VERSION ""

NS_ :

BS_:

BU_: VCU_LE CHUD_LE VKM_LE RCRM_LE VPM_LE EDI_LE V2V_LE TCP_LE CSM_LE UHP_Low_LE TouchPad_LE RSE_LE RSC_LE RSA_LE PDIM_LE OTIM_LE ICS_LE LVMPC_LE LVMNav_LE DVB_T_LE ONSTAR_LE HUD_LE IPC_LE RadioHead_LE CHM_LE Dummy_LE CGM_LE AMP_LE

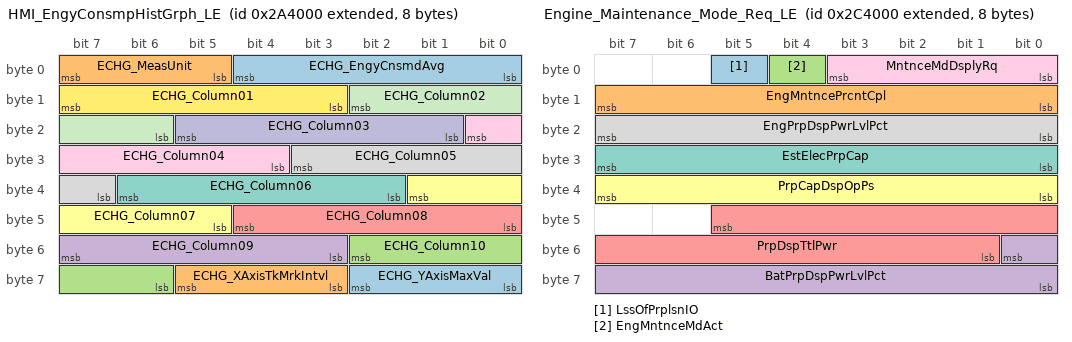
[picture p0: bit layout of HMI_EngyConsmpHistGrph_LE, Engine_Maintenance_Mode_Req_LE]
BO_ 2150252544 HMI_EngyConsmpHistGrph_LE: 8 CGM_LE
 SG_ ECHG_YAxisMaxVal : 58|3@0+ (1,0) [0|7] ""  VCU_LE,CSM_LE,RadioHead_LE
 SG_ ECHG_XAxisTkMrkIntvl : 61|3@0+ (1,0) [0|7] ""  VCU_LE,CSM_LE,RadioHead_LE
 SG_ ECHG_Column10 : 50|5@0+ (1,0) [0|31] ""  VCU_LE,CSM_LE,RadioHead_LE
 SG_ ECHG_Column09 : 55|5@0+ (1,0) [0|31] ""  VCU_LE,CSM_LE,RadioHead_LE
 SG_ ECHG_Column08 : 44|5@0+ (1,0) [0|31] ""  VCU_LE,CSM_LE,RadioHead_LE
 SG_ ECHG_Column07 : 33|5@0+ (1,0) [0|31] ""  VCU_LE,CSM_LE,RadioHead_LE
 SG_ ECHG_Column06 : 38|5@0+ (1,0) [0|31] ""  VCU_LE,CSM_LE,RadioHead_LE
 SG_ ECHG_Column05 : 27|5@0+ (1,0) [0|31] ""  VCU_LE,CSM_LE,RadioHead_LE
 SG_ ECHG_Column04 : 16|5@0+ (1,0) [0|31] ""  VCU_LE,CSM_LE,RadioHead_LE
 SG_ ECHG_Column03 : 21|5@0+ (1,0) [0|31] ""  VCU_LE,CSM_LE,RadioHead_LE
 SG_ ECHG_Column02 : 10|5@0+ (1,0) [0|31] ""  VCU_LE,CSM_LE,RadioHead_LE
 SG_ ECHG_Column01 : 15|5@0+ (1,0) [0|31] ""  VCU_LE,CSM_LE,RadioHead_LE
 SG_ ECHG_EngyCnsmdAvg : 4|5@0+ (1,0) [0|31] ""  VCU_LE,CSM_LE,RadioHead_LE
 SG_ ECHG_MeasUnit : 7|3@0+ (1,0) [0|7] ""  VCU_LE,CSM_LE,RadioHead_LE

BO_ 2150383616 Engine_Maintenance_Mode_Req_LE: 8 CGM_LE
 SG_ LssOfPrplsnIO : 5|1@0+ (1,0) [0|1] ""  VCU_LE,IPC_LE
 SG_ EngMntncePrcntCpl : 15|8@0+ (0.392157,0) [0|100.000035] "%"  VCU_LE,IPC_LE
 SG_ EngMntnceMdAct : 4|1@0+ (1,0) [0|1] ""  VCU_LE,IPC_LE
 SG_ BatPrpDspPwrLvlPct : 48|9@0- (0.392157,0) [-100.392192|100.000035] "%"  CSM_LE,VCU_LE,IPC_LE
 SG_ PrpDspTtlPwr : 45|13@0+ (0.5,-326.6) [-326.6|3768.9] "kW"  CSM_LE,RadioHead_LE,VCU_LE,IPC_LE
 SG_ PrpCapDspOpPs : 39|8@0+ (0.392157,0) [0|100.000035] "%"  CSM_LE,RadioHead_LE,VCU_LE,IPC_LE
 SG_ EstElecPrpCap : 31|8@0+ (0.392157,0) [0|100.000035] "%"  CSM_LE,ONSTAR_LE,VCU_LE,IPC_LE
 SG_ EngPrpDspPwrLvlPct : 23|8@0+ (0.392157,0) [0|100.000035] "%"  CSM_LE,RadioHead_LE,VCU_LE,IPC_LE
 SG_ MntnceMdDsplyRq : 3|4@0+ (1,0) [0|15] ""  VCU_LE,CSM_LE,RadioHead_LE

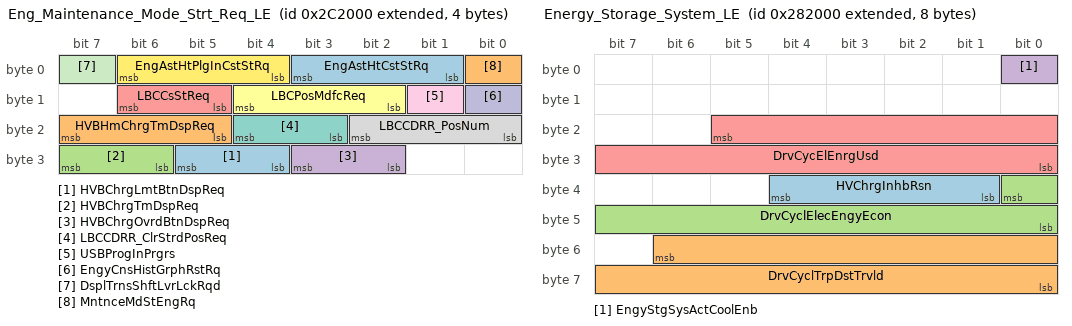
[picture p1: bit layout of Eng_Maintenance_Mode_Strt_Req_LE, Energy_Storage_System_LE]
BO_ 2150375424 Eng_Maintenance_Mode_Strt_Req_LE: 4 RadioHead_LE
 SG_ HVBChrgLmtBtnDspReq : 29|2@0+ (1,0) [0|3] ""  CGM_LE
 SG_ HVBHmChrgTmDspReq : 23|3@0+ (1,0) [0|7] ""  CGM_LE
 SG_ HVBChrgTmDspReq : 31|2@0+ (1,0) [0|3] ""  CGM_LE
 SG_ HVBChrgOvrdBtnDspReq : 27|2@0+ (1,0) [0|3] ""  CGM_LE
 SG_ LBCCsStReq : 14|2@0+ (1,0) [0|3] ""  CGM_LE
 SG_ LBCPosMdfcReq : 12|3@0+ (1,0) [0|7] ""  CGM_LE
 SG_ LBCCDRR_ClrStrdPosReq : 20|2@0+ (1,0) [0|3] ""  CGM_LE
 SG_ LBCCDRR_PosNum : 18|3@0+ (1,0) [0|7] ""  CGM_LE
 SG_ USBProgInPrgrs : 9|1@0+ (1,0) [0|1] ""  CGM_LE
 SG_ EngyCnsHistGrphRstRq : 8|1@0+ (1,0) [0|1] ""  CGM_LE
 SG_ DsplTrnsShftLvrLckRqd : 7|1@0+ (1,0) [0|1] ""  CGM_LE
 SG_ EngAstHtPlgInCstStRq : 6|3@0+ (1,0) [0|7] ""  CGM_LE
 SG_ EngAstHtCstStRq : 3|3@0+ (1,0) [0|7] ""  CGM_LE
 SG_ MntnceMdStEngRq : 0|1@0+ (1,0) [0|1] ""  CGM_LE

BO_ 2150113280 Energy_Storage_System_LE: 8 CGM_LE
 SG_ HVChrgInhbRsn : 36|4@0+ (1,0) [0|15] ""  VCU_LE,IPC_LE
 SG_ DrvCyclTrpDstTrvld : 54|15@0+ (0.1,0) [0|3276.7] "km"  CSM_LE,ONSTAR_LE,VCU_LE,IPC_LE
 SG_ DrvCyclElecEngyEcon : 32|9@0+ (0.1,0) [0|51.1] ""  CSM_LE,ONSTAR_LE,VCU_LE,IPC_LE
 SG_ EngyStgSysActCoolEnb : 0|1@0+ (1,0) [0|1] ""  IPC_LE,VCU_LE,CSM_LE,RadioHead_LE
 SG_ DrvCycElEnrgUsd : 21|14@0+ (0.36,0) [0|5897.88] "MJ"  CSM_LE,VCU_LE,RadioHead_LE

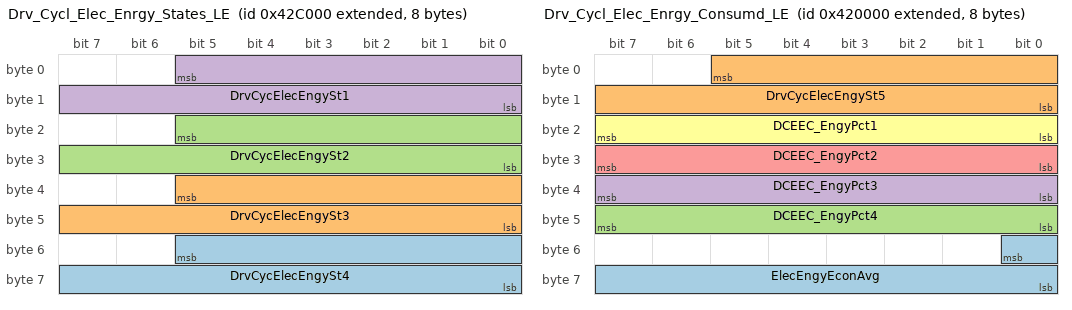
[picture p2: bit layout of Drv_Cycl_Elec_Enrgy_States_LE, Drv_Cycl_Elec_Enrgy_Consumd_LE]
BO_ 2151858176 Drv_Cycl_Elec_Enrgy_States_LE: 8 CGM_LE
 SG_ DrvCycElecEngySt4 : 53|14@0+ (0.36,0) [0|5897.88] "MJ"  VCU_LE,CSM_LE,RadioHead_LE
 SG_ DrvCycElecEngySt3 : 37|14@0+ (0.36,0) [0|5897.88] "MJ"  VCU_LE,CSM_LE,RadioHead_LE
 SG_ DrvCycElecEngySt2 : 21|14@0+ (0.36,0) [0|5897.88] "MJ"  VCU_LE,CSM_LE,RadioHead_LE
 SG_ DrvCycElecEngySt1 : 5|14@0+ (0.36,0) [0|5897.88] "MJ"  VCU_LE,CSM_LE,RadioHead_LE

BO_ 2151809024 Drv_Cycl_Elec_Enrgy_Consumd_LE: 8 CGM_LE
 SG_ ElecEngyEconAvg : 48|9@0+ (0.1,0) [0|51.1] ""  CSM_LE,ONSTAR_LE,VCU_LE,IPC_LE
 SG_ DrvCycElecEngySt5 : 5|14@0+ (0.36,0) [0|5897.88] "MJ"  VCU_LE,CSM_LE,RadioHead_LE
 SG_ DCEEC_EngyPct4 : 47|8@0+ (0.392157,0) [0|100.000035] "%"  VCU_LE,CSM_LE,RadioHead_LE
 SG_ DCEEC_EngyPct3 : 39|8@0+ (0.392157,0) [0|100.000035] "%"  VCU_LE,CSM_LE,RadioHead_LE
 SG_ DCEEC_EngyPct2 : 31|8@0+ (0.392157,0) [0|100.000035] "%"  VCU_LE,CSM_LE,RadioHead_LE
 SG_ DCEEC_EngyPct1 : 23|8@0+ (0.392157,0) [0|100.000035] "%"  VCU_LE,CSM_LE,RadioHead_LE

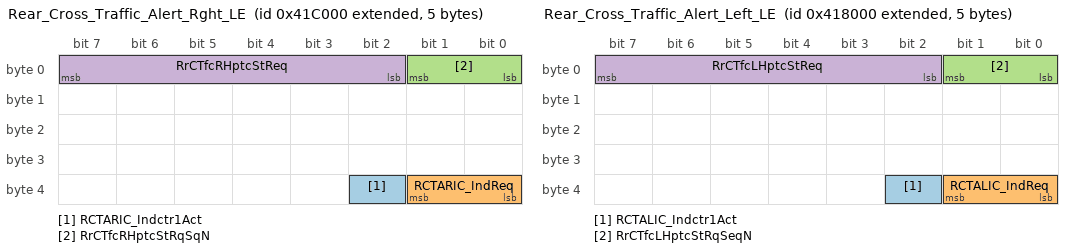
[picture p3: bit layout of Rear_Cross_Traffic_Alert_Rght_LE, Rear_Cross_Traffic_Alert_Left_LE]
BO_ 2151792640 Rear_Cross_Traffic_Alert_Rght_LE: 5 CGM_LE
 SG_ RCTARIC_Indctr1Act : 34|1@0+ (1,0) [0|1] ""  VPM_LE,VCU_LE,CSM_LE,RadioHead_LE
 SG_ RCTARIC_IndReq : 33|2@0+ (1,0) [0|3] ""  VPM_LE,VCU_LE,CSM_LE,RadioHead_LE
 SG_ RrCTfcRHptcStRqSqN : 1|2@0+ (1,0) [0|3] ""  VPM_LE,Dummy_LE
 SG_ RrCTfcRHptcStReq : 7|6@0+ (1,0) [0|63] ""  VPM_LE,Dummy_LE

BO_ 2151776256 Rear_Cross_Traffic_Alert_Left_LE: 5 CGM_LE
 SG_ RCTALIC_Indctr1Act : 34|1@0+ (1,0) [0|1] ""  VPM_LE,VCU_LE,CSM_LE,RadioHead_LE
 SG_ RCTALIC_IndReq : 33|2@0+ (1,0) [0|3] ""  VPM_LE,VCU_LE,CSM_LE,RadioHead_LE
 SG_ RrCTfcLHptcStRqSeqN : 1|2@0+ (1,0) [0|3] ""  VPM_LE,Dummy_LE
 SG_ RrCTfcLHptcStReq : 7|6@0+ (1,0) [0|63] ""  VPM_LE,Dummy_LE

BO_ 2151899136 PTO_Status_LE: 5 CGM_LE
 SG_ PTOAccelUpnBrkRelIO : 22|1@0+ (1,0) [0|1] ""  VCU_LE,IPC_LE
 SG_ PTOEngUpnBrkRelIO : 23|1@0+ (1,0) [0|1] ""  VCU_LE,IPC_LE
 SG_ PTOManTransInGrIO : 21|1@0+ (1,0) [0|1] ""  VCU_LE,IPC_LE
 SG_ PTOServIndOn : 31|1@0+ (1,0) [0|1] ""  VCU_LE,IPC_LE
 SG_ PTOVDM : 20|1@0+ (1,0) [0|1] ""  CSM_LE,RadioHead_LE,VCU_LE,IPC_LE
 SG_ PTOVDA : 19|1@0+ (1,0) [0|1] ""  CSM_LE,RadioHead_LE,VCU_LE,IPC_LE
 SG_ PTOTransInGearIO : 13|1@0+ (1,0) [0|1] ""  Dummy_LE,VCU_LE,IPC_LE
 SG_ PTOTpStpSpdCsStAvl : 10|1@0+ (1,0) [0|1] ""  VCU_LE,CSM_LE,RadioHead_LE
 SG_ PTOTpStSpdCsCrStVal : 26|3@0+ (1,0) [0|7] ""  VCU_LE,CSM_LE,RadioHead_LE
 SG_ PTOStdbySpdCsStAvl : 12|1@0+ (1,0) [0|1] ""  VCU_LE,CSM_LE,RadioHead_LE
 SG_ PTOStdbSpdCsCrStVal : 18|3@0+ (1,0) [0|7] ""  VCU_LE,CSM_LE,RadioHead_LE
 SG_ PTOSetPrkBrkIO : 14|1@0+ (1,0) [0|1] ""  VCU_LE,IPC_LE
 SG_ PTOSet2SpdCsStAvl : 9|1@0+ (1,0) [0|1] ""  VCU_LE,CSM_LE,RadioHead_LE
 SG_ PTOSet2SpdCsCrStVal : 39|4@0+ (1,0) [0|15] ""  VCU_LE,CSM_LE,RadioHead_LE
 SG_ PTOSet1SpdCsStAvl : 8|1@0+ (1,0) [0|1] ""  VCU_LE,CSM_LE,RadioHead_LE
 SG_ PTOSet1SpdCsCrStVal : 35|4@0+ (1,0) [0|15] ""  VCU_LE,CSM_LE,RadioHead_LE
 SG_ PTORelCltPedIO : 15|1@0+ (1,0) [0|1] ""  VCU_LE,IPC_LE
 SG_ PTORelBrkPedIO : 0|1@0+ (1,0) [0|1] ""  VCU_LE,IPC_LE
 SG_ PTORelAccPedIO : 1|1@0+ (1,0) [0|1] ""  VCU_LE,IPC_LE
 SG_ PTORedEngSpdIO : 2|1@0+ (1,0) [0|1] ""  VCU_LE,IPC_LE
 SG_ PTOPrsRelCltPedIO : 3|1@0+ (1,0) [0|1] ""  VCU_LE,IPC_LE
 SG_ PTOPrsRelBrkPedIO : 4|1@0+ (1,0) [0|1] ""  VCU_LE,IPC_LE
 SG_ PTOEngRnTmrCsStAvl : 11|1@0+ (1,0) [0|1] ""  VCU_LE,CSM_LE,RadioHead_LE
 SG_ PTOEnRnTmCsCrStVal : 30|4@0+ (1,0) [0|15] ""  VCU_LE,CSM_LE,RadioHead_LE
 SG_ PTOEngmntStatInd : 6|2@0+ (1,0) [0|3] ""  VCU_LE,IPC_LE
 SG_ PTODisengCrsCntlIO : 7|1@0+ (1,0) [0|1] ""  VCU_LE,IPC_LE

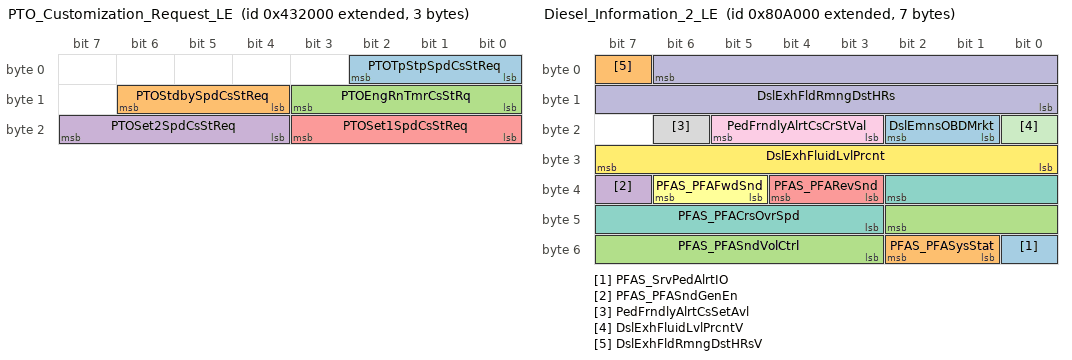
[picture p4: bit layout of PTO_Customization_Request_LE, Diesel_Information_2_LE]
BO_ 2151882752 PTO_Customization_Request_LE: 3 RadioHead_LE
 SG_ PTOTpStpSpdCsStReq : 2|3@0+ (1,0) [0|7] ""  CGM_LE
 SG_ PTOStdbySpdCsStReq : 14|3@0+ (1,0) [0|7] ""  CGM_LE
 SG_ PTOEngRnTmrCsStRq : 11|4@0+ (1,0) [0|15] ""  CGM_LE
 SG_ PTOSet2SpdCsStReq : 23|4@0+ (1,0) [0|15] ""  CGM_LE
 SG_ PTOSet1SpdCsStReq : 19|4@0+ (1,0) [0|15] ""  CGM_LE

BO_ 2155913216 Diesel_Information_2_LE: 7 CGM_LE
 SG_ PFAS_SrvPedAlrtIO : 48|1@0+ (1,0) [0|1] ""  VCU_LE,IPC_LE
 SG_ PFAS_PFASysStat : 50|2@0+ (1,0) [0|3] ""  VCU_LE,IPC_LE
 SG_ PFAS_PFASndVolCtrl : 42|8@0+ (0.392157,0) [0|100.000035] "%"  VCU_LE,IPC_LE
 SG_ PFAS_PFASndGenEn : 39|1@0+ (1,0) [0|1] ""  VCU_LE,IPC_LE
 SG_ PFAS_PFARevSnd : 36|2@0+ (1,0) [0|3] ""  VCU_LE,IPC_LE
 SG_ PFAS_PFAFwdSnd : 38|2@0+ (1,0) [0|3] ""  VCU_LE,IPC_LE
 SG_ PFAS_PFACrsOvrSpd : 34|8@0+ (1,0) [0|255] "km/h"  VCU_LE,IPC_LE
 SG_ PedFrndlyAlrtCsSetAvl : 22|1@0+ (1,0) [0|1] ""  VCU_LE,CSM_LE,RadioHead_LE
 SG_ PedFrndlyAlrtCsCrStVal : 21|3@0+ (1,0) [0|7] ""  VCU_LE,CSM_LE,RadioHead_LE
 SG_ DslExhFldRmngDstHRs : 6|15@0+ (2,0) [0|65534] "km"  CSM_LE,VCU_LE,IPC_LE
 SG_ DslExhFluidLvlPrcntV : 16|1@0+ (1,0) [0|1] ""  VCU_LE,IPC_LE
 SG_ DslExhFluidLvlPrcnt : 31|8@0+ (0.392157,0) [0|100.000035] "%"  VCU_LE,IPC_LE
 SG_ DslEmnsOBDMrkt : 18|2@0+ (1,0) [0|3] ""  VCU_LE,IPC_LE
 SG_ DslExhFldRmngDstHRsV : 7|1@0+ (1,0) [0|1] ""  CSM_LE,VCU_LE,IPC_LE

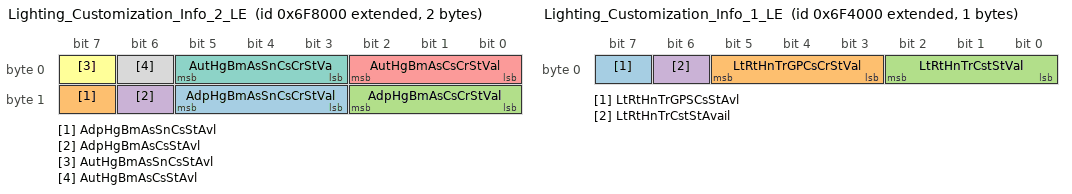
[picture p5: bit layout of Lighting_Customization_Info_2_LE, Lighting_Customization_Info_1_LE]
BO_ 2154790912 Lighting_Customization_Info_2_LE: 2 CGM_LE
 SG_ AdpHgBmAsSnCsCrStVal : 13|3@0+ (1,0) [0|7] ""  VCU_LE,CSM_LE,RadioHead_LE
 SG_ AdpHgBmAsSnCsStAvl : 15|1@0+ (1,0) [0|1] ""  VCU_LE,CSM_LE,RadioHead_LE
 SG_ AdpHgBmAsCsCrStVal : 10|3@0+ (1,0) [0|7] ""  VCU_LE,CSM_LE,RadioHead_LE
 SG_ AdpHgBmAsCsStAvl : 14|1@0+ (1,0) [0|1] ""  VCU_LE,CSM_LE,RadioHead_LE
 SG_ AutHgBmAsCsCrStVal : 2|3@0+ (1,0) [0|7] ""  VCU_LE,CSM_LE,RadioHead_LE
 SG_ AutHgBmAsSnCsStAvl : 7|1@0+ (1,0) [0|1] ""  VCU_LE,CSM_LE,RadioHead_LE
 SG_ AutHgBmAsSnCsCrStVa : 5|3@0+ (1,0) [0|7] ""  VCU_LE,CSM_LE,RadioHead_LE
 SG_ AutHgBmAsCsStAvl : 6|1@0+ (1,0) [0|1] ""  VCU_LE,CSM_LE,RadioHead_LE

BO_ 2154774528 Lighting_Customization_Info_1_LE: 1 CGM_LE
 SG_ LtRtHnTrGPSCsStAvl : 7|1@0+ (1,0) [0|1] ""  VCU_LE,CSM_LE,RadioHead_LE
 SG_ LtRtHnTrGPCsCrStVal : 5|3@0+ (1,0) [0|7] ""  VCU_LE,CSM_LE,RadioHead_LE
 SG_ LtRtHnTrCstStVal : 2|3@0+ (1,0) [0|7] ""  VCU_LE,CSM_LE,RadioHead_LE
 SG_ LtRtHnTrCstStAvail : 6|1@0+ (1,0) [0|1] ""  VCU_LE,CSM_LE,RadioHead_LE

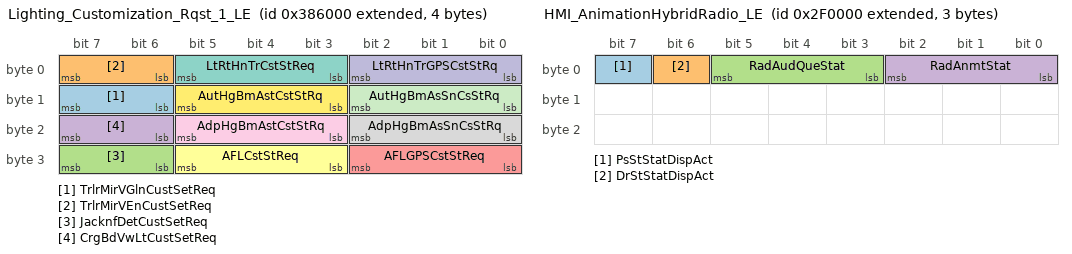
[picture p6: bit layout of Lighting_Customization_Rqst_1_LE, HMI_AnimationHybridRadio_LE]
BO_ 2151178240 Lighting_Customization_Rqst_1_LE: 4 RadioHead_LE
 SG_ TrlrMirVGlnCustSetReq : 15|2@0+ (1,0) [0|3] ""  CGM_LE,VPM_LE
 SG_ TrlrMirVEnCustSetReq : 7|2@0+ (1,0) [0|3] ""  CGM_LE,VPM_LE
 SG_ JacknfDetCustSetReq : 31|2@0+ (1,0) [0|3] ""  CGM_LE,VPM_LE
 SG_ CrgBdVwLtCustSetReq : 23|2@0+ (1,0) [0|3] ""  CGM_LE,VPM_LE
 SG_ AFLGPSCstStReq : 26|3@0+ (1,0) [0|7] ""  CGM_LE
 SG_ AFLCstStReq : 29|3@0+ (1,0) [0|7] ""  CGM_LE
 SG_ LtRtHnTrCstStReq : 5|3@0+ (1,0) [0|7] ""  CGM_LE
 SG_ AdpHgBmAsSnCsStRq : 18|3@0+ (1,0) [0|7] ""  CGM_LE
 SG_ AdpHgBmAstCstStRq : 21|3@0+ (1,0) [0|7] ""  CGM_LE
 SG_ LtRtHnTrGPSCstStRq : 2|3@0+ (1,0) [0|7] ""  CGM_LE
 SG_ AutHgBmAsSnCsStRq : 10|3@0+ (1,0) [0|7] ""  CGM_LE
 SG_ AutHgBmAstCstStRq : 13|3@0+ (1,0) [0|7] ""  CGM_LE

BO_ 2149728256 Charging_Sys_Trans_Shift_Lock_LE: 5 CGM_LE
 SG_ PrtyChrgStPnt : 38|7@0+ (1,0) [0|127] ""  CSM_LE,RadioHead_LE,VCU_LE,IPC_LE
 SG_ PrtyChrgActIO : 3|1@0+ (1,0) [0|1] ""  CSM_LE,VCU_LE,IPC_LE
 SG_ PrtyChrgAct : 4|1@0+ (1,0) [0|1] ""  TCP_LE,ONSTAR_LE,VCU_LE,CSM_LE,RadioHead_LE
 SG_ EngAstHtPlgInCsStAvl : 31|1@0+ (1,0) [0|1] ""  VCU_LE,CSM_LE,RadioHead_LE
 SG_ EngAstHtPlgInCsCrStVl : 30|3@0+ (1,0) [0|7] ""  VCU_LE,CSM_LE,RadioHead_LE
 SG_ EngAstHtCsStAvl : 27|1@0+ (1,0) [0|1] ""  VCU_LE,CSM_LE,RadioHead_LE
 SG_ EngAstHtCsCrStVal : 26|3@0+ (1,0) [0|7] ""  VCU_LE,CSM_LE,RadioHead_LE
 SG_ HghVltgPropState : 7|3@0+ (1,0) [0|7] ""  CSM_LE,RadioHead_LE,VCU_LE,IPC_LE
 SG_ HVChrgPwrLvl : 22|3@0+ (1,0) [0|7] ""  TCP_LE,ONSTAR_LE,CSM_LE,RadioHead_LE,VCU_LE,IPC_LE
 SG_ ChrgPrtDrStat : 2|2@0+ (1,0) [0|3] ""  TCP_LE,ONSTAR_LE,VCU_LE,IPC_LE
 SG_ ChgCdTfAlCzStAvbl : 11|1@0+ (1,0) [0|1] ""  VCU_LE,CSM_LE,RadioHead_LE
 SG_ ChgCdTfAlCzCrStVal : 10|3@0+ (1,0) [0|7] ""  VCU_LE,CSM_LE,RadioHead_LE
 SG_ ChrgSysTrnsShftLckRq : 0|1@0+ (1,0) [0|1] ""  CSM_LE,VCU_LE,RadioHead_LE
 SG_ ChgPwLsAlCzStAvbl : 15|1@0+ (1,0) [0|1] ""  VCU_LE,CSM_LE,RadioHead_LE
 SG_ ChgPwLsAlCzCrStVal : 14|3@0+ (1,0) [0|7] ""  VCU_LE,CSM_LE,RadioHead_LE
 SG_ ChgSysAudInCsStAvl : 19|1@0+ (1,0) [0|1] ""  VCU_LE,CSM_LE,RadioHead_LE
 SG_ ChgSyAudInCsCrStVa : 18|3@0+ (1,0) [0|7] ""  VCU_LE,CSM_LE,RadioHead_LE

BO_ 2156265472 High_Volt_Bat_Time_Bsd_Req_LE: 8 RadioHead_LE
 SG_ OffBrdHVCVehCsChRq : 35|1@0+ (1,0) [0|1] ""  CGM_LE
 SG_ PrtyChrgRq : 7|2@0+ (1,0) [0|3] ""  CGM_LE
 SG_ HVBTBRCSR_RtChSlStReq : 42|3@0+ (1,0) [0|7] ""  CGM_LE
 SG_ HVBTBRCSR_RtChSlRtStReq : 46|4@0+ (1,0) [0|15] ""  CGM_LE
 SG_ HVBTBRCSR_RtChSsnStReq : 50|2@0+ (1,0) [0|3] ""  CGM_LE
 SG_ HVBTBRCSR_RtChMHStReq : 48|6@0+ (1,0) [0|63] "min"  CGM_LE
 SG_ HVBTBRCSR_RtChHStReq : 55|5@0+ (1,0) [0|31] "hr"  CGM_LE
 SG_ HVBTBRCSR_RtChDStReq : 34|4@0+ (1,0) [0|15] ""  CGM_LE
 SG_ HVBTBRCSR_RtChSlTbRwReq : 58|3@0+ (1,0) [0|7] "rows"  CGM_LE
 SG_ HVBTBDCSRQ_DlChSlStReq : 19|4@0+ (1,0) [0|15] ""  CGM_LE
 SG_ HVBTBDCSRQ_DlChSsnStReq : 31|2@0+ (1,0) [0|3] ""  CGM_LE
 SG_ HVBTBDCSRQ_DlChMHStReq : 29|6@0+ (1,0) [0|63] "min"  CGM_LE
 SG_ HVBTBDCSRQ_DlChHStReq : 12|5@0+ (1,0) [0|31] "hr"  CGM_LE
 SG_ HVBTBDCSRQ_DlChDStReq : 23|4@0+ (1,0) [0|15] ""  CGM_LE
 SG_ ChgPwLsAlCzStRq : 5|3@0+ (1,0) [0|7] ""  CGM_LE
 SG_ ChgCdTfAlCzStRq : 2|3@0+ (1,0) [0|7] ""  CGM_LE
 SG_ ChgSysAudInCsStReq : 15|3@0+ (1,0) [0|7] ""  CGM_LE
 SG_ EngyUsgScrnMeasUtStat : 39|4@0+ (1,0) [0|15] ""  CGM_LE

BO_ 2150563840 HMI_AnimationHybridRadio_LE: 3 RadioHead_LE
 SG_ PsStStatDispAct : 7|1@0+ (1,0) [0|1] ""  CGM_LE,Dummy_LE
 SG_ DrStStatDispAct : 6|1@0+ (1,0) [0|1] ""  CGM_LE,Dummy_LE
 SG_ RadAudQueStat : 5|3@0+ (1,0) [0|7] ""  CGM_LE,VCU_LE,IPC_LE
 SG_ RadAnmtStat : 2|3@0+ (1,0) [0|7] ""  CGM_LE,VCU_LE,IPC_LE

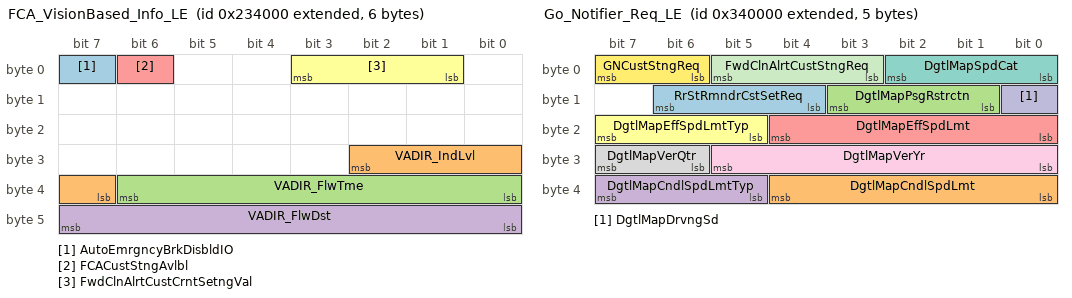
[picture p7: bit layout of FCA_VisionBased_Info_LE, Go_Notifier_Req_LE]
BO_ 2149793792 FCA_VisionBased_Info_LE: 6 CGM_LE
 SG_ AutoEmrgncyBrkDisbldIO : 7|1@0+ (1,0) [0|1] ""  VCU_LE,IPC_LE
 SG_ VADIR_IndLvl : 26|4@0+ (1,0) [0|15] ""  CSM_LE,RadioHead_LE,VCU_LE,IPC_LE
 SG_ VADIR_FlwTme : 38|7@0+ (0.1,0) [0|12.7] "s"  CSM_LE,RadioHead_LE,VCU_LE,IPC_LE
 SG_ VADIR_FlwDst : 47|8@0+ (1,0) [0|255] "m"  CSM_LE,RadioHead_LE,VCU_LE,IPC_LE
 SG_ FCACustStngAvlbl : 6|1@0+ (1,0) [0|1] ""  VCU_LE,CSM_LE,RadioHead_LE
 SG_ FwdClnAlrtCustCrntSetngVal : 3|3@0+ (1,0) [0|7] ""  VCU_LE,CSM_LE,RadioHead_LE

BO_ 2150891520 Go_Notifier_Req_LE: 5 RadioHead_LE
 SG_ RrStRmndrCstSetReq : 14|3@0+ (1,0) [0|7] ""  CGM_LE
 SG_ DgtlMapCndlSpdLmt : 36|5@0+ (1,0) [0|31] ""  CGM_LE
 SG_ DgtlMapPsgRstrctn : 11|3@0+ (1,0) [0|7] ""  CGM_LE
 SG_ DgtlMapCndlSpdLmtTyp : 39|3@0+ (1,0) [0|7] ""  CGM_LE
 SG_ DgtlMapEffSpdLmt : 20|5@0+ (1,0) [0|31] ""  CGM_LE
 SG_ DgtlMapEffSpdLmtTyp : 23|3@0+ (1,0) [0|7] ""  CGM_LE
 SG_ DgtlMapSpdCat : 2|3@0+ (1,0) [0|7] ""  CGM_LE
 SG_ DgtlMapVerQtr : 31|2@0+ (1,0) [0|3] ""  CGM_LE
 SG_ DgtlMapVerYr : 29|6@0+ (1,0) [0|63] ""  CGM_LE
 SG_ DgtlMapDrvngSd : 8|1@0+ (1,0) [0|1] ""  CGM_LE
 SG_ FwdClnAlrtCustStngReq : 5|3@0+ (1,0) [0|7] ""  CGM_LE
 SG_ GNCustStngReq : 7|2@0+ (1,0) [0|3] ""  CGM_LE

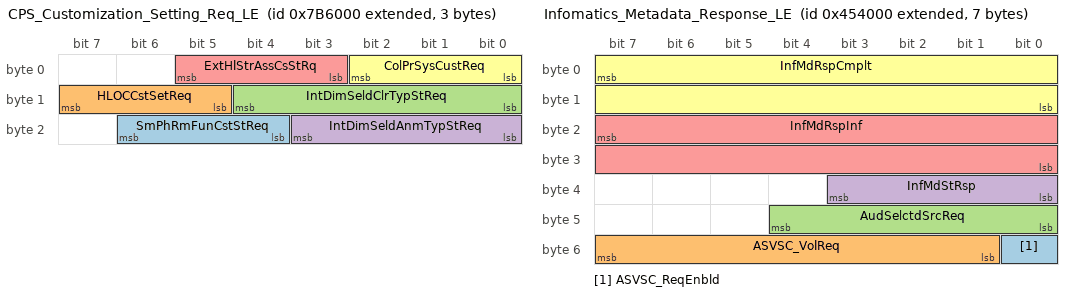
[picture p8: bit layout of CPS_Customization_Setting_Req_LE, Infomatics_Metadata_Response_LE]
BO_ 2155569152 CPS_Customization_Setting_Req_LE: 3 RadioHead_LE
 SG_ SmPhRmFunCstStReq : 22|3@0+ (1,0) [0|7] ""  CGM_LE
 SG_ HLOCCstSetReq : 15|3@0+ (1,0) [0|7] ""  CGM_LE
 SG_ IntDimSeldClrTypStReq : 12|5@0+ (1,0) [0|31] ""  CGM_LE
 SG_ IntDimSeldAnmTypStReq : 19|4@0+ (1,0) [0|15] ""  CGM_LE
 SG_ ExtHlStrAssCsStRq : 5|3@0+ (1,0) [0|7] ""  CGM_LE
 SG_ ColPrSysCustReq : 2|3@0+ (1,0) [0|7] ""  CGM_LE

BO_ 2152022016 Infomatics_Metadata_Response_LE: 7 ONSTAR_LE
 SG_ ASVSC_ReqEnbld : 48|1@0+ (1,0) [0|1] ""  VCU_LE,CSM_LE,RadioHead_LE
 SG_ ASVSC_VolReq : 55|7@0+ (0.787402,0) [0|100.000054] ""  VCU_LE,CSM_LE,RadioHead_LE
 SG_ AudSelctdSrcReq : 44|5@0+ (1,0) [0|31] ""  VCU_LE,CSM_LE,RadioHead_LE
 SG_ InfMdStRsp : 35|4@0+ (1,0) [0|15] ""  VCU_LE,RadioHead_LE
 SG_ InfMdRspInf : 23|16@0+ (1,0) [0|65535] ""  VCU_LE,RadioHead_LE
 SG_ InfMdRspCmplt : 7|16@0+ (1,0) [0|65535] ""  VCU_LE,RadioHead_LE

BO_ 2152005632 Infomatics_Request_Payload_LE: 8 RadioHead_LE
 SG_ InfMdRqstPld : 7|64@0+ (1,0) [0|1.84467440737096E+019] ""  ONSTAR_LE

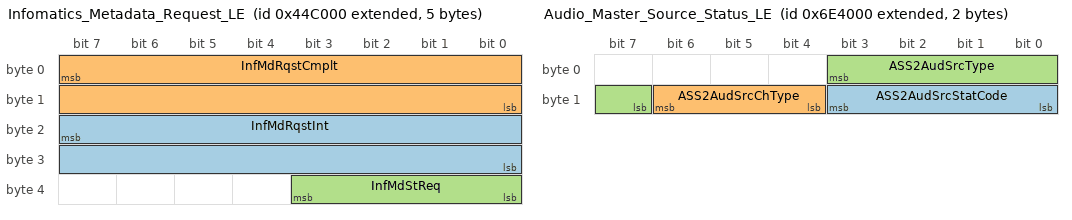
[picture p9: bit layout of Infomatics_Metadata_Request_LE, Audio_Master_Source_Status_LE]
BO_ 2151989248 Infomatics_Metadata_Request_LE: 5 RadioHead_LE
 SG_ InfMdRqstInt : 23|16@0+ (1,0) [0|65535] ""  ONSTAR_LE
 SG_ InfMdRqstCmplt : 7|16@0+ (1,0) [0|65535] ""  ONSTAR_LE
 SG_ InfMdStReq : 35|4@0+ (1,0) [0|15] ""  ONSTAR_LE

BO_ 2154708992 Audio_Master_Source_Status_LE: 2 RadioHead_LE
 SG_ ASS2AudSrcStatCode : 11|4@0+ (1,0) [0|15] ""  CGM_LE
 SG_ ASS2AudSrcChType : 14|3@0+ (1,0) [0|7] ""  CGM_LE
 SG_ ASS2AudSrcType : 3|5@0+ (1,0) [0|31] ""  CGM_LE

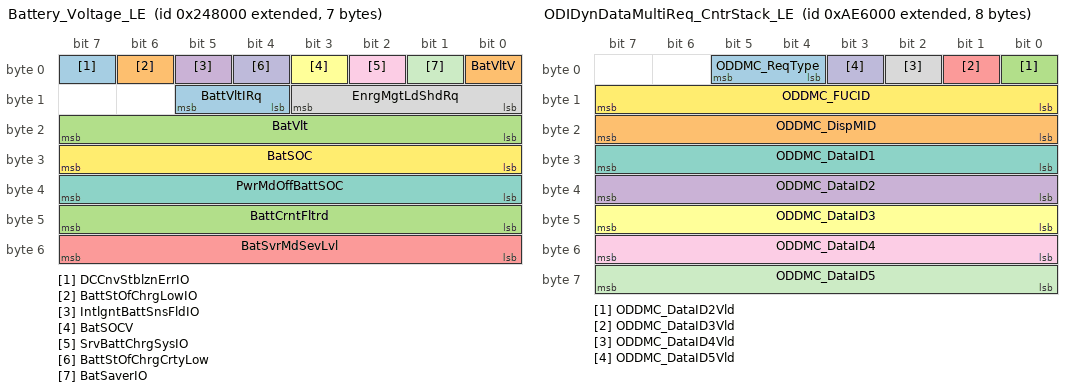
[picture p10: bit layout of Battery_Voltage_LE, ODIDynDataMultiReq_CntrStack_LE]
BO_ 2149875712 Battery_Voltage_LE: 7 CGM_LE
 SG_ DCCnvStblznErrIO : 7|1@0+ (1,0) [0|1] ""  VCU_LE,IPC_LE
 SG_ BattStOfChrgLowIO : 6|1@0+ (1,0) [0|1] ""  CSM_LE,LVMNav_LE,RadioHead_LE,VCU_LE,IPC_LE
 SG_ BattCrntFltrd : 47|8@0- (0.5,0) [-64|63.5] "A"  CSM_LE,VCU_LE,RadioHead_LE
 SG_ IntlgntBattSnsFldIO : 5|1@0+ (1,0) [0|1] ""  CSM_LE,RadioHead_LE,VCU_LE,IPC_LE
 SG_ BatSvrMdSevLvl : 55|8@0+ (1,0) [0|255] ""  TCP_LE,CSM_LE,ONSTAR_LE,VCU_LE,RadioHead_LE
 SG_ BatSOCV : 3|1@0+ (1,0) [0|1] ""  TCP_LE,CSM_LE,ONSTAR_LE,VCU_LE,RadioHead_LE
 SG_ PwrMdOffBattSOC : 39|8@0+ (0.392157,0) [0|100.000035] "%"  CSM_LE,VCU_LE,RadioHead_LE,TCP_LE,ONSTAR_LE
 SG_ EnrgMgtLdShdRq : 11|4@0+ (1,0) [0|15] ""  CSM_LE,TCP_LE,ONSTAR_LE,VCU_LE,RadioHead_LE
 SG_ SrvBattChrgSysIO : 2|1@0+ (1,0) [0|1] ""  CSM_LE,TCP_LE,ONSTAR_LE,RadioHead_LE,VCU_LE,IPC_LE
 SG_ BattStOfChrgCrtyLow : 4|1@0+ (1,0) [0|1] ""  VKM_LE,CSM_LE,VCU_LE,RadioHead_LE,TCP_LE,ONSTAR_LE
 SG_ BatSaverIO : 1|1@0+ (1,0) [0|1] ""  TCP_LE,CSM_LE,ONSTAR_LE,RadioHead_LE,VCU_LE,IPC_LE
 SG_ BatSOC : 31|8@0+ (0.392157,0) [0|100.000035] "%"  VKM_LE,TCP_LE,CSM_LE,ONSTAR_LE,VCU_LE,RadioHead_LE
 SG_ BattVltIRq : 13|2@0+ (1,0) [0|3] ""  CSM_LE,RadioHead_LE,VCU_LE,IPC_LE
 SG_ BatVltV : 0|1@0+ (1,0) [0|1] ""  VPM_LE,V2V_LE,TCP_LE,CSM_LE,ONSTAR_LE,LVMNav_LE,RadioHead_LE,VCU_LE,IPC_LE
 SG_ BatVlt : 23|8@0+ (0.1,3) [3|28.5] "volts"  VPM_LE,V2V_LE,TCP_LE,CSM_LE,ONSTAR_LE,LVMNav_LE,RadioHead_LE,VCU_LE,IPC_LE

BO_ 1613 USDT_Resp_From_UHP_ONS_LE: 8 ONSTAR_LE
 SG_ DgnInf : 7|64@0+ (1,0) [0|1.84467440737096E+019] ""  CSM_LE,CGM_LE

BO_ 1581 VNMF_LE_62D_UHP_ONS: 8 ONSTAR_LE
 SG_ VectraSpcNWMgtD : 7|64@0+ (1,0) [0|1.84467440737096E+019] ""  RCRM_LE,V2V_LE,VKM_LE,RSC_LE,RSE_LE,RSA_LE,PDIM_LE,OTIM_LE,CHUD_LE,LVMPC_LE,IPC_LE,ICS_LE,VPM_LE,HUD_LE,TouchPad_LE,DVB_T_LE,VCU_LE,CSM_LE,RadioHead_LE,CHM_LE,AMP_LE,CGM_LE

BO_ 1357 UUDT_Resp_From_UHP_ONS_LE: 8 ONSTAR_LE
 SG_ DgnInf_LS54D : 7|64@0+ (1,0) [0|1.84467440737096E+019] ""  CSM_LE,CGM_LE

BO_ 2159222784 ODI_PDIM_2_CenterStack_LE: 8 PDIM_LE
 SG_ ODI_PDIM2CntrStck : 7|64@0+ (1,0) [0|1.84467440737096E+019] ""  CSM_LE,VCU_LE,RadioHead_LE

BO_ 2159214592 ODI_CenterStack_2_PDIM_LE: 8 RadioHead_LE
 SG_ ODI_CntrStck2PDIM : 7|64@0+ (1,0) [0|1.84467440737096E+019] ""  PDIM_LE

BO_ 2158911488 ODIDynDataMultiReq_CntrStack_LE: 8 RadioHead_LE
 SG_ ODDMC_ReqType : 5|2@0+ (1,0) [0|3] ""  CGM_LE,VCU_LE,IPC_LE,PDIM_LE,UHP_Low_LE,ONSTAR_LE,TCP_LE
 SG_ ODDMC_DispMID : 23|8@0+ (1,0) [0|255] ""  CGM_LE,VCU_LE,IPC_LE,PDIM_LE,UHP_Low_LE,ONSTAR_LE,TCP_LE
 SG_ ODDMC_DataID2Vld : 0|1@0+ (1,0) [0|1] ""  CGM_LE,VCU_LE,IPC_LE,PDIM_LE,UHP_Low_LE,ONSTAR_LE,TCP_LE
 SG_ ODDMC_DataID2 : 39|8@0+ (1,0) [0|255] ""  CGM_LE,VCU_LE,IPC_LE,PDIM_LE,UHP_Low_LE,ONSTAR_LE,TCP_LE
 SG_ ODDMC_DataID3Vld : 1|1@0+ (1,0) [0|1] ""  CGM_LE,VCU_LE,IPC_LE,PDIM_LE,UHP_Low_LE,ONSTAR_LE,TCP_LE
 SG_ ODDMC_DataID3 : 47|8@0+ (1,0) [0|255] ""  CGM_LE,VCU_LE,IPC_LE,PDIM_LE,UHP_Low_LE,ONSTAR_LE,TCP_LE
 SG_ ODDMC_DataID1 : 31|8@0+ (1,0) [0|255] ""  CGM_LE,VCU_LE,IPC_LE,PDIM_LE,UHP_Low_LE,ONSTAR_LE,TCP_LE
 SG_ ODDMC_DataID4Vld : 2|1@0+ (1,0) [0|1] ""  CGM_LE,VCU_LE,IPC_LE,PDIM_LE,UHP_Low_LE,ONSTAR_LE,TCP_LE
 SG_ ODDMC_DataID4 : 55|8@0+ (1,0) [0|255] ""  CGM_LE,VCU_LE,IPC_LE,PDIM_LE,UHP_Low_LE,ONSTAR_LE,TCP_LE
 SG_ ODDMC_DataID5Vld : 3|1@0+ (1,0) [0|1] ""  CGM_LE,VCU_LE,IPC_LE,PDIM_LE,UHP_Low_LE,ONSTAR_LE,TCP_LE
 SG_ ODDMC_DataID5 : 63|8@0+ (1,0) [0|255] ""  CGM_LE,VCU_LE,IPC_LE,PDIM_LE,UHP_Low_LE,ONSTAR_LE,TCP_LE
 SG_ ODDMC_FUCID : 15|8@0+ (1,0) [0|255] ""  CGM_LE,VCU_LE,IPC_LE,PDIM_LE,UHP_Low_LE,ONSTAR_LE,TCP_LE

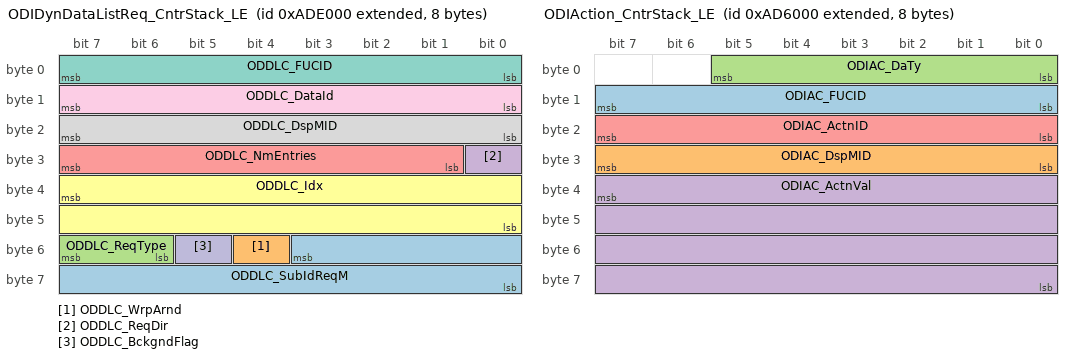
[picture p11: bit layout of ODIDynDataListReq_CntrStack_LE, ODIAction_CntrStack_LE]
BO_ 2158878720 ODIDynDataListReq_CntrStack_LE: 8 RadioHead_LE
 SG_ ODDLC_SubIdReqM : 51|12@0+ (1,0) [0|4095] ""  CGM_LE,PDIM_LE,UHP_Low_LE,ONSTAR_LE,TCP_LE
 SG_ ODDLC_WrpArnd : 52|1@0+ (1,0) [0|1] ""  CGM_LE,PDIM_LE,UHP_Low_LE,ONSTAR_LE,TCP_LE
 SG_ ODDLC_ReqType : 55|2@0+ (1,0) [0|3] ""  CGM_LE,PDIM_LE,UHP_Low_LE,ONSTAR_LE,TCP_LE
 SG_ ODDLC_ReqDir : 24|1@0+ (1,0) [0|1] ""  CGM_LE,PDIM_LE,UHP_Low_LE,ONSTAR_LE,TCP_LE
 SG_ ODDLC_NmEntries : 31|7@0+ (1,0) [0|127] ""  CGM_LE,PDIM_LE,UHP_Low_LE,ONSTAR_LE,TCP_LE
 SG_ ODDLC_Idx : 39|16@0+ (1,0) [0|65535] ""  CGM_LE,PDIM_LE,UHP_Low_LE,ONSTAR_LE,TCP_LE
 SG_ ODDLC_FUCID : 7|8@0+ (1,0) [0|255] ""  CGM_LE,PDIM_LE,UHP_Low_LE,ONSTAR_LE,TCP_LE
 SG_ ODDLC_DspMID : 23|8@0+ (1,0) [0|255] ""  CGM_LE,PDIM_LE,UHP_Low_LE,ONSTAR_LE,TCP_LE
 SG_ ODDLC_DataId : 15|8@0+ (1,0) [0|255] ""  CGM_LE,PDIM_LE,UHP_Low_LE,ONSTAR_LE,TCP_LE
 SG_ ODDLC_BckgndFlag : 53|1@0+ (1,0) [0|1] ""  CGM_LE,PDIM_LE,UHP_Low_LE,ONSTAR_LE,TCP_LE

BO_ 2158845952 ODIAction_CntrStack_LE: 8 RadioHead_LE
 SG_ ODIAC_FUCID : 15|8@0+ (1,0) [0|255] ""  CGM_LE,VCU_LE,IPC_LE,PDIM_LE,UHP_Low_LE,ONSTAR_LE,TCP_LE
 SG_ ODIAC_DspMID : 31|8@0+ (1,0) [0|255] ""  CGM_LE,VCU_LE,IPC_LE,PDIM_LE,UHP_Low_LE,ONSTAR_LE,TCP_LE
 SG_ ODIAC_DaTy : 5|6@0+ (1,0) [0|63] ""  CGM_LE,VCU_LE,IPC_LE,PDIM_LE,UHP_Low_LE,ONSTAR_LE,TCP_LE
 SG_ ODIAC_ActnVal : 39|32@0+ (1,0) [0|4294967295] ""  CGM_LE,VCU_LE,IPC_LE,PDIM_LE,UHP_Low_LE,ONSTAR_LE,TCP_LE
 SG_ ODIAC_ActnID : 23|8@0+ (1,0) [0|255] ""  CGM_LE,VCU_LE,IPC_LE,PDIM_LE,UHP_Low_LE,ONSTAR_LE,TCP_LE

BO_ 2151079936 PDIM_Status_LE: 1 PDIM_LE
 SG_ PDIMPrsnt : 0|1@0+ (1,0) [0|1] ""  CSM_LE,VCU_LE,RadioHead_LE

BO_ 1608 USDT_Resp_From_PDIM_LE: 8 PDIM_LE
 SG_ DgnInf : 7|64@0+ (1,0) [0|1.84467440737096E+019] ""  CSM_LE,CGM_LE,TCP_LE,ONSTAR_LE

BO_ 1576 VNMF_LE_628_PDIM: 8 PDIM_LE
 SG_ VectraSpcNWMgtD : 7|64@0+ (1,0) [0|1.84467440737096E+019] ""  RCRM_LE,V2V_LE,TCP_LE,UHP_Low_LE,LVMNav_LE,ONSTAR_LE,VKM_LE,RSC_LE,RSE_LE,RSA_LE,OTIM_LE,CHUD_LE,LVMPC_LE,IPC_LE,ICS_LE,VPM_LE,HUD_LE,TouchPad_LE,DVB_T_LE,VCU_LE,CSM_LE,RadioHead_LE,CHM_LE,AMP_LE,CGM_LE

BO_ 1352 UUDT_Resp_From_PDIM_LE: 8 PDIM_LE
 SG_ DgnInf_LS548 : 7|64@0+ (1,0) [0|1.84467440737096E+019] ""  CSM_LE,CGM_LE,TCP_LE,ONSTAR_LE

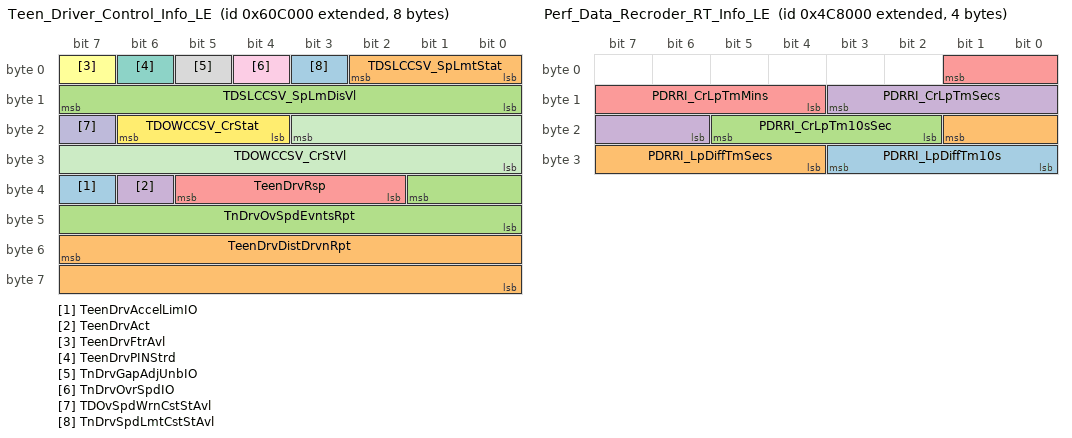
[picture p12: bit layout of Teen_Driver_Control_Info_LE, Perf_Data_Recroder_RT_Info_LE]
BO_ 2153824256 Teen_Driver_Control_Info_LE: 8 CGM_LE
 SG_ TeenDrvAccelLimIO : 39|1@0+ (1,0) [0|1] ""  VCU_LE,IPC_LE
 SG_ TeenDrvDistDrvnRpt : 55|16@0+ (1,0) [0|65535] "km"  VCU_LE,CSM_LE,RadioHead_LE
 SG_ TnDrvOvSpdEvntsRpt : 33|10@0+ (1,0) [0|1023] "counts"  VCU_LE,CSM_LE,RadioHead_LE
 SG_ TeenDrvAct : 38|1@0+ (1,0) [0|1] ""  V2V_LE,LVMPC_LE,CSM_LE,RadioHead_LE,VCU_LE,IPC_LE
 SG_ TeenDrvRsp : 37|4@0+ (1,0) [0|15] ""  VCU_LE,CSM_LE,RadioHead_LE
 SG_ TeenDrvFtrAvl : 7|1@0+ (1,0) [0|1] ""  VCU_LE,CSM_LE,RadioHead_LE
 SG_ TeenDrvPINStrd : 6|1@0+ (1,0) [0|1] ""  VCU_LE,CSM_LE,RadioHead_LE
 SG_ TnDrvGapAdjUnbIO : 5|1@0+ (1,0) [0|1] ""  VCU_LE,IPC_LE
 SG_ TnDrvOvrSpdIO : 4|1@0+ (1,0) [0|1] ""  VCU_LE,IPC_LE
 SG_ TDOvSpdWrnCstStAvl : 23|1@0+ (1,0) [0|1] ""  VCU_LE,CSM_LE,RadioHead_LE
 SG_ TDOWCCSV_CrStVl : 19|12@0+ (0.0625,0) [0|255.9375] "km/h"  CSM_LE,RadioHead_LE,VCU_LE,IPC_LE
 SG_ TDOWCCSV_CrStat : 22|3@0+ (1,0) [0|7] ""  CSM_LE,RadioHead_LE,VCU_LE,IPC_LE
 SG_ TnDrvSpdLmtCstStAvl : 3|1@0+ (1,0) [0|1] ""  VCU_LE,CSM_LE,RadioHead_LE
 SG_ TDSLCCSV_SpLmtStat : 2|3@0+ (1,0) [0|7] ""  CSM_LE,RadioHead_LE,VCU_LE,IPC_LE
 SG_ TDSLCCSV_SpLmDisVl : 15|8@0+ (2,0) [0|510] "km/h"  CSM_LE,RadioHead_LE,VCU_LE,IPC_LE

BO_ 2151907328 Steering_Wheel_Control_Swichs_LE: 1 IPC_LE
 SG_ StrgWhlUnit1SwStat : 3|4@0+ (1,0) [0|15] ""  EDI_LE,CSM_LE,CGM_LE,LVMPC_LE,VCU_LE,RadioHead_LE
 SG_ StrgWhlUnit2SwStat : 7|4@0+ (1,0) [0|15] ""  EDI_LE,CSM_LE,CGM_LE,LVMPC_LE,VCU_LE,RadioHead_LE

BO_ 2162982912 VIN_Digits_10_to_17_LE: 8 CGM_LE
 SG_ VehIdNmDig10_17 : 7|64@0+ (1,0) [0|1] ""  RSE_LE,VKM_LE,VPM_LE,EDI_LE,TCP_LE,CSM_LE,ONSTAR_LE,IPC_LE,LVMPC_LE,LVMNav_LE,VCU_LE,RadioHead_LE

BO_ 2162966528 VIN_Digits_2_to_9_LE: 8 CGM_LE
 SG_ VehIdNmDig2_9 : 7|64@0+ (1,0) [0|1] ""  RSE_LE,VKM_LE,VPM_LE,EDI_LE,TCP_LE,CSM_LE,IPC_LE,LVMPC_LE,ONSTAR_LE,VCU_LE,RadioHead_LE

BO_ 2152497152 Perf_Data_Recroder_RT_Info_LE: 4 LVMPC_LE
 SG_ PDRRI_LpDiffTm10s : 27|4@0+ (0.1,0) [0|1.5] "sec"  VCU_LE,IPC_LE
 SG_ PDRRI_LpDiffTmSecs : 17|6@0+ (1,0) [0|63] "sec"  VCU_LE,IPC_LE
 SG_ PDRRI_CrLpTm10sSec : 21|4@0+ (0.1,0) [0|1.5] "sec"  VCU_LE,IPC_LE
 SG_ PDRRI_CrLpTmSecs : 11|6@0+ (1,0) [0|63] ""  VCU_LE,IPC_LE
 SG_ PDRRI_CrLpTmMins : 1|6@0+ (1,0) [0|63] "min"  VCU_LE,IPC_LE

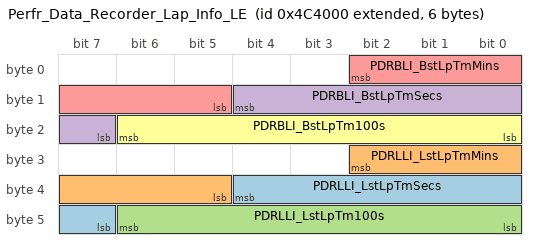
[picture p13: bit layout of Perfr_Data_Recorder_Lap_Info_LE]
BO_ 2152480768 Perfr_Data_Recorder_Lap_Info_LE: 6 LVMPC_LE
 SG_ PDRLLI_LstLpTmSecs : 36|6@0+ (1,0) [0|63] "sec"  VCU_LE,IPC_LE
 SG_ PDRLLI_LstLpTmMins : 26|6@0+ (1,0) [0|63] "min"  VCU_LE,IPC_LE
 SG_ PDRLLI_LstLpTm100s : 46|7@0+ (0.01,0) [0|1.27] "sec"  VCU_LE,IPC_LE
 SG_ PDRBLI_BstLpTmSecs : 12|6@0+ (1,0) [0|63] "sec"  VCU_LE,IPC_LE
 SG_ PDRBLI_BstLpTmMins : 2|6@0+ (1,0) [0|63] "min"  VCU_LE,IPC_LE
 SG_ PDRBLI_BstLpTm100s : 22|7@0+ (0.01,0) [0|1.27] "sec"  VCU_LE,IPC_LE

BO_ 1610 USDT_Resp_From_LVMPC_LE: 8 LVMPC_LE
 SG_ DgnInf : 7|64@0+ (1,0) [0|1.84467440737096E+019] ""  CSM_LE,CGM_LE,TCP_LE,ONSTAR_LE

BO_ 1578 VNMF_LE_62A_LVMPC: 8 LVMPC_LE
 SG_ VectraSpcNWMgtD : 7|64@0+ (1,0) [0|1.84467440737096E+019] ""  RCRM_LE,V2V_LE,TCP_LE,UHP_Low_LE,LVMNav_LE,ONSTAR_LE,VKM_LE,RSC_LE,RSE_LE,RSA_LE,PDIM_LE,OTIM_LE,IPC_LE,ICS_LE,VPM_LE,HUD_LE,TouchPad_LE,DVB_T_LE,VCU_LE,CSM_LE,RadioHead_LE,CHM_LE,AMP_LE,CGM_LE

BO_ 1354 UUDT_Resp_From_LVMPC_LE: 8 LVMPC_LE
 SG_ DgnInf_LS54A : 7|64@0+ (1,0) [0|1.84467440737096E+019] ""  CSM_LE,CGM_LE,TCP_LE,ONSTAR_LE

BO_ 1606 USDT_Resp_From_ICS_LE: 8 ICS_LE
 SG_ DgnInf : 7|64@0+ (1,0) [0|1.84467440737096E+019] ""  CSM_LE,CGM_LE,TCP_LE,ONSTAR_LE

BO_ 1574 VNMF_LE_626_ICS: 8 ICS_LE
 SG_ VectraSpcNWMgtD : 7|64@0+ (1,0) [0|1.84467440737096E+019] ""  RCRM_LE,V2V_LE,TCP_LE,UHP_Low_LE,LVMNav_LE,ONSTAR_LE,VKM_LE,RSC_LE,RSE_LE,RSA_LE,PDIM_LE,OTIM_LE,CHUD_LE,LVMPC_LE,IPC_LE,VPM_LE,HUD_LE,TouchPad_LE,DVB_T_LE,VCU_LE,CSM_LE,RadioHead_LE,CHM_LE,AMP_LE,CGM_LE

BO_ 1350 UUDT_Resp_From_ICS_LE: 8 ICS_LE
 SG_ DgnInf_LS546 : 7|64@0+ (1,0) [0|1.84467440737096E+019] ""  CSM_LE,CGM_LE,TCP_LE,ONSTAR_LE

BO_TX_BU_ 2150375424 : VCU_LE,CSM_LE,RadioHead_LE;
BO_TX_BU_ 2151882752 : VCU_LE,CSM_LE,RadioHead_LE;
BO_TX_BU_ 2151178240 : VCU_LE,CSM_LE,RadioHead_LE;
BO_TX_BU_ 2156265472 : VCU_LE,CSM_LE,RadioHead_LE;
BO_TX_BU_ 2150563840 : CSM_LE,VCU_LE,RadioHead_LE;
BO_TX_BU_ 2150891520 : VCU_LE,CSM_LE,RadioHead_LE;
BO_TX_BU_ 2155569152 : VCU_LE,CSM_LE,RadioHead_LE;
BO_TX_BU_ 2152022016 : TCP_LE,ONSTAR_LE;
BO_TX_BU_ 2152005632 : VCU_LE,RadioHead_LE;
BO_TX_BU_ 2151989248 : VCU_LE,RadioHead_LE;
BO_TX_BU_ 2154708992 : VCU_LE,RadioHead_LE;
BO_TX_BU_ 1613 : TCP_LE,UHP_Low_LE,LVMNav_LE,ONSTAR_LE;
BO_TX_BU_ 1581 : TCP_LE,UHP_Low_LE,LVMNav_LE,ONSTAR_LE;
BO_TX_BU_ 1357 : TCP_LE,UHP_Low_LE,LVMNav_LE,ONSTAR_LE;
BO_TX_BU_ 2159214592 : CSM_LE,VCU_LE,RadioHead_LE;
BO_TX_BU_ 2158911488 : CSM_LE,VCU_LE,RadioHead_LE;
BO_TX_BU_ 2158878720 : CSM_LE,VCU_LE,RadioHead_LE;
BO_TX_BU_ 2158845952 : CSM_LE,VCU_LE,RadioHead_LE;
BO_TX_BU_ 1608 : CGM_LE,PDIM_LE;
BO_TX_BU_ 1576 : CGM_LE,PDIM_LE;
BO_TX_BU_ 1352 : CGM_LE,PDIM_LE;
BO_TX_BU_ 2151907328 : CGM_LE,VCU_LE,IPC_LE;
BO_TX_BU_ 1610 : CGM_LE,CHUD_LE,LVMPC_LE;
BO_TX_BU_ 1578 : CGM_LE,CHUD_LE,LVMPC_LE;
BO_TX_BU_ 1354 : CGM_LE,CHUD_LE,LVMPC_LE;
CM_ SG_ 2151899136 PTORelBrkPedIO "Power Take Off Release Brake Pedal To Engage Indication On";
CM_ SG_ 2158911488 ODDMC_ReqType "ODI - Type of Request";
CM_ SG_ 2158911488 ODDMC_DispMID "ODI - ID that identifies the display requesting the data.  See detailed requirements in ODI GMLAN Protocol.";
CM_ SG_ 2158911488 ODDMC_DataID2Vld "ODI -DataIDTwo is being requested as a valid ID.";
CM_ SG_ 2158911488 ODDMC_DataID2 "ODI - ID for the second requested data parameter as defined in the FUDatabase";
CM_ SG_ 2158911488 ODDMC_DataID3Vld "ODI -DataIDThree is being requested as a valid ID.";
CM_ SG_ 2158911488 ODDMC_DataID3 "ODI - ID for the third requested data parameter as defined in the FUDatabase";
CM_ SG_ 2158911488 ODDMC_DataID1 "ODI - ID for the first requested data parameter as defined in the FUDatabase";
CM_ SG_ 2158911488 ODDMC_DataID4Vld "ODI -DataIDFour is being requested as a valid ID.";
CM_ SG_ 2158911488 ODDMC_DataID4 "ODI - ID for the fourth requested data parameter as defined in the FUDatabase";
CM_ SG_ 2158911488 ODDMC_DataID5Vld "ODI -DataIDFive is being requested as a valid ID.";
CM_ SG_ 2158911488 ODDMC_DataID5 "ODI - ID for the fifth requested data parameter as defined in the FUDatabase";
CM_ SG_ 2158911488 ODDMC_FUCID "ODI - Primary ID of Functional Unit in FU Database";
CM_ BO_ 2158878720 "LAP: Signalerna är inte riktigt kodade!!!        ODI";
CM_ SG_ 2158878720 ODDLC_SubIdReqM "ODI-The number of list entries, starting at the Index, to send";
CM_ SG_ 2158878720 ODDLC_WrpArnd "ODI-Boolean that shall be set to true if the list shall wrap around.";
CM_ SG_ 2158878720 ODDLC_ReqType "ODI - Type of Request";
CM_ SG_ 2158878720 ODDLC_ReqDir "ODI-Boolean that shall be set to true if req down, set to false if set to up";
CM_ SG_ 2158878720 ODDLC_NmEntries "ODI-The number of list entries, starting at the Index, to send";
CM_ SG_ 2158878720 ODDLC_Idx "ODI-The index within the remote FU’s list at which to start sending data";
CM_ SG_ 2158878720 ODDLC_FUCID "ODI - Primary ID of Functional Unit in FU Database";
CM_ SG_ 2158878720 ODDLC_DspMID "ODI - ID that identifies the display requesting the data.  See detailed requirements in ODI GMLAN Protocol.";
CM_ SG_ 2158878720 ODDLC_DataId "ODI-Data Id for the dynamic list";
CM_ SG_ 2158878720 ODDLC_BckgndFlag "ODI-Informs FU as to priority of response.
Applies to all DataIds in the message.
$0=Immediate response required
$1=Background response";
CM_ SG_ 2158845952 ODIAC_FUCID "ODI - Primary ID of Functional Unit in FU Database";
CM_ SG_ 2158845952 ODIAC_DspMID "ODI - ID that identifies the display requesting the data.  See detailed requirements in ODI GMLAN Protocol.";
CM_ SG_ 2158845952 ODIAC_ActnVal "ODI-Integer value for Actions with values.
FUDatabase definition of Action includes ActionDataType that defines whether or not Action has a value. 
For Actions without a value, this field is always sent as 0.";
CM_ SG_ 2158845952 ODIAC_ActnID "ODI-ActionId within the FUClass";
CM_ SG_ 2151079936 PDIMPrsnt "Indicates if the PDIM ECU is present on the bus.";
CM_ SG_ 2162982912 VehIdNmDig10_17 "Desc: 8 ASCII Characters";
CM_ SG_ 2162966528 VehIdNmDig2_9 "Desc: 8 ASCII Characters";
BA_DEF_ SG_  "VNSigPrimaryTriggering" ENUM  "No","Yes","DLCLS","DLCHS","DLCCE","DLCFO";
BA_DEF_ SG_  "VNSigRemoteDiagnostics" ENUM  "No","Yes","DLCLS","DLCHS","DLCCE","DLCFO";
BA_DEF_ SG_  "VNSigInfotainment" ENUM  "No","Yes","DLCLS","DLCHS","DLCCE","DLCFO";
BA_DEF_ SG_  "VNSigParkedVehicle" ENUM  "No","Yes","DLCLS","DLCHS","DLCCE","DLCFO";
BA_DEF_ SG_  "VNSigIntermediate" ENUM  "No","Yes","DLCLS","DLCHS","DLCCE","DLCFO";
BA_DEF_ SG_  "VNSigUnused_4" ENUM  "No","Yes","DLCLS","DLCHS","DLCCE","DLCFO";
BA_DEF_ SG_  "SignalType" STRING ;
BA_DEF_ SG_  "PacketOrder" INT 0 65535;
BA_DEF_ SG_  "SignalLongName" STRING ;
BA_DEF_ SG_  "GenSigStartValue" INT 0 65535;
BA_DEF_ SG_  "VNSigDiagnostic" ENUM  "No","Yes","DLCLS","DLCHS","DLCCE","DLCFO";
BA_DEF_ SG_  "VNSigAllNodes" ENUM  "No","Yes","DLCLS","DLCHS","DLCCE","DLCFO";
BA_DEF_ SG_  "GenSigDeltaValue" INT 0 0;
BA_DEF_ SG_  "GenSigSendType" ENUM  "not used","not used","not used","not used","not used","not used","not used","NoSigSendType","not used","not used","OnAnyChange","OnChangeIfActive","OnDelta","DLCLS","DLCHS","DLCCE","DLCFO";
BA_DEF_ SG_  "GenSigSendOnInit" ENUM  "Not Initialized","Application","Handler","DLCLS","DLCHS","DLCCE","DLCFO";
BA_DEF_ BO_  "AppGenMsgCycleTime" INT 0 0;
BA_DEF_ BO_  "TpTxIndex" INT 0 99;
BA_DEF_ BO_  "GenMsgILSupport" ENUM  "No","Yes","DLCLS","DLCHS","DLCCE","DLCFO";
BA_DEF_ BO_  "TpApplType" STRING ;
BA_DEF_ BO_  "Prio" INT 0 7;
BA_DEF_ BO_  "MessageSubnet" ENUM  "LS","MS","HS","CE","PE","HV","FO","S1","HE","LE","HE2","DLCLS","DLCHS","DLCCE","DLCFO";
BA_DEF_ BO_  "GenMsgMandatoryToSupervision" ENUM  "No","Yes","DLCLS","DLCHS","DLCCE","DLCFO";
BA_DEF_ BO_  "DiagState" ENUM  "No","Yes","DLCLS","DLCHS","DLCCE","DLCFO";
BA_DEF_ BO_  "GenMsgStartDelayTime" INT 0 100000;
BA_DEF_ BO_  "GenMsgDelayTime" INT 0 100000;
BA_DEF_ BO_  "GenMsgCycleTime" INT 0 100000;
BA_DEF_ BO_  "GenMsgSendType" ENUM  "cyclicX","spontanX","cyclicIfActiveX","spontanWithDelay","cyclicAndSpontanX","cyclicAndSpontanWithDelay","spontanWithRepitition","cyclicIfActiveAndSpontanWD","DLCLS","DLCHS","DLCCE","DLCFO";
BA_DEF_ BO_  "DiagResponse" ENUM  "No","Yes","DLCLS","DLCHS","DLCCE","DLCFO";
BA_DEF_ BO_  "DiagRequest" ENUM  "No","Yes","DLCLS","DLCHS","DLCCE","DLCFO";
BA_DEF_ BO_  "NmMessage" ENUM  "No","Yes","DLCLS","DLCHS","DLCCE","DLCFO";
BA_DEF_REL_ BU_SG_REL_  "GenSigSuprvRespComment" STRING ;
BA_DEF_REL_ BU_SG_REL_  "GenSigVBitResp" ENUM  "No","Yes","DLCLS","DLCHS","DLCCE","DLCFO";
BA_DEF_REL_ BU_SG_REL_  "GenSigVBitRespComment" STRING ;
BA_DEF_REL_ BU_SG_REL_  "GenSigVDAFailComment" STRING ;
BA_DEF_REL_ BU_SG_REL_  "GenSigVDAFailResp" ENUM  "No","Yes","DLCLS","DLCHS","DLCCE","DLCFO";
BA_DEF_REL_ BU_SG_REL_  "GenSigRxStartValue" STRING ;
BA_DEF_REL_ BU_SG_REL_  "GenSigSuprvRespSubValue" INT 0 65535;
BA_DEF_REL_ BU_SG_REL_  "GenSigSuprvResp" ENUM  "None","Notify App","Substitute Default","DLCLS","DLCHS","DLCCE","DLCFO";
BA_DEF_REL_ BU_SG_REL_  "GenSigTimeoutMsg" HEX -2147483648 268435455;
BA_DEF_DEF_  "VNSigPrimaryTriggering" "No";
BA_DEF_DEF_  "VNSigRemoteDiagnostics" "No";
BA_DEF_DEF_  "VNSigInfotainment" "No";
BA_DEF_DEF_  "VNSigParkedVehicle" "No";
BA_DEF_DEF_  "VNSigIntermediate" "No";
BA_DEF_DEF_  "VNSigUnused_4" "No";
BA_DEF_DEF_  "SignalType" "";
BA_DEF_DEF_  "PacketOrder" 0;
BA_DEF_DEF_  "SignalLongName" "";
BA_DEF_DEF_  "GenSigStartValue" 0;
BA_DEF_DEF_  "VNSigDiagnostic" "No";
BA_DEF_DEF_  "VNSigAllNodes" "No";
BA_DEF_DEF_  "GenSigDeltaValue" 0;
BA_DEF_DEF_  "GenSigSendType" "NoSigSendType";
BA_DEF_DEF_  "GenSigSendOnInit" "Not Initialized";
BA_DEF_DEF_  "AppGenMsgCycleTime" 0;
BA_DEF_DEF_  "TpTxIndex" 0;
BA_DEF_DEF_  "GenMsgILSupport" "Yes";
BA_DEF_DEF_  "TpApplType" "";
BA_DEF_DEF_  "Prio" 4;
BA_DEF_DEF_  "MessageSubnet" "FO";
BA_DEF_DEF_  "GenMsgMandatoryToSupervision" "No";
BA_DEF_DEF_  "DiagState" "No";
BA_DEF_DEF_  "GenMsgStartDelayTime" 0;
BA_DEF_DEF_  "GenMsgDelayTime" 0;
BA_DEF_DEF_  "GenMsgCycleTime" 0;
BA_DEF_DEF_  "GenMsgSendType" "spontanX";
BA_DEF_DEF_  "DiagResponse" "No";
BA_DEF_DEF_  "DiagRequest" "No";
BA_DEF_DEF_  "NmMessage" "No";
BA_DEF_DEF_REL_ "GenSigSuprvRespComment" "";
BA_DEF_DEF_REL_ "GenSigVBitResp" "No";
BA_DEF_DEF_REL_ "GenSigVBitRespComment" "";
BA_DEF_DEF_REL_ "GenSigVDAFailComment" "";
BA_DEF_DEF_REL_ "GenSigVDAFailResp" "No";
BA_DEF_DEF_REL_ "GenSigRxStartValue" "";
BA_DEF_DEF_REL_ "GenSigSuprvRespSubValue" 0;
BA_DEF_DEF_REL_ "GenSigSuprvResp" "None";
BA_DEF_DEF_REL_ "GenSigTimeoutMsg" 0;
BA_ "MessageSubnet" BO_ 2150252544 9;
BA_ "GenMsgDelayTime" BO_ 2150252544 100;
BA_ "MessageSubnet" BO_ 2150383616 9;
BA_ "GenMsgDelayTime" BO_ 2150383616 100;
BA_ "MessageSubnet" BO_ 2150375424 9;
BA_ "GenMsgDelayTime" BO_ 2150375424 100;
BA_ "MessageSubnet" BO_ 2150113280 9;
BA_ "GenMsgDelayTime" BO_ 2150113280 100;
BA_ "MessageSubnet" BO_ 2151858176 9;
BA_ "GenMsgDelayTime" BO_ 2151858176 100;
BA_ "MessageSubnet" BO_ 2151809024 9;
BA_ "GenMsgDelayTime" BO_ 2151809024 100;
BA_ "MessageSubnet" BO_ 2151792640 9;
BA_ "GenMsgDelayTime" BO_ 2151792640 100;
BA_ "MessageSubnet" BO_ 2151776256 9;
BA_ "GenMsgDelayTime" BO_ 2151776256 100;
BA_ "MessageSubnet" BO_ 2151899136 9;
BA_ "GenMsgCycleTime" BO_ 2151899136 250;
BA_ "GenMsgSendType" BO_ 2151899136 0;
BA_ "MessageSubnet" BO_ 2151882752 9;
BA_ "GenMsgDelayTime" BO_ 2151882752 100;
BA_ "MessageSubnet" BO_ 2155913216 9;
BA_ "GenMsgCycleTime" BO_ 2155913216 1000;
BA_ "GenMsgSendType" BO_ 2155913216 0;
BA_ "MessageSubnet" BO_ 2154790912 9;
BA_ "GenMsgDelayTime" BO_ 2154790912 100;
BA_ "MessageSubnet" BO_ 2154774528 9;
BA_ "GenMsgDelayTime" BO_ 2154774528 100;
BA_ "MessageSubnet" BO_ 2151178240 9;
BA_ "GenMsgDelayTime" BO_ 2151178240 100;
BA_ "MessageSubnet" BO_ 2149728256 9;
BA_ "GenMsgDelayTime" BO_ 2149728256 100;
BA_ "MessageSubnet" BO_ 2156265472 9;
BA_ "GenMsgDelayTime" BO_ 2156265472 100;
BA_ "MessageSubnet" BO_ 2150563840 9;
BA_ "GenMsgDelayTime" BO_ 2150563840 100;
BA_ "MessageSubnet" BO_ 2149793792 9;
BA_ "GenMsgDelayTime" BO_ 2149793792 100;
BA_ "MessageSubnet" BO_ 2150891520 9;
BA_ "GenMsgDelayTime" BO_ 2150891520 100;
BA_ "MessageSubnet" BO_ 2155569152 9;
BA_ "GenMsgDelayTime" BO_ 2155569152 100;
BA_ "MessageSubnet" BO_ 2152022016 9;
BA_ "GenMsgDelayTime" BO_ 2152022016 100;
BA_ "MessageSubnet" BO_ 2152005632 9;
BA_ "GenMsgDelayTime" BO_ 2152005632 100;
BA_ "MessageSubnet" BO_ 2151989248 9;
BA_ "GenMsgDelayTime" BO_ 2151989248 100;
BA_ "MessageSubnet" BO_ 2154708992 9;
BA_ "GenMsgDelayTime" BO_ 2154708992 200;
BA_ "MessageSubnet" BO_ 2149875712 9;
BA_ "GenMsgMandatoryToSupervision" BO_ 2149875712 1;
BA_ "GenMsgStartDelayTime" BO_ 2149875712 120;
BA_ "GenMsgCycleTime" BO_ 2149875712 500;
BA_ "GenMsgSendType" BO_ 2149875712 0;
BA_ "Prio" BO_ 1613 0;
BA_ "MessageSubnet" BO_ 1613 9;
BA_ "DiagResponse" BO_ 1613 1;
BA_ "Prio" BO_ 1581 0;
BA_ "MessageSubnet" BO_ 1581 9;
BA_ "GenMsgCycleTime" BO_ 1581 3000;
BA_ "GenMsgSendType" BO_ 1581 0;
BA_ "NmMessage" BO_ 1581 1;
BA_ "GenMsgILSupport" BO_ 1357 0;
BA_ "TpApplType" BO_ 1357 "DiagUUDTResponse";
BA_ "Prio" BO_ 1357 0;
BA_ "MessageSubnet" BO_ 1357 9;
BA_ "MessageSubnet" BO_ 2159222784 9;
BA_ "GenMsgDelayTime" BO_ 2159222784 10;
BA_ "MessageSubnet" BO_ 2159214592 9;
BA_ "GenMsgDelayTime" BO_ 2159214592 10;
BA_ "MessageSubnet" BO_ 2158911488 9;
BA_ "GenMsgDelayTime" BO_ 2158911488 20;
BA_ "MessageSubnet" BO_ 2158878720 9;
BA_ "GenMsgDelayTime" BO_ 2158878720 20;
BA_ "MessageSubnet" BO_ 2158845952 9;
BA_ "GenMsgDelayTime" BO_ 2158845952 20;
BA_ "MessageSubnet" BO_ 2151079936 9;
BA_ "GenMsgDelayTime" BO_ 2151079936 100;
BA_ "Prio" BO_ 1608 0;
BA_ "MessageSubnet" BO_ 1608 9;
BA_ "DiagResponse" BO_ 1608 1;
BA_ "Prio" BO_ 1576 0;
BA_ "MessageSubnet" BO_ 1576 9;
BA_ "GenMsgCycleTime" BO_ 1576 3000;
BA_ "GenMsgSendType" BO_ 1576 0;
BA_ "NmMessage" BO_ 1576 1;
BA_ "GenMsgILSupport" BO_ 1352 0;
BA_ "TpApplType" BO_ 1352 "DiagUUDTResponse";
BA_ "Prio" BO_ 1352 0;
BA_ "MessageSubnet" BO_ 1352 9;
BA_ "MessageSubnet" BO_ 2153824256 9;
BA_ "GenMsgDelayTime" BO_ 2153824256 100;
BA_ "MessageSubnet" BO_ 2151907328 9;
BA_ "GenMsgDelayTime" BO_ 2151907328 100;
BA_ "MessageSubnet" BO_ 2162982912 9;
BA_ "GenMsgStartDelayTime" BO_ 2162982912 200;
BA_ "GenMsgCycleTime" BO_ 2162982912 5000;
BA_ "GenMsgSendType" BO_ 2162982912 0;
BA_ "MessageSubnet" BO_ 2162966528 9;
BA_ "GenMsgStartDelayTime" BO_ 2162966528 190;
BA_ "GenMsgCycleTime" BO_ 2162966528 5000;
BA_ "GenMsgSendType" BO_ 2162966528 0;
BA_ "MessageSubnet" BO_ 2152497152 9;
BA_ "GenMsgDelayTime" BO_ 2152497152 1000;
BA_ "GenMsgCycleTime" BO_ 2152497152 1000;
BA_ "GenMsgSendType" BO_ 2152497152 0;
BA_ "MessageSubnet" BO_ 2152480768 9;
BA_ "GenMsgDelayTime" BO_ 2152480768 1000;
BA_ "Prio" BO_ 1610 0;
BA_ "MessageSubnet" BO_ 1610 9;
BA_ "DiagResponse" BO_ 1610 1;
BA_ "Prio" BO_ 1578 0;
BA_ "MessageSubnet" BO_ 1578 9;
BA_ "GenMsgCycleTime" BO_ 1578 3000;
BA_ "GenMsgSendType" BO_ 1578 0;
BA_ "NmMessage" BO_ 1578 1;
BA_ "GenMsgILSupport" BO_ 1354 0;
BA_ "TpApplType" BO_ 1354 "DiagUUDTResponse";
BA_ "Prio" BO_ 1354 0;
BA_ "MessageSubnet" BO_ 1354 9;
BA_ "Prio" BO_ 1606 0;
BA_ "MessageSubnet" BO_ 1606 9;
BA_ "DiagResponse" BO_ 1606 1;
BA_ "Prio" BO_ 1574 0;
BA_ "MessageSubnet" BO_ 1574 9;
BA_ "GenMsgCycleTime" BO_ 1574 3000;
BA_ "GenMsgSendType" BO_ 1574 0;
BA_ "NmMessage" BO_ 1574 1;
BA_ "GenMsgILSupport" BO_ 1350 0;
BA_ "TpApplType" BO_ 1350 "DiagUUDTResponse";
BA_ "Prio" BO_ 1350 0;
BA_ "MessageSubnet" BO_ 1350 9;
BA_ "GenSigDeltaValue" SG_ 2150252544 ECHG_YAxisMaxVal 1;
BA_ "GenSigSendType" SG_ 2150252544 ECHG_YAxisMaxVal 10;
BA_ "GenSigSendOnInit" SG_ 2150252544 ECHG_YAxisMaxVal 1;
BA_ "VNSigInfotainment" SG_ 2150252544 ECHG_YAxisMaxVal 1;
BA_ "SignalType" SG_ 2150252544 ECHG_YAxisMaxVal "ENM";
BA_ "PacketOrder" SG_ 2150252544 ECHG_YAxisMaxVal 14;
BA_ "SignalLongName" SG_ 2150252544 ECHG_YAxisMaxVal "Energy Consumption History Graph : Y Axis Maximum Value";
BA_ "VNSigAllNodes" SG_ 2150252544 ECHG_YAxisMaxVal 1;
BA_ "GenSigDeltaValue" SG_ 2150252544 ECHG_XAxisTkMrkIntvl 1;
BA_ "GenSigSendType" SG_ 2150252544 ECHG_XAxisTkMrkIntvl 10;
BA_ "GenSigSendOnInit" SG_ 2150252544 ECHG_XAxisTkMrkIntvl 1;
BA_ "VNSigInfotainment" SG_ 2150252544 ECHG_XAxisTkMrkIntvl 1;
BA_ "SignalType" SG_ 2150252544 ECHG_XAxisTkMrkIntvl "ENM";
BA_ "PacketOrder" SG_ 2150252544 ECHG_XAxisTkMrkIntvl 13;
BA_ "SignalLongName" SG_ 2150252544 ECHG_XAxisTkMrkIntvl "Energy Consumption History Graph : X Axis Tick Mark Interval";
BA_ "VNSigAllNodes" SG_ 2150252544 ECHG_XAxisTkMrkIntvl 1;
BA_ "GenSigDeltaValue" SG_ 2150252544 ECHG_Column10 1;
BA_ "GenSigSendType" SG_ 2150252544 ECHG_Column10 12;
BA_ "GenSigSendOnInit" SG_ 2150252544 ECHG_Column10 1;
BA_ "VNSigInfotainment" SG_ 2150252544 ECHG_Column10 1;
BA_ "SignalType" SG_ 2150252544 ECHG_Column10 "UNM";
BA_ "PacketOrder" SG_ 2150252544 ECHG_Column10 12;
BA_ "SignalLongName" SG_ 2150252544 ECHG_Column10 "Energy Consumption History Graph : Column 10";
BA_ "VNSigAllNodes" SG_ 2150252544 ECHG_Column10 1;
BA_ "GenSigDeltaValue" SG_ 2150252544 ECHG_Column09 1;
BA_ "GenSigSendType" SG_ 2150252544 ECHG_Column09 12;
BA_ "GenSigSendOnInit" SG_ 2150252544 ECHG_Column09 1;
BA_ "VNSigInfotainment" SG_ 2150252544 ECHG_Column09 1;
BA_ "SignalType" SG_ 2150252544 ECHG_Column09 "UNM";
BA_ "PacketOrder" SG_ 2150252544 ECHG_Column09 11;
BA_ "SignalLongName" SG_ 2150252544 ECHG_Column09 "Energy Consumption History Graph : Column 09";
BA_ "VNSigAllNodes" SG_ 2150252544 ECHG_Column09 1;
BA_ "GenSigDeltaValue" SG_ 2150252544 ECHG_Column08 1;
BA_ "GenSigSendType" SG_ 2150252544 ECHG_Column08 12;
BA_ "GenSigSendOnInit" SG_ 2150252544 ECHG_Column08 1;
BA_ "VNSigInfotainment" SG_ 2150252544 ECHG_Column08 1;
BA_ "SignalType" SG_ 2150252544 ECHG_Column08 "UNM";
BA_ "PacketOrder" SG_ 2150252544 ECHG_Column08 10;
BA_ "SignalLongName" SG_ 2150252544 ECHG_Column08 "Energy Consumption History Graph : Column 08";
BA_ "VNSigAllNodes" SG_ 2150252544 ECHG_Column08 1;
BA_ "GenSigDeltaValue" SG_ 2150252544 ECHG_Column07 1;
BA_ "GenSigSendType" SG_ 2150252544 ECHG_Column07 12;
BA_ "GenSigSendOnInit" SG_ 2150252544 ECHG_Column07 1;
BA_ "VNSigInfotainment" SG_ 2150252544 ECHG_Column07 1;
BA_ "SignalType" SG_ 2150252544 ECHG_Column07 "UNM";
BA_ "PacketOrder" SG_ 2150252544 ECHG_Column07 9;
BA_ "SignalLongName" SG_ 2150252544 ECHG_Column07 "Energy Consumption History Graph : Column 07";
BA_ "VNSigAllNodes" SG_ 2150252544 ECHG_Column07 1;
BA_ "GenSigDeltaValue" SG_ 2150252544 ECHG_Column06 1;
BA_ "GenSigSendType" SG_ 2150252544 ECHG_Column06 12;
BA_ "GenSigSendOnInit" SG_ 2150252544 ECHG_Column06 1;
BA_ "VNSigInfotainment" SG_ 2150252544 ECHG_Column06 1;
BA_ "SignalType" SG_ 2150252544 ECHG_Column06 "UNM";
BA_ "PacketOrder" SG_ 2150252544 ECHG_Column06 8;
BA_ "SignalLongName" SG_ 2150252544 ECHG_Column06 "Energy Consumption History Graph : Column 06";
BA_ "VNSigAllNodes" SG_ 2150252544 ECHG_Column06 1;
BA_ "GenSigDeltaValue" SG_ 2150252544 ECHG_Column05 1;
BA_ "GenSigSendType" SG_ 2150252544 ECHG_Column05 12;
BA_ "GenSigSendOnInit" SG_ 2150252544 ECHG_Column05 1;
BA_ "VNSigInfotainment" SG_ 2150252544 ECHG_Column05 1;
BA_ "SignalType" SG_ 2150252544 ECHG_Column05 "UNM";
BA_ "PacketOrder" SG_ 2150252544 ECHG_Column05 7;
BA_ "SignalLongName" SG_ 2150252544 ECHG_Column05 "Energy Consumption History Graph : Column 05";
BA_ "VNSigAllNodes" SG_ 2150252544 ECHG_Column05 1;
BA_ "GenSigDeltaValue" SG_ 2150252544 ECHG_Column04 1;
BA_ "GenSigSendType" SG_ 2150252544 ECHG_Column04 12;
BA_ "GenSigSendOnInit" SG_ 2150252544 ECHG_Column04 1;
BA_ "VNSigInfotainment" SG_ 2150252544 ECHG_Column04 1;
BA_ "SignalType" SG_ 2150252544 ECHG_Column04 "UNM";
BA_ "PacketOrder" SG_ 2150252544 ECHG_Column04 6;
BA_ "SignalLongName" SG_ 2150252544 ECHG_Column04 "Energy Consumption History Graph : Column 04";
BA_ "VNSigAllNodes" SG_ 2150252544 ECHG_Column04 1;
BA_ "GenSigDeltaValue" SG_ 2150252544 ECHG_Column03 1;
BA_ "GenSigSendType" SG_ 2150252544 ECHG_Column03 12;
BA_ "GenSigSendOnInit" SG_ 2150252544 ECHG_Column03 1;
BA_ "VNSigInfotainment" SG_ 2150252544 ECHG_Column03 1;
BA_ "SignalType" SG_ 2150252544 ECHG_Column03 "UNM";
BA_ "PacketOrder" SG_ 2150252544 ECHG_Column03 5;
BA_ "SignalLongName" SG_ 2150252544 ECHG_Column03 "Energy Consumption History Graph : Column 03";
BA_ "VNSigAllNodes" SG_ 2150252544 ECHG_Column03 1;
BA_ "GenSigDeltaValue" SG_ 2150252544 ECHG_Column02 1;
BA_ "GenSigSendType" SG_ 2150252544 ECHG_Column02 12;
BA_ "GenSigSendOnInit" SG_ 2150252544 ECHG_Column02 1;
BA_ "VNSigInfotainment" SG_ 2150252544 ECHG_Column02 1;
BA_ "SignalType" SG_ 2150252544 ECHG_Column02 "UNM";
BA_ "PacketOrder" SG_ 2150252544 ECHG_Column02 4;
BA_ "SignalLongName" SG_ 2150252544 ECHG_Column02 "Energy Consumption History Graph : Column 02";
BA_ "VNSigAllNodes" SG_ 2150252544 ECHG_Column02 1;
BA_ "GenSigDeltaValue" SG_ 2150252544 ECHG_Column01 1;
BA_ "GenSigSendType" SG_ 2150252544 ECHG_Column01 12;
BA_ "GenSigSendOnInit" SG_ 2150252544 ECHG_Column01 1;
BA_ "VNSigInfotainment" SG_ 2150252544 ECHG_Column01 1;
BA_ "SignalType" SG_ 2150252544 ECHG_Column01 "UNM";
BA_ "PacketOrder" SG_ 2150252544 ECHG_Column01 3;
BA_ "SignalLongName" SG_ 2150252544 ECHG_Column01 "Energy Consumption History Graph : Column 01";
BA_ "VNSigAllNodes" SG_ 2150252544 ECHG_Column01 1;
BA_ "GenSigDeltaValue" SG_ 2150252544 ECHG_EngyCnsmdAvg 1;
BA_ "GenSigSendType" SG_ 2150252544 ECHG_EngyCnsmdAvg 12;
BA_ "GenSigSendOnInit" SG_ 2150252544 ECHG_EngyCnsmdAvg 1;
BA_ "VNSigInfotainment" SG_ 2150252544 ECHG_EngyCnsmdAvg 1;
BA_ "SignalType" SG_ 2150252544 ECHG_EngyCnsmdAvg "UNM";
BA_ "PacketOrder" SG_ 2150252544 ECHG_EngyCnsmdAvg 2;
BA_ "SignalLongName" SG_ 2150252544 ECHG_EngyCnsmdAvg "Energy Consumption History Graph : Energy Consumed Average";
BA_ "VNSigAllNodes" SG_ 2150252544 ECHG_EngyCnsmdAvg 1;
BA_ "GenSigDeltaValue" SG_ 2150252544 ECHG_MeasUnit 1;
BA_ "GenSigSendType" SG_ 2150252544 ECHG_MeasUnit 10;
BA_ "GenSigSendOnInit" SG_ 2150252544 ECHG_MeasUnit 1;
BA_ "VNSigInfotainment" SG_ 2150252544 ECHG_MeasUnit 1;
BA_ "SignalType" SG_ 2150252544 ECHG_MeasUnit "ENM";
BA_ "PacketOrder" SG_ 2150252544 ECHG_MeasUnit 1;
BA_ "SignalLongName" SG_ 2150252544 ECHG_MeasUnit "Energy Consumption History Graph : Measurement Unit";
BA_ "VNSigAllNodes" SG_ 2150252544 ECHG_MeasUnit 1;
BA_ "GenSigSendType" SG_ 2150383616 LssOfPrplsnIO 10;
BA_ "SignalType" SG_ 2150383616 LssOfPrplsnIO "BLN";
BA_ "SignalLongName" SG_ 2150383616 LssOfPrplsnIO "Loss of Propulsion Indication On";
BA_ "VNSigAllNodes" SG_ 2150383616 LssOfPrplsnIO 1;
BA_ "GenSigDeltaValue" SG_ 2150383616 EngMntncePrcntCpl 1;
BA_ "GenSigSendType" SG_ 2150383616 EngMntncePrcntCpl 12;
BA_ "SignalType" SG_ 2150383616 EngMntncePrcntCpl "UNM";
BA_ "SignalLongName" SG_ 2150383616 EngMntncePrcntCpl "Engine Maintenance Percent Complete";
BA_ "VNSigAllNodes" SG_ 2150383616 EngMntncePrcntCpl 1;
BA_ "GenSigSendType" SG_ 2150383616 EngMntnceMdAct 10;
BA_ "SignalType" SG_ 2150383616 EngMntnceMdAct "BLN";
BA_ "SignalLongName" SG_ 2150383616 EngMntnceMdAct "Engine Maintenance Mode Active";
BA_ "VNSigAllNodes" SG_ 2150383616 EngMntnceMdAct 1;
BA_ "GenSigDeltaValue" SG_ 2150383616 BatPrpDspPwrLvlPct 1;
BA_ "GenSigSendType" SG_ 2150383616 BatPrpDspPwrLvlPct 12;
BA_ "SignalType" SG_ 2150383616 BatPrpDspPwrLvlPct "SNM";
BA_ "SignalLongName" SG_ 2150383616 BatPrpDspPwrLvlPct "Battery Propulsion Display Power Level Percent";
BA_ "VNSigAllNodes" SG_ 2150383616 BatPrpDspPwrLvlPct 1;
BA_ "GenSigDeltaValue" SG_ 2150383616 PrpDspTtlPwr 1;
BA_ "GenSigSendType" SG_ 2150383616 PrpDspTtlPwr 12;
BA_ "VNSigInfotainment" SG_ 2150383616 PrpDspTtlPwr 1;
BA_ "SignalType" SG_ 2150383616 PrpDspTtlPwr "UNM";
BA_ "SignalLongName" SG_ 2150383616 PrpDspTtlPwr "Propulsion Display Total Power";
BA_ "VNSigAllNodes" SG_ 2150383616 PrpDspTtlPwr 1;
BA_ "GenSigDeltaValue" SG_ 2150383616 PrpCapDspOpPs 1;
BA_ "GenSigSendType" SG_ 2150383616 PrpCapDspOpPs 12;
BA_ "VNSigInfotainment" SG_ 2150383616 PrpCapDspOpPs 1;
BA_ "SignalType" SG_ 2150383616 PrpCapDspOpPs "UNM";
BA_ "SignalLongName" SG_ 2150383616 PrpCapDspOpPs "Propulsion Capability Display Operating Position";
BA_ "VNSigAllNodes" SG_ 2150383616 PrpCapDspOpPs 1;
BA_ "GenSigDeltaValue" SG_ 2150383616 EstElecPrpCap 1;
BA_ "GenSigSendType" SG_ 2150383616 EstElecPrpCap 12;
BA_ "SignalType" SG_ 2150383616 EstElecPrpCap "UNM";
BA_ "SignalLongName" SG_ 2150383616 EstElecPrpCap "Estimated Electrical Propulsion Capability";
BA_ "VNSigAllNodes" SG_ 2150383616 EstElecPrpCap 1;
BA_ "GenSigDeltaValue" SG_ 2150383616 EngPrpDspPwrLvlPct 1;
BA_ "GenSigSendType" SG_ 2150383616 EngPrpDspPwrLvlPct 12;
BA_ "VNSigInfotainment" SG_ 2150383616 EngPrpDspPwrLvlPct 1;
BA_ "SignalType" SG_ 2150383616 EngPrpDspPwrLvlPct "UNM";
BA_ "SignalLongName" SG_ 2150383616 EngPrpDspPwrLvlPct "Engine Propulsion Display Power Level Percent";
BA_ "VNSigAllNodes" SG_ 2150383616 EngPrpDspPwrLvlPct 1;
BA_ "GenSigSendType" SG_ 2150383616 MntnceMdDsplyRq 10;
BA_ "GenSigSendOnInit" SG_ 2150383616 MntnceMdDsplyRq 1;
BA_ "VNSigInfotainment" SG_ 2150383616 MntnceMdDsplyRq 1;
BA_ "SignalType" SG_ 2150383616 MntnceMdDsplyRq "ENM";
BA_ "SignalLongName" SG_ 2150383616 MntnceMdDsplyRq "Maintenance Mode Display Request";
BA_ "VNSigAllNodes" SG_ 2150383616 MntnceMdDsplyRq 1;
BA_ "GenSigSendType" SG_ 2150375424 HVBChrgLmtBtnDspReq 10;
BA_ "VNSigInfotainment" SG_ 2150375424 HVBChrgLmtBtnDspReq 1;
BA_ "SignalType" SG_ 2150375424 HVBChrgLmtBtnDspReq "ENM";
BA_ "SignalLongName" SG_ 2150375424 HVBChrgLmtBtnDspReq "High Voltage Battery Charge Limit Button Display Request";
BA_ "VNSigAllNodes" SG_ 2150375424 HVBChrgLmtBtnDspReq 1;
BA_ "GenSigSendType" SG_ 2150375424 HVBHmChrgTmDspReq 10;
BA_ "VNSigInfotainment" SG_ 2150375424 HVBHmChrgTmDspReq 1;
BA_ "SignalType" SG_ 2150375424 HVBHmChrgTmDspReq "ENM";
BA_ "SignalLongName" SG_ 2150375424 HVBHmChrgTmDspReq "High Voltage Battery Home Charge Time Display Request";
BA_ "VNSigAllNodes" SG_ 2150375424 HVBHmChrgTmDspReq 1;
BA_ "GenSigSendType" SG_ 2150375424 HVBChrgTmDspReq 10;
BA_ "VNSigInfotainment" SG_ 2150375424 HVBChrgTmDspReq 1;
BA_ "SignalType" SG_ 2150375424 HVBChrgTmDspReq "ENM";
BA_ "SignalLongName" SG_ 2150375424 HVBChrgTmDspReq "High Voltage Battery Charge Time Display Request";
BA_ "VNSigAllNodes" SG_ 2150375424 HVBChrgTmDspReq 1;
BA_ "GenSigSendType" SG_ 2150375424 HVBChrgOvrdBtnDspReq 10;
BA_ "VNSigInfotainment" SG_ 2150375424 HVBChrgOvrdBtnDspReq 1;
BA_ "SignalType" SG_ 2150375424 HVBChrgOvrdBtnDspReq "ENM";
BA_ "SignalLongName" SG_ 2150375424 HVBChrgOvrdBtnDspReq "High Voltage Battery Charge Override Button Display Request";
BA_ "VNSigAllNodes" SG_ 2150375424 HVBChrgOvrdBtnDspReq 1;
BA_ "GenSigSendType" SG_ 2150375424 LBCCsStReq 10;
BA_ "VNSigInfotainment" SG_ 2150375424 LBCCsStReq 1;
BA_ "SignalType" SG_ 2150375424 LBCCsStReq "ENM";
BA_ "SignalLongName" SG_ 2150375424 LBCCsStReq "Location Based Charging Customization Setting Request";
BA_ "VNSigAllNodes" SG_ 2150375424 LBCCsStReq 1;
BA_ "GenSigSendType" SG_ 2150375424 LBCPosMdfcReq 10;
BA_ "VNSigInfotainment" SG_ 2150375424 LBCPosMdfcReq 1;
BA_ "SignalType" SG_ 2150375424 LBCPosMdfcReq "ENM";
BA_ "SignalLongName" SG_ 2150375424 LBCPosMdfcReq "Location Based Charging Position Modification Request";
BA_ "VNSigAllNodes" SG_ 2150375424 LBCPosMdfcReq 1;
BA_ "GenSigSendType" SG_ 2150375424 LBCCDRR_ClrStrdPosReq 10;
BA_ "VNSigInfotainment" SG_ 2150375424 LBCCDRR_ClrStrdPosReq 1;
BA_ "SignalType" SG_ 2150375424 LBCCDRR_ClrStrdPosReq "ENM";
BA_ "PacketOrder" SG_ 2150375424 LBCCDRR_ClrStrdPosReq 1;
BA_ "SignalLongName" SG_ 2150375424 LBCCDRR_ClrStrdPosReq "Location Based Charging Customer Data Reset Request : Clear Stored Position Request";
BA_ "VNSigAllNodes" SG_ 2150375424 LBCCDRR_ClrStrdPosReq 1;
BA_ "GenSigSendType" SG_ 2150375424 LBCCDRR_PosNum 10;
BA_ "VNSigInfotainment" SG_ 2150375424 LBCCDRR_PosNum 1;
BA_ "SignalType" SG_ 2150375424 LBCCDRR_PosNum "ENM";
BA_ "PacketOrder" SG_ 2150375424 LBCCDRR_PosNum 2;
BA_ "SignalLongName" SG_ 2150375424 LBCCDRR_PosNum "Location Based Charging Customer Data Reset Request : Position Number";
BA_ "VNSigAllNodes" SG_ 2150375424 LBCCDRR_PosNum 1;
BA_ "GenSigSendType" SG_ 2150375424 USBProgInPrgrs 10;
BA_ "SignalType" SG_ 2150375424 USBProgInPrgrs "BLN";
BA_ "SignalLongName" SG_ 2150375424 USBProgInPrgrs "USB Programming In Progress";
BA_ "VNSigAllNodes" SG_ 2150375424 USBProgInPrgrs 1;
BA_ "GenSigSendType" SG_ 2150375424 EngyCnsHistGrphRstRq 10;
BA_ "VNSigInfotainment" SG_ 2150375424 EngyCnsHistGrphRstRq 1;
BA_ "SignalType" SG_ 2150375424 EngyCnsHistGrphRstRq "BLN";
BA_ "SignalLongName" SG_ 2150375424 EngyCnsHistGrphRstRq "Energy Consumption History Graph Reset Requested";
BA_ "VNSigAllNodes" SG_ 2150375424 EngyCnsHistGrphRstRq 1;
BA_ "GenSigSendType" SG_ 2150375424 DsplTrnsShftLvrLckRqd 10;
BA_ "SignalType" SG_ 2150375424 DsplTrnsShftLvrLckRqd "BLN";
BA_ "SignalLongName" SG_ 2150375424 DsplTrnsShftLvrLckRqd "Displays Transmission Shift Lever Lock Requested";
BA_ "VNSigAllNodes" SG_ 2150375424 DsplTrnsShftLvrLckRqd 1;
BA_ "GenSigSendType" SG_ 2150375424 EngAstHtPlgInCstStRq 10;
BA_ "VNSigInfotainment" SG_ 2150375424 EngAstHtPlgInCstStRq 1;
BA_ "SignalType" SG_ 2150375424 EngAstHtPlgInCstStRq "ENM";
BA_ "SignalLongName" SG_ 2150375424 EngAstHtPlgInCstStRq "Engine Assisted Heating Plugged-In Customization Setting Request";
BA_ "VNSigAllNodes" SG_ 2150375424 EngAstHtPlgInCstStRq 1;
BA_ "GenSigSendType" SG_ 2150375424 EngAstHtCstStRq 10;
BA_ "VNSigInfotainment" SG_ 2150375424 EngAstHtCstStRq 1;
BA_ "SignalType" SG_ 2150375424 EngAstHtCstStRq "ENM";
BA_ "SignalLongName" SG_ 2150375424 EngAstHtCstStRq "Engine Assisted Heating Customization Setting Request";
BA_ "VNSigAllNodes" SG_ 2150375424 EngAstHtCstStRq 1;
BA_ "GenSigSendType" SG_ 2150375424 MntnceMdStEngRq 10;
BA_ "GenSigSendOnInit" SG_ 2150375424 MntnceMdStEngRq 2;
BA_ "VNSigInfotainment" SG_ 2150375424 MntnceMdStEngRq 1;
BA_ "SignalType" SG_ 2150375424 MntnceMdStEngRq "BLN";
BA_ "SignalLongName" SG_ 2150375424 MntnceMdStEngRq "Maintenance Mode Start Engine Request";
BA_ "VNSigAllNodes" SG_ 2150375424 MntnceMdStEngRq 1;
BA_ "GenSigSendType" SG_ 2150113280 HVChrgInhbRsn 10;
BA_ "SignalType" SG_ 2150113280 HVChrgInhbRsn "ENM";
BA_ "SignalLongName" SG_ 2150113280 HVChrgInhbRsn "High Voltage Charging Inhibit Reason";
BA_ "VNSigAllNodes" SG_ 2150113280 HVChrgInhbRsn 1;
BA_ "GenSigDeltaValue" SG_ 2150113280 DrvCyclTrpDstTrvld 1;
BA_ "GenSigSendType" SG_ 2150113280 DrvCyclTrpDstTrvld 12;
BA_ "SignalType" SG_ 2150113280 DrvCyclTrpDstTrvld "UNM";
BA_ "SignalLongName" SG_ 2150113280 DrvCyclTrpDstTrvld "Drive Cycle Trip Distance Traveled";
BA_ "VNSigAllNodes" SG_ 2150113280 DrvCyclTrpDstTrvld 1;
BA_ "GenSigDeltaValue" SG_ 2150113280 DrvCyclElecEngyEcon 1;
BA_ "GenSigSendType" SG_ 2150113280 DrvCyclElecEngyEcon 12;
BA_ "SignalType" SG_ 2150113280 DrvCyclElecEngyEcon "UNM";
BA_ "SignalLongName" SG_ 2150113280 DrvCyclElecEngyEcon "Drive Cycle Electrical Energy Economy";
BA_ "VNSigAllNodes" SG_ 2150113280 DrvCyclElecEngyEcon 1;
BA_ "GenSigSendType" SG_ 2150113280 EngyStgSysActCoolEnb 10;
BA_ "GenSigSendOnInit" SG_ 2150113280 EngyStgSysActCoolEnb 1;
BA_ "VNSigInfotainment" SG_ 2150113280 EngyStgSysActCoolEnb 1;
BA_ "SignalType" SG_ 2150113280 EngyStgSysActCoolEnb "BLN";
BA_ "SignalLongName" SG_ 2150113280 EngyStgSysActCoolEnb "Energy Storage System Active Cooling Enabled";
BA_ "VNSigAllNodes" SG_ 2150113280 EngyStgSysActCoolEnb 1;
BA_ "GenSigDeltaValue" SG_ 2150113280 DrvCycElEnrgUsd 1;
BA_ "GenSigSendType" SG_ 2150113280 DrvCycElEnrgUsd 12;
BA_ "GenSigSendOnInit" SG_ 2150113280 DrvCycElEnrgUsd 1;
BA_ "VNSigInfotainment" SG_ 2150113280 DrvCycElEnrgUsd 1;
BA_ "SignalType" SG_ 2150113280 DrvCycElEnrgUsd "UNM";
BA_ "SignalLongName" SG_ 2150113280 DrvCycElEnrgUsd "Drive Cycle Electrical Energy Used";
BA_ "VNSigAllNodes" SG_ 2150113280 DrvCycElEnrgUsd 1;
BA_ "GenSigDeltaValue" SG_ 2151858176 DrvCycElecEngySt4 1;
BA_ "GenSigSendType" SG_ 2151858176 DrvCycElecEngySt4 12;
BA_ "GenSigSendOnInit" SG_ 2151858176 DrvCycElecEngySt4 1;
BA_ "VNSigInfotainment" SG_ 2151858176 DrvCycElecEngySt4 1;
BA_ "SignalType" SG_ 2151858176 DrvCycElecEngySt4 "UNM";
BA_ "SignalLongName" SG_ 2151858176 DrvCycElecEngySt4 "Drive Cycle Electrical Energy State 4";
BA_ "VNSigAllNodes" SG_ 2151858176 DrvCycElecEngySt4 1;
BA_ "GenSigDeltaValue" SG_ 2151858176 DrvCycElecEngySt3 1;
BA_ "GenSigSendType" SG_ 2151858176 DrvCycElecEngySt3 12;
BA_ "GenSigSendOnInit" SG_ 2151858176 DrvCycElecEngySt3 1;
BA_ "VNSigInfotainment" SG_ 2151858176 DrvCycElecEngySt3 1;
BA_ "SignalType" SG_ 2151858176 DrvCycElecEngySt3 "UNM";
BA_ "SignalLongName" SG_ 2151858176 DrvCycElecEngySt3 "Drive Cycle Electrical Energy State 3";
BA_ "VNSigAllNodes" SG_ 2151858176 DrvCycElecEngySt3 1;
BA_ "GenSigDeltaValue" SG_ 2151858176 DrvCycElecEngySt2 1;
BA_ "GenSigSendType" SG_ 2151858176 DrvCycElecEngySt2 12;
BA_ "GenSigSendOnInit" SG_ 2151858176 DrvCycElecEngySt2 1;
BA_ "VNSigInfotainment" SG_ 2151858176 DrvCycElecEngySt2 1;
BA_ "SignalType" SG_ 2151858176 DrvCycElecEngySt2 "UNM";
BA_ "SignalLongName" SG_ 2151858176 DrvCycElecEngySt2 "Drive Cycle Electrical Energy State 2";
BA_ "VNSigAllNodes" SG_ 2151858176 DrvCycElecEngySt2 1;
BA_ "GenSigDeltaValue" SG_ 2151858176 DrvCycElecEngySt1 1;
BA_ "GenSigSendType" SG_ 2151858176 DrvCycElecEngySt1 12;
BA_ "GenSigSendOnInit" SG_ 2151858176 DrvCycElecEngySt1 1;
BA_ "VNSigInfotainment" SG_ 2151858176 DrvCycElecEngySt1 1;
BA_ "SignalType" SG_ 2151858176 DrvCycElecEngySt1 "UNM";
BA_ "SignalLongName" SG_ 2151858176 DrvCycElecEngySt1 "Drive Cycle Electrical Energy State 1";
BA_ "VNSigAllNodes" SG_ 2151858176 DrvCycElecEngySt1 1;
BA_ "GenSigDeltaValue" SG_ 2151809024 ElecEngyEconAvg 1;
BA_ "GenSigSendType" SG_ 2151809024 ElecEngyEconAvg 12;
BA_ "SignalType" SG_ 2151809024 ElecEngyEconAvg "UNM";
BA_ "SignalLongName" SG_ 2151809024 ElecEngyEconAvg "Electrical Energy Economy Average";
BA_ "VNSigAllNodes" SG_ 2151809024 ElecEngyEconAvg 1;
BA_ "GenSigDeltaValue" SG_ 2151809024 DrvCycElecEngySt5 1;
BA_ "GenSigSendType" SG_ 2151809024 DrvCycElecEngySt5 12;
BA_ "GenSigSendOnInit" SG_ 2151809024 DrvCycElecEngySt5 1;
BA_ "VNSigInfotainment" SG_ 2151809024 DrvCycElecEngySt5 1;
BA_ "SignalType" SG_ 2151809024 DrvCycElecEngySt5 "UNM";
BA_ "SignalLongName" SG_ 2151809024 DrvCycElecEngySt5 "Drive Cycle Electrical Energy State 5";
BA_ "VNSigAllNodes" SG_ 2151809024 DrvCycElecEngySt5 1;
BA_ "GenSigDeltaValue" SG_ 2151809024 DCEEC_EngyPct4 1;
BA_ "GenSigSendType" SG_ 2151809024 DCEEC_EngyPct4 12;
BA_ "GenSigSendOnInit" SG_ 2151809024 DCEEC_EngyPct4 1;
BA_ "VNSigInfotainment" SG_ 2151809024 DCEEC_EngyPct4 1;
BA_ "SignalType" SG_ 2151809024 DCEEC_EngyPct4 "UNM";
BA_ "PacketOrder" SG_ 2151809024 DCEEC_EngyPct4 4;
BA_ "SignalLongName" SG_ 2151809024 DCEEC_EngyPct4 "Drive Cycle Electrical Energy Consumed : Energy Percent 4";
BA_ "VNSigAllNodes" SG_ 2151809024 DCEEC_EngyPct4 1;
BA_ "GenSigDeltaValue" SG_ 2151809024 DCEEC_EngyPct3 1;
BA_ "GenSigSendType" SG_ 2151809024 DCEEC_EngyPct3 12;
BA_ "GenSigSendOnInit" SG_ 2151809024 DCEEC_EngyPct3 1;
BA_ "VNSigInfotainment" SG_ 2151809024 DCEEC_EngyPct3 1;
BA_ "SignalType" SG_ 2151809024 DCEEC_EngyPct3 "UNM";
BA_ "PacketOrder" SG_ 2151809024 DCEEC_EngyPct3 3;
BA_ "SignalLongName" SG_ 2151809024 DCEEC_EngyPct3 "Drive Cycle Electrical Energy Consumed : Energy Percent 3";
BA_ "VNSigAllNodes" SG_ 2151809024 DCEEC_EngyPct3 1;
BA_ "GenSigSendType" SG_ 2151809024 DCEEC_EngyPct2 12;
BA_ "GenSigSendOnInit" SG_ 2151809024 DCEEC_EngyPct2 1;
BA_ "VNSigInfotainment" SG_ 2151809024 DCEEC_EngyPct2 1;
BA_ "SignalType" SG_ 2151809024 DCEEC_EngyPct2 "UNM";
BA_ "PacketOrder" SG_ 2151809024 DCEEC_EngyPct2 2;
BA_ "SignalLongName" SG_ 2151809024 DCEEC_EngyPct2 "Drive Cycle Electrical Energy Consumed : Energy Percent 2";
BA_ "VNSigAllNodes" SG_ 2151809024 DCEEC_EngyPct2 1;
BA_ "GenSigDeltaValue" SG_ 2151809024 DCEEC_EngyPct1 1;
BA_ "GenSigSendType" SG_ 2151809024 DCEEC_EngyPct1 12;
BA_ "GenSigSendOnInit" SG_ 2151809024 DCEEC_EngyPct1 1;
BA_ "VNSigInfotainment" SG_ 2151809024 DCEEC_EngyPct1 1;
BA_ "SignalType" SG_ 2151809024 DCEEC_EngyPct1 "UNM";
BA_ "PacketOrder" SG_ 2151809024 DCEEC_EngyPct1 1;
BA_ "SignalLongName" SG_ 2151809024 DCEEC_EngyPct1 "Drive Cycle Electrical Energy Consumed : Energy Percent 1";
BA_ "VNSigAllNodes" SG_ 2151809024 DCEEC_EngyPct1 1;
BA_ "GenSigSendType" SG_ 2151792640 RCTARIC_Indctr1Act 10;
BA_ "SignalType" SG_ 2151792640 RCTARIC_Indctr1Act "BLN";
BA_ "PacketOrder" SG_ 2151792640 RCTARIC_Indctr1Act 1;
BA_ "SignalLongName" SG_ 2151792640 RCTARIC_Indctr1Act "Rear Cross Traffic Alert Right Indication Control : Indicator 1 Active";
BA_ "VNSigAllNodes" SG_ 2151792640 RCTARIC_Indctr1Act 1;
BA_ "GenSigSendType" SG_ 2151792640 RCTARIC_IndReq 10;
BA_ "SignalType" SG_ 2151792640 RCTARIC_IndReq "ENM";
BA_ "PacketOrder" SG_ 2151792640 RCTARIC_IndReq 2;
BA_ "SignalLongName" SG_ 2151792640 RCTARIC_IndReq "Rear Cross Traffic Alert Right Indication Control : Indication Request";
BA_ "VNSigAllNodes" SG_ 2151792640 RCTARIC_IndReq 1;
BA_ "GenSigDeltaValue" SG_ 2151792640 RrCTfcRHptcStRqSqN 1;
BA_ "GenSigSendType" SG_ 2151792640 RrCTfcRHptcStRqSqN 12;
BA_ "SignalType" SG_ 2151792640 RrCTfcRHptcStRqSqN "UNM";
BA_ "SignalLongName" SG_ 2151792640 RrCTfcRHptcStRqSqN "Rear Cross Traffic Alert Right Haptic Seat Request Sequence Number";
BA_ "VNSigAllNodes" SG_ 2151792640 RrCTfcRHptcStRqSqN 1;
BA_ "GenSigDeltaValue" SG_ 2151792640 RrCTfcRHptcStReq 1;
BA_ "GenSigSendType" SG_ 2151792640 RrCTfcRHptcStReq 12;
BA_ "SignalType" SG_ 2151792640 RrCTfcRHptcStReq "UNM";
BA_ "SignalLongName" SG_ 2151792640 RrCTfcRHptcStReq "Rear Cross Traffic Alert Right Haptic Seat Request";
BA_ "VNSigAllNodes" SG_ 2151792640 RrCTfcRHptcStReq 1;
BA_ "GenSigSendType" SG_ 2151776256 RCTALIC_Indctr1Act 10;
BA_ "SignalType" SG_ 2151776256 RCTALIC_Indctr1Act "BLN";
BA_ "PacketOrder" SG_ 2151776256 RCTALIC_Indctr1Act 1;
BA_ "SignalLongName" SG_ 2151776256 RCTALIC_Indctr1Act "Rear Cross Traffic Alert Left Indication Control : Indicator 1 Active";
BA_ "VNSigAllNodes" SG_ 2151776256 RCTALIC_Indctr1Act 1;
BA_ "GenSigSendType" SG_ 2151776256 RCTALIC_IndReq 10;
BA_ "SignalType" SG_ 2151776256 RCTALIC_IndReq "ENM";
BA_ "PacketOrder" SG_ 2151776256 RCTALIC_IndReq 2;
BA_ "SignalLongName" SG_ 2151776256 RCTALIC_IndReq "Rear Cross Traffic Alert Left Indication Control : Indication Request";
BA_ "VNSigAllNodes" SG_ 2151776256 RCTALIC_IndReq 1;
BA_ "GenSigDeltaValue" SG_ 2151776256 RrCTfcLHptcStRqSeqN 1;
BA_ "GenSigSendType" SG_ 2151776256 RrCTfcLHptcStRqSeqN 12;
BA_ "SignalType" SG_ 2151776256 RrCTfcLHptcStRqSeqN "UNM";
BA_ "SignalLongName" SG_ 2151776256 RrCTfcLHptcStRqSeqN "Rear Cross Traffic Alert Left Haptic Seat Request Sequence Number";
BA_ "VNSigAllNodes" SG_ 2151776256 RrCTfcLHptcStRqSeqN 1;
BA_ "GenSigDeltaValue" SG_ 2151776256 RrCTfcLHptcStReq 1;
BA_ "GenSigSendType" SG_ 2151776256 RrCTfcLHptcStReq 12;
BA_ "SignalType" SG_ 2151776256 RrCTfcLHptcStReq "UNM";
BA_ "SignalLongName" SG_ 2151776256 RrCTfcLHptcStReq "Rear Cross Traffic Alert Left Haptic Seat Request";
BA_ "VNSigAllNodes" SG_ 2151776256 RrCTfcLHptcStReq 1;
BA_ "SignalType" SG_ 2151899136 PTOAccelUpnBrkRelIO "BLN";
BA_ "SignalLongName" SG_ 2151899136 PTOAccelUpnBrkRelIO "Power Take Off Acceleration Upon Brake Release Indication On";
BA_ "VNSigAllNodes" SG_ 2151899136 PTOAccelUpnBrkRelIO 1;
BA_ "SignalType" SG_ 2151899136 PTOEngUpnBrkRelIO "BLN";
BA_ "SignalLongName" SG_ 2151899136 PTOEngUpnBrkRelIO "Power Take Off Engage Upon Brake Release Indication On";
BA_ "VNSigAllNodes" SG_ 2151899136 PTOEngUpnBrkRelIO 1;
BA_ "SignalType" SG_ 2151899136 PTOManTransInGrIO "BLN";
BA_ "SignalLongName" SG_ 2151899136 PTOManTransInGrIO "Power Take Off Manual Transmission In Gear Indication On";
BA_ "VNSigAllNodes" SG_ 2151899136 PTOManTransInGrIO 1;
BA_ "SignalType" SG_ 2151899136 PTOServIndOn "BLN";
BA_ "SignalLongName" SG_ 2151899136 PTOServIndOn "Power Take Off Service Indication On";
BA_ "VNSigAllNodes" SG_ 2151899136 PTOServIndOn 1;
BA_ "SignalType" SG_ 2151899136 PTOVDM "ENM";
BA_ "SignalLongName" SG_ 2151899136 PTOVDM "Power Take Off Virtual Device Mask";
BA_ "VNSigAllNodes" SG_ 2151899136 PTOVDM 1;
BA_ "SignalType" SG_ 2151899136 PTOVDA "ENM";
BA_ "SignalLongName" SG_ 2151899136 PTOVDA "Power Take Off Virtual Device Availability";
BA_ "GenSigStartValue" SG_ 2151899136 PTOVDA 1;
BA_ "VNSigAllNodes" SG_ 2151899136 PTOVDA 1;
BA_ "SignalType" SG_ 2151899136 PTOTransInGearIO "BLN";
BA_ "SignalLongName" SG_ 2151899136 PTOTransInGearIO "Power Take Off Transmission In Gear Indication On";
BA_ "VNSigAllNodes" SG_ 2151899136 PTOTransInGearIO 1;
BA_ "VNSigInfotainment" SG_ 2151899136 PTOTpStpSpdCsStAvl 1;
BA_ "SignalType" SG_ 2151899136 PTOTpStpSpdCsStAvl "BLN";
BA_ "SignalLongName" SG_ 2151899136 PTOTpStpSpdCsStAvl "Power Take Off Tap Step Speed Customization Setting Available";
BA_ "VNSigAllNodes" SG_ 2151899136 PTOTpStpSpdCsStAvl 1;
BA_ "VNSigInfotainment" SG_ 2151899136 PTOTpStSpdCsCrStVal 1;
BA_ "SignalType" SG_ 2151899136 PTOTpStSpdCsCrStVal "ENM";
BA_ "SignalLongName" SG_ 2151899136 PTOTpStSpdCsCrStVal "Power Take Off Tap Step Speed Customization Current Setting Value";
BA_ "VNSigAllNodes" SG_ 2151899136 PTOTpStSpdCsCrStVal 1;
BA_ "VNSigInfotainment" SG_ 2151899136 PTOStdbySpdCsStAvl 1;
BA_ "SignalType" SG_ 2151899136 PTOStdbySpdCsStAvl "BLN";
BA_ "SignalLongName" SG_ 2151899136 PTOStdbySpdCsStAvl "Power Take Off Standby Speed Customization Setting Available";
BA_ "VNSigAllNodes" SG_ 2151899136 PTOStdbySpdCsStAvl 1;
BA_ "VNSigInfotainment" SG_ 2151899136 PTOStdbSpdCsCrStVal 1;
BA_ "SignalType" SG_ 2151899136 PTOStdbSpdCsCrStVal "ENM";
BA_ "SignalLongName" SG_ 2151899136 PTOStdbSpdCsCrStVal "Power Take Off Standby Speed Customization Current Setting Value";
BA_ "VNSigAllNodes" SG_ 2151899136 PTOStdbSpdCsCrStVal 1;
BA_ "SignalType" SG_ 2151899136 PTOSetPrkBrkIO "BLN";
BA_ "SignalLongName" SG_ 2151899136 PTOSetPrkBrkIO "Power Take Off Set Park Brake Indication On";
BA_ "VNSigAllNodes" SG_ 2151899136 PTOSetPrkBrkIO 1;
BA_ "VNSigInfotainment" SG_ 2151899136 PTOSet2SpdCsStAvl 1;
BA_ "SignalType" SG_ 2151899136 PTOSet2SpdCsStAvl "BLN";
BA_ "SignalLongName" SG_ 2151899136 PTOSet2SpdCsStAvl "Power Take Off Set 2 Speed Customization Setting Available";
BA_ "VNSigAllNodes" SG_ 2151899136 PTOSet2SpdCsStAvl 1;
BA_ "VNSigInfotainment" SG_ 2151899136 PTOSet2SpdCsCrStVal 1;
BA_ "SignalType" SG_ 2151899136 PTOSet2SpdCsCrStVal "ENM";
BA_ "SignalLongName" SG_ 2151899136 PTOSet2SpdCsCrStVal "Power Take Off Set 2 Speed Customization Current Setting Value";
BA_ "VNSigAllNodes" SG_ 2151899136 PTOSet2SpdCsCrStVal 1;
BA_ "VNSigInfotainment" SG_ 2151899136 PTOSet1SpdCsStAvl 1;
BA_ "SignalType" SG_ 2151899136 PTOSet1SpdCsStAvl "BLN";
BA_ "SignalLongName" SG_ 2151899136 PTOSet1SpdCsStAvl "Power Take Off Set 1 Speed Customization Setting Available";
BA_ "VNSigAllNodes" SG_ 2151899136 PTOSet1SpdCsStAvl 1;
BA_ "VNSigInfotainment" SG_ 2151899136 PTOSet1SpdCsCrStVal 1;
BA_ "SignalType" SG_ 2151899136 PTOSet1SpdCsCrStVal "ENM";
BA_ "SignalLongName" SG_ 2151899136 PTOSet1SpdCsCrStVal "Power Take Off Set 1 Speed Customization Current Setting Value";
BA_ "VNSigAllNodes" SG_ 2151899136 PTOSet1SpdCsCrStVal 1;
BA_ "SignalType" SG_ 2151899136 PTORelCltPedIO "BLN";
BA_ "SignalLongName" SG_ 2151899136 PTORelCltPedIO "Power Take Off Release Clutch Pedal Indication On";
BA_ "VNSigAllNodes" SG_ 2151899136 PTORelCltPedIO 1;
BA_ "SignalType" SG_ 2151899136 PTORelBrkPedIO "BLN";
BA_ "SignalLongName" SG_ 2151899136 PTORelBrkPedIO "Power Take Off Release Brake Pedal Indication On";
BA_ "VNSigAllNodes" SG_ 2151899136 PTORelBrkPedIO 1;
BA_ "SignalType" SG_ 2151899136 PTORelAccPedIO "BLN";
BA_ "SignalLongName" SG_ 2151899136 PTORelAccPedIO "Power Take Off Release Accelerator Pedal Indication On";
BA_ "VNSigAllNodes" SG_ 2151899136 PTORelAccPedIO 1;
BA_ "SignalType" SG_ 2151899136 PTORedEngSpdIO "BLN";
BA_ "SignalLongName" SG_ 2151899136 PTORedEngSpdIO "Power Take Off Reduce Engine Speed Indication On";
BA_ "VNSigAllNodes" SG_ 2151899136 PTORedEngSpdIO 1;
BA_ "SignalType" SG_ 2151899136 PTOPrsRelCltPedIO "BLN";
BA_ "SignalLongName" SG_ 2151899136 PTOPrsRelCltPedIO "Power Take Off Press and Release Clutch Pedal Indication On";
BA_ "VNSigAllNodes" SG_ 2151899136 PTOPrsRelCltPedIO 1;
BA_ "SignalType" SG_ 2151899136 PTOPrsRelBrkPedIO "BLN";
BA_ "SignalLongName" SG_ 2151899136 PTOPrsRelBrkPedIO "Power Take Off Press and Release Brake Pedal Indication On";
BA_ "VNSigAllNodes" SG_ 2151899136 PTOPrsRelBrkPedIO 1;
BA_ "VNSigInfotainment" SG_ 2151899136 PTOEngRnTmrCsStAvl 1;
BA_ "SignalType" SG_ 2151899136 PTOEngRnTmrCsStAvl "BLN";
BA_ "SignalLongName" SG_ 2151899136 PTOEngRnTmrCsStAvl "Power Take Off Engine Run Timer Customization Setting Available";
BA_ "VNSigAllNodes" SG_ 2151899136 PTOEngRnTmrCsStAvl 1;
BA_ "VNSigInfotainment" SG_ 2151899136 PTOEnRnTmCsCrStVal 1;
BA_ "SignalType" SG_ 2151899136 PTOEnRnTmCsCrStVal "ENM";
BA_ "SignalLongName" SG_ 2151899136 PTOEnRnTmCsCrStVal "Power Take Off Engine Run Timer Customization Current Setting Value";
BA_ "VNSigAllNodes" SG_ 2151899136 PTOEnRnTmCsCrStVal 1;
BA_ "SignalType" SG_ 2151899136 PTOEngmntStatInd "ENM";
BA_ "SignalLongName" SG_ 2151899136 PTOEngmntStatInd "Power Take Off Engagement Status Indication";
BA_ "VNSigAllNodes" SG_ 2151899136 PTOEngmntStatInd 1;
BA_ "SignalType" SG_ 2151899136 PTODisengCrsCntlIO "BLN";
BA_ "SignalLongName" SG_ 2151899136 PTODisengCrsCntlIO "Power Take Off Disengage Cruise Control Indication On";
BA_ "VNSigAllNodes" SG_ 2151899136 PTODisengCrsCntlIO 1;
BA_ "GenSigSendType" SG_ 2151882752 PTOTpStpSpdCsStReq 10;
BA_ "VNSigInfotainment" SG_ 2151882752 PTOTpStpSpdCsStReq 1;
BA_ "SignalType" SG_ 2151882752 PTOTpStpSpdCsStReq "ENM";
BA_ "SignalLongName" SG_ 2151882752 PTOTpStpSpdCsStReq "Power Take Off Tap Step Speed Customization Setting Request";
BA_ "VNSigAllNodes" SG_ 2151882752 PTOTpStpSpdCsStReq 1;
BA_ "GenSigSendType" SG_ 2151882752 PTOStdbySpdCsStReq 10;
BA_ "VNSigInfotainment" SG_ 2151882752 PTOStdbySpdCsStReq 1;
BA_ "SignalType" SG_ 2151882752 PTOStdbySpdCsStReq "ENM";
BA_ "SignalLongName" SG_ 2151882752 PTOStdbySpdCsStReq "Power Take Off Standby Speed Customization Setting Request";
BA_ "VNSigAllNodes" SG_ 2151882752 PTOStdbySpdCsStReq 1;
BA_ "GenSigSendType" SG_ 2151882752 PTOEngRnTmrCsStRq 10;
BA_ "VNSigInfotainment" SG_ 2151882752 PTOEngRnTmrCsStRq 1;
BA_ "SignalType" SG_ 2151882752 PTOEngRnTmrCsStRq "ENM";
BA_ "SignalLongName" SG_ 2151882752 PTOEngRnTmrCsStRq "Power Take Off Engine Run Timer Customization Setting Request";
BA_ "VNSigAllNodes" SG_ 2151882752 PTOEngRnTmrCsStRq 1;
BA_ "GenSigSendType" SG_ 2151882752 PTOSet2SpdCsStReq 10;
BA_ "VNSigInfotainment" SG_ 2151882752 PTOSet2SpdCsStReq 1;
BA_ "SignalType" SG_ 2151882752 PTOSet2SpdCsStReq "ENM";
BA_ "SignalLongName" SG_ 2151882752 PTOSet2SpdCsStReq "Power Take Off Set 2 Speed Customization Setting Request";
BA_ "VNSigAllNodes" SG_ 2151882752 PTOSet2SpdCsStReq 1;
BA_ "GenSigSendType" SG_ 2151882752 PTOSet1SpdCsStReq 10;
BA_ "VNSigInfotainment" SG_ 2151882752 PTOSet1SpdCsStReq 1;
BA_ "SignalType" SG_ 2151882752 PTOSet1SpdCsStReq "ENM";
BA_ "SignalLongName" SG_ 2151882752 PTOSet1SpdCsStReq "Power Take Off Set 1 Speed Customization Setting Request";
BA_ "VNSigAllNodes" SG_ 2151882752 PTOSet1SpdCsStReq 1;
BA_ "SignalType" SG_ 2155913216 PFAS_SrvPedAlrtIO "BLN";
BA_ "PacketOrder" SG_ 2155913216 PFAS_SrvPedAlrtIO 7;
BA_ "SignalLongName" SG_ 2155913216 PFAS_SrvPedAlrtIO "Pedestrian Friendly Alert Status : Service Pedestrian Friendly Alert Indication On";
BA_ "VNSigAllNodes" SG_ 2155913216 PFAS_SrvPedAlrtIO 1;
BA_ "SignalType" SG_ 2155913216 PFAS_PFASysStat "ENM";
BA_ "PacketOrder" SG_ 2155913216 PFAS_PFASysStat 6;
BA_ "SignalLongName" SG_ 2155913216 PFAS_PFASysStat "Pedestrian Friendly Alert Status : Pedestrian Friendly Alert System Status";
BA_ "VNSigAllNodes" SG_ 2155913216 PFAS_PFASysStat 1;
BA_ "SignalType" SG_ 2155913216 PFAS_PFASndVolCtrl "UNM";
BA_ "PacketOrder" SG_ 2155913216 PFAS_PFASndVolCtrl 5;
BA_ "SignalLongName" SG_ 2155913216 PFAS_PFASndVolCtrl "Pedestrian Friendly Alert Status : Pedestrian Friendly Alert Sound Volume Control";
BA_ "VNSigAllNodes" SG_ 2155913216 PFAS_PFASndVolCtrl 1;
BA_ "SignalType" SG_ 2155913216 PFAS_PFASndGenEn "BLN";
BA_ "PacketOrder" SG_ 2155913216 PFAS_PFASndGenEn 1;
BA_ "SignalLongName" SG_ 2155913216 PFAS_PFASndGenEn "Pedestrian Friendly Alert Status : Pedestrian Friendly Alert Sound Generation Enable";
BA_ "VNSigAllNodes" SG_ 2155913216 PFAS_PFASndGenEn 1;
BA_ "SignalType" SG_ 2155913216 PFAS_PFARevSnd "ENM";
BA_ "PacketOrder" SG_ 2155913216 PFAS_PFARevSnd 3;
BA_ "SignalLongName" SG_ 2155913216 PFAS_PFARevSnd "Pedestrian Friendly Alert Status : Pedestrian Friendly Alert Reverse Sound";
BA_ "VNSigAllNodes" SG_ 2155913216 PFAS_PFARevSnd 1;
BA_ "SignalType" SG_ 2155913216 PFAS_PFAFwdSnd "ENM";
BA_ "PacketOrder" SG_ 2155913216 PFAS_PFAFwdSnd 2;
BA_ "SignalLongName" SG_ 2155913216 PFAS_PFAFwdSnd "Pedestrian Friendly Alert Status : Pedestrian Friendly Alert Forward Sound";
BA_ "VNSigAllNodes" SG_ 2155913216 PFAS_PFAFwdSnd 1;
BA_ "SignalType" SG_ 2155913216 PFAS_PFACrsOvrSpd "UNM";
BA_ "PacketOrder" SG_ 2155913216 PFAS_PFACrsOvrSpd 4;
BA_ "SignalLongName" SG_ 2155913216 PFAS_PFACrsOvrSpd "Pedestrian Friendly Alert Status : Pedestrian Friendly Alert Crossover Speed";
BA_ "VNSigAllNodes" SG_ 2155913216 PFAS_PFACrsOvrSpd 1;
BA_ "SignalType" SG_ 2155913216 PedFrndlyAlrtCsSetAvl "BLN";
BA_ "SignalLongName" SG_ 2155913216 PedFrndlyAlrtCsSetAvl "Pedestrian Friendly Alert Customization Setting Available";
BA_ "VNSigAllNodes" SG_ 2155913216 PedFrndlyAlrtCsSetAvl 1;
BA_ "SignalType" SG_ 2155913216 PedFrndlyAlrtCsCrStVal "ENM";
BA_ "SignalLongName" SG_ 2155913216 PedFrndlyAlrtCsCrStVal "Pedestrian Friendly Alert Customization Current Setting Value";
BA_ "VNSigAllNodes" SG_ 2155913216 PedFrndlyAlrtCsCrStVal 1;
BA_ "SignalType" SG_ 2155913216 DslExhFldRmngDstHRs "UNM";
BA_ "SignalLongName" SG_ 2155913216 DslExhFldRmngDstHRs "Diesel Exhaust Fluid Remaining Distance High Resolution";
BA_ "VNSigAllNodes" SG_ 2155913216 DslExhFldRmngDstHRs 1;
BA_ "SignalType" SG_ 2155913216 DslExhFluidLvlPrcntV "ENM";
BA_ "SignalLongName" SG_ 2155913216 DslExhFluidLvlPrcntV "Diesel Exhaust Fluid Level Percent Validity";
BA_ "VNSigAllNodes" SG_ 2155913216 DslExhFluidLvlPrcntV 1;
BA_ "SignalType" SG_ 2155913216 DslExhFluidLvlPrcnt "UNM";
BA_ "SignalLongName" SG_ 2155913216 DslExhFluidLvlPrcnt "Diesel Exhaust Fluid Level Percent";
BA_ "VNSigAllNodes" SG_ 2155913216 DslExhFluidLvlPrcnt 1;
BA_ "SignalType" SG_ 2155913216 DslEmnsOBDMrkt "ENM";
BA_ "SignalLongName" SG_ 2155913216 DslEmnsOBDMrkt "Diesel Emissions OBD Market";
BA_ "VNSigAllNodes" SG_ 2155913216 DslEmnsOBDMrkt 1;
BA_ "SignalType" SG_ 2155913216 DslExhFldRmngDstHRsV "ENM";
BA_ "SignalLongName" SG_ 2155913216 DslExhFldRmngDstHRsV "Diesel Exhaust Fluid Remaining Distance High Resolution Validity";
BA_ "VNSigAllNodes" SG_ 2155913216 DslExhFldRmngDstHRsV 1;
BA_ "GenSigSendType" SG_ 2154790912 AdpHgBmAsSnCsCrStVal 10;
BA_ "GenSigSendOnInit" SG_ 2154790912 AdpHgBmAsSnCsCrStVal 2;
BA_ "SignalType" SG_ 2154790912 AdpHgBmAsSnCsCrStVal "ENM";
BA_ "SignalLongName" SG_ 2154790912 AdpHgBmAsSnCsCrStVal "Adaptive High Beam Assist With Sensitivity Customization Current Setting Value";
BA_ "VNSigAllNodes" SG_ 2154790912 AdpHgBmAsSnCsCrStVal 1;
BA_ "GenSigSendType" SG_ 2154790912 AdpHgBmAsSnCsStAvl 10;
BA_ "GenSigSendOnInit" SG_ 2154790912 AdpHgBmAsSnCsStAvl 2;
BA_ "SignalType" SG_ 2154790912 AdpHgBmAsSnCsStAvl "BLN";
BA_ "SignalLongName" SG_ 2154790912 AdpHgBmAsSnCsStAvl "Adaptive High Beam Assist With Sensitivity Customization Setting Available";
BA_ "VNSigAllNodes" SG_ 2154790912 AdpHgBmAsSnCsStAvl 1;
BA_ "GenSigSendType" SG_ 2154790912 AdpHgBmAsCsCrStVal 10;
BA_ "GenSigSendOnInit" SG_ 2154790912 AdpHgBmAsCsCrStVal 2;
BA_ "SignalType" SG_ 2154790912 AdpHgBmAsCsCrStVal "ENM";
BA_ "SignalLongName" SG_ 2154790912 AdpHgBmAsCsCrStVal "Adaptive High Beam Assist Customization Current Setting Value";
BA_ "VNSigAllNodes" SG_ 2154790912 AdpHgBmAsCsCrStVal 1;
BA_ "GenSigSendType" SG_ 2154790912 AdpHgBmAsCsStAvl 10;
BA_ "GenSigSendOnInit" SG_ 2154790912 AdpHgBmAsCsStAvl 2;
BA_ "SignalType" SG_ 2154790912 AdpHgBmAsCsStAvl "BLN";
BA_ "SignalLongName" SG_ 2154790912 AdpHgBmAsCsStAvl "Adaptive High Beam Assist Customization Setting Available";
BA_ "VNSigAllNodes" SG_ 2154790912 AdpHgBmAsCsStAvl 1;
BA_ "GenSigSendType" SG_ 2154790912 AutHgBmAsCsCrStVal 10;
BA_ "GenSigSendOnInit" SG_ 2154790912 AutHgBmAsCsCrStVal 2;
BA_ "SignalType" SG_ 2154790912 AutHgBmAsCsCrStVal "ENM";
BA_ "SignalLongName" SG_ 2154790912 AutHgBmAsCsCrStVal "Auto High Beam Assist Customization Current Setting Value";
BA_ "VNSigAllNodes" SG_ 2154790912 AutHgBmAsCsCrStVal 1;
BA_ "GenSigSendType" SG_ 2154790912 AutHgBmAsSnCsStAvl 10;
BA_ "GenSigSendOnInit" SG_ 2154790912 AutHgBmAsSnCsStAvl 2;
BA_ "SignalType" SG_ 2154790912 AutHgBmAsSnCsStAvl "BLN";
BA_ "SignalLongName" SG_ 2154790912 AutHgBmAsSnCsStAvl "Auto High Beam Assist With Sensitivity Customization Setting Available";
BA_ "VNSigAllNodes" SG_ 2154790912 AutHgBmAsSnCsStAvl 1;
BA_ "GenSigSendType" SG_ 2154790912 AutHgBmAsSnCsCrStVa 10;
BA_ "GenSigSendOnInit" SG_ 2154790912 AutHgBmAsSnCsCrStVa 2;
BA_ "SignalType" SG_ 2154790912 AutHgBmAsSnCsCrStVa "ENM";
BA_ "SignalLongName" SG_ 2154790912 AutHgBmAsSnCsCrStVa "Auto High Beam Assist With Sensitivity Customization Current Setting Value";
BA_ "VNSigAllNodes" SG_ 2154790912 AutHgBmAsSnCsCrStVa 1;
BA_ "GenSigSendType" SG_ 2154790912 AutHgBmAsCsStAvl 10;
BA_ "GenSigSendOnInit" SG_ 2154790912 AutHgBmAsCsStAvl 2;
BA_ "SignalType" SG_ 2154790912 AutHgBmAsCsStAvl "BLN";
BA_ "SignalLongName" SG_ 2154790912 AutHgBmAsCsStAvl "Auto High Beam Assist Customization Setting Available";
BA_ "VNSigAllNodes" SG_ 2154790912 AutHgBmAsCsStAvl 1;
BA_ "GenSigSendType" SG_ 2154774528 LtRtHnTrGPSCsStAvl 10;
BA_ "GenSigSendOnInit" SG_ 2154774528 LtRtHnTrGPSCsStAvl 2;
BA_ "SignalType" SG_ 2154774528 LtRtHnTrGPSCsStAvl "BLN";
BA_ "SignalLongName" SG_ 2154774528 LtRtHnTrGPSCsStAvl "Left Right Hand Traffic With GPS Customization Setting Available";
BA_ "VNSigAllNodes" SG_ 2154774528 LtRtHnTrGPSCsStAvl 1;
BA_ "GenSigSendType" SG_ 2154774528 LtRtHnTrGPCsCrStVal 10;
BA_ "GenSigSendOnInit" SG_ 2154774528 LtRtHnTrGPCsCrStVal 2;
BA_ "SignalType" SG_ 2154774528 LtRtHnTrGPCsCrStVal "ENM";
BA_ "SignalLongName" SG_ 2154774528 LtRtHnTrGPCsCrStVal "Left Right Hand Traffic With GPS Customization Current Setting Value";
BA_ "VNSigAllNodes" SG_ 2154774528 LtRtHnTrGPCsCrStVal 1;
BA_ "GenSigSendType" SG_ 2154774528 LtRtHnTrCstStVal 10;
BA_ "GenSigSendOnInit" SG_ 2154774528 LtRtHnTrCstStVal 2;
BA_ "SignalType" SG_ 2154774528 LtRtHnTrCstStVal "ENM";
BA_ "SignalLongName" SG_ 2154774528 LtRtHnTrCstStVal "Left Right Hand Traffic Customization Current Setting Value";
BA_ "VNSigAllNodes" SG_ 2154774528 LtRtHnTrCstStVal 1;
BA_ "GenSigSendType" SG_ 2154774528 LtRtHnTrCstStAvail 10;
BA_ "GenSigSendOnInit" SG_ 2154774528 LtRtHnTrCstStAvail 2;
BA_ "SignalType" SG_ 2154774528 LtRtHnTrCstStAvail "ENM";
BA_ "SignalLongName" SG_ 2154774528 LtRtHnTrCstStAvail "Left Right Hand Traffic Customization Setting Available";
BA_ "VNSigAllNodes" SG_ 2154774528 LtRtHnTrCstStAvail 1;
BA_ "GenSigSendType" SG_ 2151178240 TrlrMirVGlnCustSetReq 10;
BA_ "SignalType" SG_ 2151178240 TrlrMirVGlnCustSetReq "ENM";
BA_ "SignalLongName" SG_ 2151178240 TrlrMirVGlnCustSetReq "Trailering Mirror Video Guidelines Customization Setting Request";
BA_ "VNSigAllNodes" SG_ 2151178240 TrlrMirVGlnCustSetReq 1;
BA_ "GenSigSendType" SG_ 2151178240 TrlrMirVEnCustSetReq 10;
BA_ "SignalType" SG_ 2151178240 TrlrMirVEnCustSetReq "ENM";
BA_ "SignalLongName" SG_ 2151178240 TrlrMirVEnCustSetReq "Trailering Mirror Video Enable Customization Setting Request";
BA_ "VNSigAllNodes" SG_ 2151178240 TrlrMirVEnCustSetReq 1;
BA_ "GenSigSendType" SG_ 2151178240 JacknfDetCustSetReq 10;
BA_ "SignalType" SG_ 2151178240 JacknfDetCustSetReq "ENM";
BA_ "SignalLongName" SG_ 2151178240 JacknfDetCustSetReq "Jack Knife Detection Customization Setting Request";
BA_ "VNSigAllNodes" SG_ 2151178240 JacknfDetCustSetReq 1;
BA_ "GenSigSendType" SG_ 2151178240 CrgBdVwLtCustSetReq 10;
BA_ "SignalType" SG_ 2151178240 CrgBdVwLtCustSetReq "ENM";
BA_ "SignalLongName" SG_ 2151178240 CrgBdVwLtCustSetReq "Cargo Bed View Auto Lighting Customization Setting Request";
BA_ "VNSigAllNodes" SG_ 2151178240 CrgBdVwLtCustSetReq 1;
BA_ "GenSigSendType" SG_ 2151178240 AFLGPSCstStReq 10;
BA_ "SignalType" SG_ 2151178240 AFLGPSCstStReq "ENM";
BA_ "SignalLongName" SG_ 2151178240 AFLGPSCstStReq "Adaptive Forward Lighting With GPS Customization Setting Request";
BA_ "VNSigAllNodes" SG_ 2151178240 AFLGPSCstStReq 1;
BA_ "GenSigSendType" SG_ 2151178240 AFLCstStReq 10;
BA_ "SignalType" SG_ 2151178240 AFLCstStReq "ENM";
BA_ "SignalLongName" SG_ 2151178240 AFLCstStReq "Adaptive Forward Lighting Customization Setting Request";
BA_ "VNSigAllNodes" SG_ 2151178240 AFLCstStReq 1;
BA_ "GenSigSendType" SG_ 2151178240 LtRtHnTrCstStReq 10;
BA_ "SignalType" SG_ 2151178240 LtRtHnTrCstStReq "ENM";
BA_ "SignalLongName" SG_ 2151178240 LtRtHnTrCstStReq "Left Right Hand Traffic Customization Setting Request";
BA_ "VNSigAllNodes" SG_ 2151178240 LtRtHnTrCstStReq 1;
BA_ "GenSigSendType" SG_ 2151178240 AdpHgBmAsSnCsStRq 10;
BA_ "SignalType" SG_ 2151178240 AdpHgBmAsSnCsStRq "ENM";
BA_ "SignalLongName" SG_ 2151178240 AdpHgBmAsSnCsStRq "Adaptive High Beam Assist With Sensitivity Customization Setting Request";
BA_ "VNSigAllNodes" SG_ 2151178240 AdpHgBmAsSnCsStRq 1;
BA_ "GenSigSendType" SG_ 2151178240 AdpHgBmAstCstStRq 10;
BA_ "SignalType" SG_ 2151178240 AdpHgBmAstCstStRq "ENM";
BA_ "SignalLongName" SG_ 2151178240 AdpHgBmAstCstStRq "Adaptive High Beam Assist Customization Setting Request";
BA_ "VNSigAllNodes" SG_ 2151178240 AdpHgBmAstCstStRq 1;
BA_ "GenSigSendType" SG_ 2151178240 LtRtHnTrGPSCstStRq 10;
BA_ "SignalType" SG_ 2151178240 LtRtHnTrGPSCstStRq "ENM";
BA_ "SignalLongName" SG_ 2151178240 LtRtHnTrGPSCstStRq "Left Right Hand Traffic With GPS Customization Setting Request";
BA_ "VNSigAllNodes" SG_ 2151178240 LtRtHnTrGPSCstStRq 1;
BA_ "GenSigSendType" SG_ 2151178240 AutHgBmAsSnCsStRq 10;
BA_ "SignalType" SG_ 2151178240 AutHgBmAsSnCsStRq "ENM";
BA_ "SignalLongName" SG_ 2151178240 AutHgBmAsSnCsStRq "Auto High Beam Assist With Sensitivity Customization Setting Request";
BA_ "VNSigAllNodes" SG_ 2151178240 AutHgBmAsSnCsStRq 1;
BA_ "GenSigSendType" SG_ 2151178240 AutHgBmAstCstStRq 10;
BA_ "SignalType" SG_ 2151178240 AutHgBmAstCstStRq "ENM";
BA_ "SignalLongName" SG_ 2151178240 AutHgBmAstCstStRq "Auto High Beam Assist Customization Setting Request";
BA_ "VNSigAllNodes" SG_ 2151178240 AutHgBmAstCstStRq 1;
BA_ "GenSigDeltaValue" SG_ 2149728256 PrtyChrgStPnt 1;
BA_ "GenSigSendType" SG_ 2149728256 PrtyChrgStPnt 12;
BA_ "GenSigSendOnInit" SG_ 2149728256 PrtyChrgStPnt 1;
BA_ "VNSigInfotainment" SG_ 2149728256 PrtyChrgStPnt 1;
BA_ "SignalType" SG_ 2149728256 PrtyChrgStPnt "UNM";
BA_ "SignalLongName" SG_ 2149728256 PrtyChrgStPnt "Priority Charging Set Point";
BA_ "VNSigAllNodes" SG_ 2149728256 PrtyChrgStPnt 1;
BA_ "GenSigSendType" SG_ 2149728256 PrtyChrgActIO 10;
BA_ "VNSigInfotainment" SG_ 2149728256 PrtyChrgActIO 1;
BA_ "SignalType" SG_ 2149728256 PrtyChrgActIO "BLN";
BA_ "SignalLongName" SG_ 2149728256 PrtyChrgActIO "Priority Charging Active Indication On";
BA_ "VNSigAllNodes" SG_ 2149728256 PrtyChrgActIO 1;
BA_ "GenSigSendType" SG_ 2149728256 PrtyChrgAct 10;
BA_ "GenSigSendOnInit" SG_ 2149728256 PrtyChrgAct 1;
BA_ "VNSigInfotainment" SG_ 2149728256 PrtyChrgAct 1;
BA_ "SignalType" SG_ 2149728256 PrtyChrgAct "BLN";
BA_ "SignalLongName" SG_ 2149728256 PrtyChrgAct "Priority Charging Active";
BA_ "VNSigAllNodes" SG_ 2149728256 PrtyChrgAct 1;
BA_ "GenSigSendType" SG_ 2149728256 EngAstHtPlgInCsStAvl 10;
BA_ "GenSigSendOnInit" SG_ 2149728256 EngAstHtPlgInCsStAvl 1;
BA_ "VNSigInfotainment" SG_ 2149728256 EngAstHtPlgInCsStAvl 1;
BA_ "SignalType" SG_ 2149728256 EngAstHtPlgInCsStAvl "BLN";
BA_ "SignalLongName" SG_ 2149728256 EngAstHtPlgInCsStAvl "Engine Assisted Heating Plugged-In Customization Setting Available";
BA_ "VNSigAllNodes" SG_ 2149728256 EngAstHtPlgInCsStAvl 1;
BA_ "GenSigSendType" SG_ 2149728256 EngAstHtPlgInCsCrStVl 10;
BA_ "GenSigSendOnInit" SG_ 2149728256 EngAstHtPlgInCsCrStVl 1;
BA_ "VNSigInfotainment" SG_ 2149728256 EngAstHtPlgInCsCrStVl 1;
BA_ "SignalType" SG_ 2149728256 EngAstHtPlgInCsCrStVl "ENM";
BA_ "SignalLongName" SG_ 2149728256 EngAstHtPlgInCsCrStVl "Engine Assisted Heating Plugged-In Customization Current Setting Value";
BA_ "VNSigAllNodes" SG_ 2149728256 EngAstHtPlgInCsCrStVl 1;
BA_ "GenSigSendType" SG_ 2149728256 EngAstHtCsStAvl 10;
BA_ "GenSigSendOnInit" SG_ 2149728256 EngAstHtCsStAvl 1;
BA_ "VNSigInfotainment" SG_ 2149728256 EngAstHtCsStAvl 1;
BA_ "SignalType" SG_ 2149728256 EngAstHtCsStAvl "BLN";
BA_ "SignalLongName" SG_ 2149728256 EngAstHtCsStAvl "Engine Assisted Heating Customization Setting Available";
BA_ "VNSigAllNodes" SG_ 2149728256 EngAstHtCsStAvl 1;
BA_ "GenSigSendType" SG_ 2149728256 EngAstHtCsCrStVal 10;
BA_ "GenSigSendOnInit" SG_ 2149728256 EngAstHtCsCrStVal 1;
BA_ "VNSigInfotainment" SG_ 2149728256 EngAstHtCsCrStVal 1;
BA_ "SignalType" SG_ 2149728256 EngAstHtCsCrStVal "ENM";
BA_ "SignalLongName" SG_ 2149728256 EngAstHtCsCrStVal "Engine Assisted Heating Customization Current Setting Value";
BA_ "VNSigAllNodes" SG_ 2149728256 EngAstHtCsCrStVal 1;
BA_ "GenSigSendType" SG_ 2149728256 HghVltgPropState 10;
BA_ "VNSigInfotainment" SG_ 2149728256 HghVltgPropState 1;
BA_ "SignalType" SG_ 2149728256 HghVltgPropState "ENM";
BA_ "SignalLongName" SG_ 2149728256 HghVltgPropState "High Voltage Propulsion State";
BA_ "VNSigAllNodes" SG_ 2149728256 HghVltgPropState 1;
BA_ "GenSigSendType" SG_ 2149728256 HVChrgPwrLvl 10;
BA_ "GenSigSendOnInit" SG_ 2149728256 HVChrgPwrLvl 1;
BA_ "VNSigInfotainment" SG_ 2149728256 HVChrgPwrLvl 1;
BA_ "SignalType" SG_ 2149728256 HVChrgPwrLvl "ENM";
BA_ "SignalLongName" SG_ 2149728256 HVChrgPwrLvl "High Voltage Charger Power Level";
BA_ "VNSigAllNodes" SG_ 2149728256 HVChrgPwrLvl 1;
BA_ "GenSigSendType" SG_ 2149728256 ChrgPrtDrStat 10;
BA_ "GenSigSendOnInit" SG_ 2149728256 ChrgPrtDrStat 1;
BA_ "VNSigInfotainment" SG_ 2149728256 ChrgPrtDrStat 1;
BA_ "SignalType" SG_ 2149728256 ChrgPrtDrStat "ENM";
BA_ "SignalLongName" SG_ 2149728256 ChrgPrtDrStat "Charge Port Door Status";
BA_ "VNSigAllNodes" SG_ 2149728256 ChrgPrtDrStat 1;
BA_ "GenSigSendType" SG_ 2149728256 ChgCdTfAlCzStAvbl 10;
BA_ "GenSigSendOnInit" SG_ 2149728256 ChgCdTfAlCzStAvbl 1;
BA_ "VNSigInfotainment" SG_ 2149728256 ChgCdTfAlCzStAvbl 1;
BA_ "SignalType" SG_ 2149728256 ChgCdTfAlCzStAvbl "BLN";
BA_ "SignalLongName" SG_ 2149728256 ChgCdTfAlCzStAvbl "Charge Cord Theft Alert Customization Setting Available";
BA_ "VNSigAllNodes" SG_ 2149728256 ChgCdTfAlCzStAvbl 1;
BA_ "GenSigSendType" SG_ 2149728256 ChgCdTfAlCzCrStVal 10;
BA_ "GenSigSendOnInit" SG_ 2149728256 ChgCdTfAlCzCrStVal 1;
BA_ "VNSigInfotainment" SG_ 2149728256 ChgCdTfAlCzCrStVal 1;
BA_ "SignalType" SG_ 2149728256 ChgCdTfAlCzCrStVal "ENM";
BA_ "SignalLongName" SG_ 2149728256 ChgCdTfAlCzCrStVal "Charge Cord Theft Alert Customization Current Setting Value";
BA_ "VNSigAllNodes" SG_ 2149728256 ChgCdTfAlCzCrStVal 1;
BA_ "GenSigSendType" SG_ 2149728256 ChrgSysTrnsShftLckRq 10;
BA_ "VNSigInfotainment" SG_ 2149728256 ChrgSysTrnsShftLckRq 1;
BA_ "SignalType" SG_ 2149728256 ChrgSysTrnsShftLckRq "BLN";
BA_ "SignalLongName" SG_ 2149728256 ChrgSysTrnsShftLckRq "Charging System Transmission Shift Lock Requested";
BA_ "VNSigAllNodes" SG_ 2149728256 ChrgSysTrnsShftLckRq 1;
BA_ "GenSigSendType" SG_ 2149728256 ChgPwLsAlCzStAvbl 10;
BA_ "GenSigSendOnInit" SG_ 2149728256 ChgPwLsAlCzStAvbl 1;
BA_ "VNSigInfotainment" SG_ 2149728256 ChgPwLsAlCzStAvbl 1;
BA_ "SignalType" SG_ 2149728256 ChgPwLsAlCzStAvbl "BLN";
BA_ "SignalLongName" SG_ 2149728256 ChgPwLsAlCzStAvbl "Charge Power Loss Alert Customization Setting Available";
BA_ "VNSigAllNodes" SG_ 2149728256 ChgPwLsAlCzStAvbl 1;
BA_ "GenSigSendType" SG_ 2149728256 ChgPwLsAlCzCrStVal 10;
BA_ "GenSigSendOnInit" SG_ 2149728256 ChgPwLsAlCzCrStVal 1;
BA_ "VNSigInfotainment" SG_ 2149728256 ChgPwLsAlCzCrStVal 1;
BA_ "SignalType" SG_ 2149728256 ChgPwLsAlCzCrStVal "ENM";
BA_ "SignalLongName" SG_ 2149728256 ChgPwLsAlCzCrStVal "Charge Power Loss Alert Customization Current Setting Value";
BA_ "VNSigAllNodes" SG_ 2149728256 ChgPwLsAlCzCrStVal 1;
BA_ "GenSigSendType" SG_ 2149728256 ChgSysAudInCsStAvl 10;
BA_ "GenSigSendOnInit" SG_ 2149728256 ChgSysAudInCsStAvl 1;
BA_ "VNSigInfotainment" SG_ 2149728256 ChgSysAudInCsStAvl 1;
BA_ "SignalType" SG_ 2149728256 ChgSysAudInCsStAvl "BLN";
BA_ "SignalLongName" SG_ 2149728256 ChgSysAudInCsStAvl "Charger System Audible Indication Customization Setting Available";
BA_ "VNSigAllNodes" SG_ 2149728256 ChgSysAudInCsStAvl 1;
BA_ "GenSigSendType" SG_ 2149728256 ChgSyAudInCsCrStVa 10;
BA_ "GenSigSendOnInit" SG_ 2149728256 ChgSyAudInCsCrStVa 1;
BA_ "VNSigInfotainment" SG_ 2149728256 ChgSyAudInCsCrStVa 1;
BA_ "SignalType" SG_ 2149728256 ChgSyAudInCsCrStVa "ENM";
BA_ "SignalLongName" SG_ 2149728256 ChgSyAudInCsCrStVa "Charger System Audible Indication Customization Current Setting Value";
BA_ "VNSigAllNodes" SG_ 2149728256 ChgSyAudInCsCrStVa 1;
BA_ "GenSigSendType" SG_ 2156265472 OffBrdHVCVehCsChRq 10;
BA_ "VNSigInfotainment" SG_ 2156265472 OffBrdHVCVehCsChRq 1;
BA_ "SignalType" SG_ 2156265472 OffBrdHVCVehCsChRq "BLN";
BA_ "SignalLongName" SG_ 2156265472 OffBrdHVCVehCsChRq "Off Board High Voltage Charging Vehicle Cease Charging Requested";
BA_ "VNSigAllNodes" SG_ 2156265472 OffBrdHVCVehCsChRq 1;
BA_ "GenSigSendType" SG_ 2156265472 PrtyChrgRq 10;
BA_ "VNSigInfotainment" SG_ 2156265472 PrtyChrgRq 1;
BA_ "SignalType" SG_ 2156265472 PrtyChrgRq "ENM";
BA_ "SignalLongName" SG_ 2156265472 PrtyChrgRq "Priority Charging Request";
BA_ "VNSigAllNodes" SG_ 2156265472 PrtyChrgRq 1;
BA_ "GenSigSendType" SG_ 2156265472 HVBTBRCSR_RtChSlStReq 10;
BA_ "VNSigInfotainment" SG_ 2156265472 HVBTBRCSR_RtChSlStReq 1;
BA_ "SignalType" SG_ 2156265472 HVBTBRCSR_RtChSlStReq "ENM";
BA_ "PacketOrder" SG_ 2156265472 HVBTBRCSR_RtChSlStReq 3;
BA_ "SignalLongName" SG_ 2156265472 HVBTBRCSR_RtChSlStReq "High Voltage Battery Time Based Rate Charging Set Request : Rate Charging Selected Set Request";
BA_ "VNSigAllNodes" SG_ 2156265472 HVBTBRCSR_RtChSlStReq 1;
BA_ "GenSigSendType" SG_ 2156265472 HVBTBRCSR_RtChSlRtStReq 10;
BA_ "VNSigInfotainment" SG_ 2156265472 HVBTBRCSR_RtChSlRtStReq 1;
BA_ "SignalType" SG_ 2156265472 HVBTBRCSR_RtChSlRtStReq "ENM";
BA_ "PacketOrder" SG_ 2156265472 HVBTBRCSR_RtChSlRtStReq 2;
BA_ "SignalLongName" SG_ 2156265472 HVBTBRCSR_RtChSlRtStReq "High Voltage Battery Time Based Rate Charging Set Request : Rate Charging Selected Rate Set Request";
BA_ "VNSigAllNodes" SG_ 2156265472 HVBTBRCSR_RtChSlRtStReq 1;
BA_ "GenSigSendType" SG_ 2156265472 HVBTBRCSR_RtChSsnStReq 10;
BA_ "VNSigInfotainment" SG_ 2156265472 HVBTBRCSR_RtChSsnStReq 1;
BA_ "SignalType" SG_ 2156265472 HVBTBRCSR_RtChSsnStReq "ENM";
BA_ "PacketOrder" SG_ 2156265472 HVBTBRCSR_RtChSsnStReq 5;
BA_ "SignalLongName" SG_ 2156265472 HVBTBRCSR_RtChSsnStReq "High Voltage Battery Time Based Rate Charging Set Request : Rate Charging Season Set Request";
BA_ "VNSigAllNodes" SG_ 2156265472 HVBTBRCSR_RtChSsnStReq 1;
BA_ "GenSigDeltaValue" SG_ 2156265472 HVBTBRCSR_RtChMHStReq 1;
BA_ "GenSigSendType" SG_ 2156265472 HVBTBRCSR_RtChMHStReq 12;
BA_ "VNSigInfotainment" SG_ 2156265472 HVBTBRCSR_RtChMHStReq 1;
BA_ "SignalType" SG_ 2156265472 HVBTBRCSR_RtChMHStReq "UNM";
BA_ "PacketOrder" SG_ 2156265472 HVBTBRCSR_RtChMHStReq 6;
BA_ "SignalLongName" SG_ 2156265472 HVBTBRCSR_RtChMHStReq "High Voltage Battery Time Based Rate Charging Set Request : Rate Charging Minute of Hour Set Request";
BA_ "VNSigAllNodes" SG_ 2156265472 HVBTBRCSR_RtChMHStReq 1;
BA_ "GenSigDeltaValue" SG_ 2156265472 HVBTBRCSR_RtChHStReq 1;
BA_ "GenSigSendType" SG_ 2156265472 HVBTBRCSR_RtChHStReq 12;
BA_ "VNSigInfotainment" SG_ 2156265472 HVBTBRCSR_RtChHStReq 1;
BA_ "SignalType" SG_ 2156265472 HVBTBRCSR_RtChHStReq "UNM";
BA_ "PacketOrder" SG_ 2156265472 HVBTBRCSR_RtChHStReq 4;
BA_ "SignalLongName" SG_ 2156265472 HVBTBRCSR_RtChHStReq "High Voltage Battery Time Based Rate Charging Set Request : Rate Charging Hour Set Request";
BA_ "VNSigAllNodes" SG_ 2156265472 HVBTBRCSR_RtChHStReq 1;
BA_ "GenSigSendType" SG_ 2156265472 HVBTBRCSR_RtChDStReq 10;
BA_ "VNSigInfotainment" SG_ 2156265472 HVBTBRCSR_RtChDStReq 1;
BA_ "SignalType" SG_ 2156265472 HVBTBRCSR_RtChDStReq "ENM";
BA_ "PacketOrder" SG_ 2156265472 HVBTBRCSR_RtChDStReq 1;
BA_ "SignalLongName" SG_ 2156265472 HVBTBRCSR_RtChDStReq "High Voltage Battery Time Based Rate Charging Set Request : Rate Charging Day Set Request";
BA_ "VNSigAllNodes" SG_ 2156265472 HVBTBRCSR_RtChDStReq 1;
BA_ "GenSigDeltaValue" SG_ 2156265472 HVBTBRCSR_RtChSlTbRwReq 1;
BA_ "GenSigSendType" SG_ 2156265472 HVBTBRCSR_RtChSlTbRwReq 12;
BA_ "VNSigInfotainment" SG_ 2156265472 HVBTBRCSR_RtChSlTbRwReq 1;
BA_ "SignalType" SG_ 2156265472 HVBTBRCSR_RtChSlTbRwReq "UNM";
BA_ "PacketOrder" SG_ 2156265472 HVBTBRCSR_RtChSlTbRwReq 7;
BA_ "SignalLongName" SG_ 2156265472 HVBTBRCSR_RtChSlTbRwReq "High Voltage Battery Time Based Rate Charging Set Request : Rate Charging Selected Table Row Set Request";
BA_ "VNSigAllNodes" SG_ 2156265472 HVBTBRCSR_RtChSlTbRwReq 1;
BA_ "GenSigSendType" SG_ 2156265472 HVBTBDCSRQ_DlChSlStReq 10;
BA_ "VNSigInfotainment" SG_ 2156265472 HVBTBDCSRQ_DlChSlStReq 1;
BA_ "SignalType" SG_ 2156265472 HVBTBDCSRQ_DlChSlStReq "ENM";
BA_ "PacketOrder" SG_ 2156265472 HVBTBDCSRQ_DlChSlStReq 3;
BA_ "SignalLongName" SG_ 2156265472 HVBTBDCSRQ_DlChSlStReq "High Voltage Battery Time Based Delayed Charging Set Request : Delayed Charging Selected Set Request";
BA_ "VNSigAllNodes" SG_ 2156265472 HVBTBDCSRQ_DlChSlStReq 1;
BA_ "GenSigSendType" SG_ 2156265472 HVBTBDCSRQ_DlChSsnStReq 10;
BA_ "VNSigInfotainment" SG_ 2156265472 HVBTBDCSRQ_DlChSsnStReq 1;
BA_ "SignalType" SG_ 2156265472 HVBTBDCSRQ_DlChSsnStReq "ENM";
BA_ "PacketOrder" SG_ 2156265472 HVBTBDCSRQ_DlChSsnStReq 4;
BA_ "SignalLongName" SG_ 2156265472 HVBTBDCSRQ_DlChSsnStReq "High Voltage Battery Time Based Delayed Charging Set Request : Delayed Charging Season Set Request";
BA_ "VNSigAllNodes" SG_ 2156265472 HVBTBDCSRQ_DlChSsnStReq 1;
BA_ "GenSigDeltaValue" SG_ 2156265472 HVBTBDCSRQ_DlChMHStReq 1;
BA_ "GenSigSendType" SG_ 2156265472 HVBTBDCSRQ_DlChMHStReq 12;
BA_ "VNSigInfotainment" SG_ 2156265472 HVBTBDCSRQ_DlChMHStReq 1;
BA_ "SignalType" SG_ 2156265472 HVBTBDCSRQ_DlChMHStReq "UNM";
BA_ "PacketOrder" SG_ 2156265472 HVBTBDCSRQ_DlChMHStReq 5;
BA_ "SignalLongName" SG_ 2156265472 HVBTBDCSRQ_DlChMHStReq "High Voltage Battery Time Based Delayed Charging Set Request : Delayed Charging Minute of Hour Set Request";
BA_ "VNSigAllNodes" SG_ 2156265472 HVBTBDCSRQ_DlChMHStReq 1;
BA_ "GenSigDeltaValue" SG_ 2156265472 HVBTBDCSRQ_DlChHStReq 1;
BA_ "GenSigSendType" SG_ 2156265472 HVBTBDCSRQ_DlChHStReq 12;
BA_ "VNSigInfotainment" SG_ 2156265472 HVBTBDCSRQ_DlChHStReq 1;
BA_ "SignalType" SG_ 2156265472 HVBTBDCSRQ_DlChHStReq "UNM";
BA_ "PacketOrder" SG_ 2156265472 HVBTBDCSRQ_DlChHStReq 1;
BA_ "SignalLongName" SG_ 2156265472 HVBTBDCSRQ_DlChHStReq "High Voltage Battery Time Based Delayed Charging Set Request : Delayed Charging Hour Set Request";
BA_ "VNSigAllNodes" SG_ 2156265472 HVBTBDCSRQ_DlChHStReq 1;
BA_ "GenSigSendType" SG_ 2156265472 HVBTBDCSRQ_DlChDStReq 10;
BA_ "VNSigInfotainment" SG_ 2156265472 HVBTBDCSRQ_DlChDStReq 1;
BA_ "SignalType" SG_ 2156265472 HVBTBDCSRQ_DlChDStReq "ENM";
BA_ "PacketOrder" SG_ 2156265472 HVBTBDCSRQ_DlChDStReq 2;
BA_ "SignalLongName" SG_ 2156265472 HVBTBDCSRQ_DlChDStReq "High Voltage Battery Time Based Delayed Charging Set Request : Delayed Charging Day Set Request";
BA_ "VNSigAllNodes" SG_ 2156265472 HVBTBDCSRQ_DlChDStReq 1;
BA_ "GenSigSendType" SG_ 2156265472 ChgPwLsAlCzStRq 10;
BA_ "VNSigInfotainment" SG_ 2156265472 ChgPwLsAlCzStRq 1;
BA_ "SignalType" SG_ 2156265472 ChgPwLsAlCzStRq "ENM";
BA_ "SignalLongName" SG_ 2156265472 ChgPwLsAlCzStRq "Charge Power Loss Alert Customization Setting Request";
BA_ "VNSigAllNodes" SG_ 2156265472 ChgPwLsAlCzStRq 1;
BA_ "GenSigSendType" SG_ 2156265472 ChgCdTfAlCzStRq 10;
BA_ "VNSigInfotainment" SG_ 2156265472 ChgCdTfAlCzStRq 1;
BA_ "SignalType" SG_ 2156265472 ChgCdTfAlCzStRq "ENM";
BA_ "SignalLongName" SG_ 2156265472 ChgCdTfAlCzStRq "Charge Cord Theft Alert Customization Setting Request";
BA_ "VNSigAllNodes" SG_ 2156265472 ChgCdTfAlCzStRq 1;
BA_ "GenSigSendType" SG_ 2156265472 ChgSysAudInCsStReq 10;
BA_ "VNSigInfotainment" SG_ 2156265472 ChgSysAudInCsStReq 1;
BA_ "SignalType" SG_ 2156265472 ChgSysAudInCsStReq "ENM";
BA_ "SignalLongName" SG_ 2156265472 ChgSysAudInCsStReq "Charger System Audible Indication Customization Setting Request";
BA_ "VNSigAllNodes" SG_ 2156265472 ChgSysAudInCsStReq 1;
BA_ "GenSigSendType" SG_ 2156265472 EngyUsgScrnMeasUtStat 10;
BA_ "GenSigSendOnInit" SG_ 2156265472 EngyUsgScrnMeasUtStat 1;
BA_ "VNSigInfotainment" SG_ 2156265472 EngyUsgScrnMeasUtStat 1;
BA_ "SignalType" SG_ 2156265472 EngyUsgScrnMeasUtStat "ENM";
BA_ "SignalLongName" SG_ 2156265472 EngyUsgScrnMeasUtStat "Energy Usage Screen Measurement Unit Status";
BA_ "VNSigAllNodes" SG_ 2156265472 EngyUsgScrnMeasUtStat 1;
BA_ "GenSigSendType" SG_ 2150563840 PsStStatDispAct 10;
BA_ "GenSigSendOnInit" SG_ 2150563840 PsStStatDispAct 2;
BA_ "SignalType" SG_ 2150563840 PsStStatDispAct "BLN";
BA_ "SignalLongName" SG_ 2150563840 PsStStatDispAct "Passenger Seat Status Display Active";
BA_ "VNSigAllNodes" SG_ 2150563840 PsStStatDispAct 1;
BA_ "GenSigSendType" SG_ 2150563840 DrStStatDispAct 10;
BA_ "GenSigSendOnInit" SG_ 2150563840 DrStStatDispAct 2;
BA_ "SignalType" SG_ 2150563840 DrStStatDispAct "BLN";
BA_ "SignalLongName" SG_ 2150563840 DrStStatDispAct "Driver Seat Status Display Active";
BA_ "VNSigAllNodes" SG_ 2150563840 DrStStatDispAct 1;
BA_ "GenSigSendType" SG_ 2150563840 RadAudQueStat 10;
BA_ "GenSigSendOnInit" SG_ 2150563840 RadAudQueStat 2;
BA_ "SignalType" SG_ 2150563840 RadAudQueStat "ENM";
BA_ "SignalLongName" SG_ 2150563840 RadAudQueStat "Radio Audio Queue Status";
BA_ "VNSigAllNodes" SG_ 2150563840 RadAudQueStat 1;
BA_ "GenSigSendType" SG_ 2150563840 RadAnmtStat 10;
BA_ "GenSigSendOnInit" SG_ 2150563840 RadAnmtStat 2;
BA_ "SignalType" SG_ 2150563840 RadAnmtStat "ENM";
BA_ "SignalLongName" SG_ 2150563840 RadAnmtStat "Radio Animation Status";
BA_ "VNSigAllNodes" SG_ 2150563840 RadAnmtStat 1;
BA_ "GenSigSendType" SG_ 2149793792 AutoEmrgncyBrkDisbldIO 10;
BA_ "SignalType" SG_ 2149793792 AutoEmrgncyBrkDisbldIO "BLN";
BA_ "SignalLongName" SG_ 2149793792 AutoEmrgncyBrkDisbldIO "Automatic Emergency Braking Disabled Indication On";
BA_ "VNSigAllNodes" SG_ 2149793792 AutoEmrgncyBrkDisbldIO 1;
BA_ "GenSigSendType" SG_ 2149793792 VADIR_IndLvl 10;
BA_ "GenSigSendOnInit" SG_ 2149793792 VADIR_IndLvl 1;
BA_ "SignalType" SG_ 2149793792 VADIR_IndLvl "ENM";
BA_ "PacketOrder" SG_ 2149793792 VADIR_IndLvl 1;
BA_ "SignalLongName" SG_ 2149793792 VADIR_IndLvl "Vehicle Ahead Distance Indication Request : Indication Level";
BA_ "VNSigAllNodes" SG_ 2149793792 VADIR_IndLvl 1;
BA_ "GenSigDeltaValue" SG_ 2149793792 VADIR_FlwTme 1;
BA_ "GenSigSendType" SG_ 2149793792 VADIR_FlwTme 12;
BA_ "GenSigSendOnInit" SG_ 2149793792 VADIR_FlwTme 1;
BA_ "SignalType" SG_ 2149793792 VADIR_FlwTme "UNM";
BA_ "PacketOrder" SG_ 2149793792 VADIR_FlwTme 2;
BA_ "SignalLongName" SG_ 2149793792 VADIR_FlwTme "Vehicle Ahead Distance Indication Request : Following Time";
BA_ "VNSigAllNodes" SG_ 2149793792 VADIR_FlwTme 1;
BA_ "GenSigDeltaValue" SG_ 2149793792 VADIR_FlwDst 1;
BA_ "GenSigSendType" SG_ 2149793792 VADIR_FlwDst 12;
BA_ "GenSigSendOnInit" SG_ 2149793792 VADIR_FlwDst 1;
BA_ "SignalType" SG_ 2149793792 VADIR_FlwDst "UNM";
BA_ "PacketOrder" SG_ 2149793792 VADIR_FlwDst 3;
BA_ "SignalLongName" SG_ 2149793792 VADIR_FlwDst "Vehicle Ahead Distance Indication Request : Following Distance";
BA_ "VNSigAllNodes" SG_ 2149793792 VADIR_FlwDst 1;
BA_ "GenSigSendType" SG_ 2149793792 FCACustStngAvlbl 10;
BA_ "GenSigSendOnInit" SG_ 2149793792 FCACustStngAvlbl 2;
BA_ "SignalType" SG_ 2149793792 FCACustStngAvlbl "BLN";
BA_ "SignalLongName" SG_ 2149793792 FCACustStngAvlbl "Forward Collision Alert Customization Setting Available";
BA_ "VNSigAllNodes" SG_ 2149793792 FCACustStngAvlbl 1;
BA_ "GenSigSendType" SG_ 2149793792 FwdClnAlrtCustCrntSetngVal 10;
BA_ "GenSigSendOnInit" SG_ 2149793792 FwdClnAlrtCustCrntSetngVal 2;
BA_ "SignalType" SG_ 2149793792 FwdClnAlrtCustCrntSetngVal "ENM";
BA_ "SignalLongName" SG_ 2149793792 FwdClnAlrtCustCrntSetngVal "Forward Collision Alert Customization Current Setting Value";
BA_ "VNSigAllNodes" SG_ 2149793792 FwdClnAlrtCustCrntSetngVal 1;
BA_ "GenSigSendType" SG_ 2150891520 RrStRmndrCstSetReq 10;
BA_ "SignalType" SG_ 2150891520 RrStRmndrCstSetReq "ENM";
BA_ "SignalLongName" SG_ 2150891520 RrStRmndrCstSetReq "Rear Seat Reminder Customization Setting Request";
BA_ "VNSigAllNodes" SG_ 2150891520 RrStRmndrCstSetReq 1;
BA_ "GenSigSendType" SG_ 2150891520 DgtlMapCndlSpdLmt 10;
BA_ "SignalType" SG_ 2150891520 DgtlMapCndlSpdLmt "ENM";
BA_ "SignalLongName" SG_ 2150891520 DgtlMapCndlSpdLmt "Digital Map Conditional Speed Limit";
BA_ "VNSigAllNodes" SG_ 2150891520 DgtlMapCndlSpdLmt 1;
BA_ "GenSigSendType" SG_ 2150891520 DgtlMapPsgRstrctn 10;
BA_ "SignalType" SG_ 2150891520 DgtlMapPsgRstrctn "ENM";
BA_ "SignalLongName" SG_ 2150891520 DgtlMapPsgRstrctn "Digital Map Passing Restriction";
BA_ "VNSigAllNodes" SG_ 2150891520 DgtlMapPsgRstrctn 1;
BA_ "GenSigSendType" SG_ 2150891520 DgtlMapCndlSpdLmtTyp 10;
BA_ "SignalType" SG_ 2150891520 DgtlMapCndlSpdLmtTyp "ENM";
BA_ "SignalLongName" SG_ 2150891520 DgtlMapCndlSpdLmtTyp "Digital Map Conditional Speed Limit Type";
BA_ "VNSigAllNodes" SG_ 2150891520 DgtlMapCndlSpdLmtTyp 1;
BA_ "GenSigSendType" SG_ 2150891520 DgtlMapEffSpdLmt 10;
BA_ "SignalType" SG_ 2150891520 DgtlMapEffSpdLmt "ENM";
BA_ "SignalLongName" SG_ 2150891520 DgtlMapEffSpdLmt "Digital Map Effective Speed Limit";
BA_ "VNSigAllNodes" SG_ 2150891520 DgtlMapEffSpdLmt 1;
BA_ "GenSigSendType" SG_ 2150891520 DgtlMapEffSpdLmtTyp 10;
BA_ "SignalType" SG_ 2150891520 DgtlMapEffSpdLmtTyp "ENM";
BA_ "SignalLongName" SG_ 2150891520 DgtlMapEffSpdLmtTyp "Digital Map Effective Speed Limit Type";
BA_ "VNSigAllNodes" SG_ 2150891520 DgtlMapEffSpdLmtTyp 1;
BA_ "GenSigSendType" SG_ 2150891520 DgtlMapSpdCat 10;
BA_ "SignalType" SG_ 2150891520 DgtlMapSpdCat "ENM";
BA_ "SignalLongName" SG_ 2150891520 DgtlMapSpdCat "Digital Map Speed Category";
BA_ "VNSigAllNodes" SG_ 2150891520 DgtlMapSpdCat 1;
BA_ "GenSigSendType" SG_ 2150891520 DgtlMapVerQtr 10;
BA_ "SignalType" SG_ 2150891520 DgtlMapVerQtr "ENM";
BA_ "SignalLongName" SG_ 2150891520 DgtlMapVerQtr "Digital Map Version Quarter";
BA_ "VNSigAllNodes" SG_ 2150891520 DgtlMapVerQtr 1;
BA_ "GenSigSendType" SG_ 2150891520 DgtlMapVerYr 10;
BA_ "SignalType" SG_ 2150891520 DgtlMapVerYr "ENM";
BA_ "SignalLongName" SG_ 2150891520 DgtlMapVerYr "Digital Map Version Year";
BA_ "VNSigAllNodes" SG_ 2150891520 DgtlMapVerYr 1;
BA_ "GenSigSendType" SG_ 2150891520 DgtlMapDrvngSd 10;
BA_ "SignalType" SG_ 2150891520 DgtlMapDrvngSd "ENM";
BA_ "SignalLongName" SG_ 2150891520 DgtlMapDrvngSd "Digital Map Driving Side";
BA_ "VNSigAllNodes" SG_ 2150891520 DgtlMapDrvngSd 1;
BA_ "GenSigSendType" SG_ 2150891520 FwdClnAlrtCustStngReq 10;
BA_ "GenSigSendOnInit" SG_ 2150891520 FwdClnAlrtCustStngReq 1;
BA_ "SignalType" SG_ 2150891520 FwdClnAlrtCustStngReq "ENM";
BA_ "SignalLongName" SG_ 2150891520 FwdClnAlrtCustStngReq "Forward Collision Alert Customization Setting Request";
BA_ "VNSigAllNodes" SG_ 2150891520 FwdClnAlrtCustStngReq 1;
BA_ "GenSigSendType" SG_ 2150891520 GNCustStngReq 10;
BA_ "GenSigSendOnInit" SG_ 2150891520 GNCustStngReq 1;
BA_ "SignalType" SG_ 2150891520 GNCustStngReq "ENM";
BA_ "SignalLongName" SG_ 2150891520 GNCustStngReq "Go Notifier Customization Setting Request";
BA_ "VNSigAllNodes" SG_ 2150891520 GNCustStngReq 1;
BA_ "GenSigSendType" SG_ 2155569152 SmPhRmFunCstStReq 10;
BA_ "VNSigInfotainment" SG_ 2155569152 SmPhRmFunCstStReq 1;
BA_ "SignalType" SG_ 2155569152 SmPhRmFunCstStReq "ENM";
BA_ "SignalLongName" SG_ 2155569152 SmPhRmFunCstStReq "Smart Phone Remote Function Customization Setting Request";
BA_ "VNSigAllNodes" SG_ 2155569152 SmPhRmFunCstStReq 1;
BA_ "GenSigSendType" SG_ 2155569152 HLOCCstSetReq 10;
BA_ "SignalType" SG_ 2155569152 HLOCCstSetReq "ENM";
BA_ "SignalLongName" SG_ 2155569152 HLOCCstSetReq "Handsfree Liftgate Open Close Customization Setting Request";
BA_ "VNSigAllNodes" SG_ 2155569152 HLOCCstSetReq 1;
BA_ "GenSigSendType" SG_ 2155569152 IntDimSeldClrTypStReq 10;
BA_ "SignalType" SG_ 2155569152 IntDimSeldClrTypStReq "ENM";
BA_ "SignalLongName" SG_ 2155569152 IntDimSeldClrTypStReq "Interior Dimming Selected Color Type Setting Request";
BA_ "VNSigAllNodes" SG_ 2155569152 IntDimSeldClrTypStReq 1;
BA_ "GenSigSendType" SG_ 2155569152 IntDimSeldAnmTypStReq 10;
BA_ "SignalType" SG_ 2155569152 IntDimSeldAnmTypStReq "ENM";
BA_ "SignalLongName" SG_ 2155569152 IntDimSeldAnmTypStReq "Interior Dimming Selected Animation Type Setting Request";
BA_ "VNSigAllNodes" SG_ 2155569152 IntDimSeldAnmTypStReq 1;
BA_ "GenSigSendType" SG_ 2155569152 ExtHlStrAssCsStRq 10;
BA_ "GenSigSendOnInit" SG_ 2155569152 ExtHlStrAssCsStRq 1;
BA_ "SignalType" SG_ 2155569152 ExtHlStrAssCsStRq "ENM";
BA_ "SignalLongName" SG_ 2155569152 ExtHlStrAssCsStRq "Extended Hill Start Assist Customization Setting Request";
BA_ "VNSigAllNodes" SG_ 2155569152 ExtHlStrAssCsStRq 1;
BA_ "GenSigSendType" SG_ 2155569152 ColPrSysCustReq 10;
BA_ "GenSigSendOnInit" SG_ 2155569152 ColPrSysCustReq 1;
BA_ "SignalType" SG_ 2155569152 ColPrSysCustReq "ENM";
BA_ "SignalLongName" SG_ 2155569152 ColPrSysCustReq "Collision Preparation System Customization Setting Request";
BA_ "VNSigAllNodes" SG_ 2155569152 ColPrSysCustReq 1;
BA_ "GenSigSendType" SG_ 2152022016 ASVSC_ReqEnbld 10;
BA_ "PacketOrder" SG_ 2152022016 ASVSC_ReqEnbld 2;
BA_ "VNSigIntermediate" SG_ 2152022016 ASVSC_ReqEnbld 1;
BA_ "SignalType" SG_ 2152022016 ASVSC_ReqEnbld "BLN";
BA_ "SignalLongName" SG_ 2152022016 ASVSC_ReqEnbld "Audio System Volume Setting Control : Request Enabled";
BA_ "GenSigDeltaValue" SG_ 2152022016 ASVSC_VolReq 1;
BA_ "GenSigSendType" SG_ 2152022016 ASVSC_VolReq 12;
BA_ "PacketOrder" SG_ 2152022016 ASVSC_VolReq 1;
BA_ "VNSigIntermediate" SG_ 2152022016 ASVSC_VolReq 1;
BA_ "SignalType" SG_ 2152022016 ASVSC_VolReq "UNM";
BA_ "SignalLongName" SG_ 2152022016 ASVSC_VolReq "Audio System Volume Setting Control : Volume Request";
BA_ "GenSigSendType" SG_ 2152022016 AudSelctdSrcReq 10;
BA_ "VNSigIntermediate" SG_ 2152022016 AudSelctdSrcReq 1;
BA_ "SignalType" SG_ 2152022016 AudSelctdSrcReq "ENM";
BA_ "SignalLongName" SG_ 2152022016 AudSelctdSrcReq "Audio Selected Source Request";
BA_ "GenSigSendType" SG_ 2152022016 InfMdStRsp 10;
BA_ "VNSigInfotainment" SG_ 2152022016 InfMdStRsp 1;
BA_ "SignalType" SG_ 2152022016 InfMdStRsp "ENM";
BA_ "SignalLongName" SG_ 2152022016 InfMdStRsp "Infomatics Metadata Status Response";
BA_ "VNSigAllNodes" SG_ 2152022016 InfMdStRsp 1;
BA_ "GenSigDeltaValue" SG_ 2152022016 InfMdRspInf 1;
BA_ "GenSigSendType" SG_ 2152022016 InfMdRspInf 12;
BA_ "VNSigInfotainment" SG_ 2152022016 InfMdRspInf 1;
BA_ "SignalType" SG_ 2152022016 InfMdRspInf "UNM";
BA_ "SignalLongName" SG_ 2152022016 InfMdRspInf "Infomatics Metadata Response Initiate";
BA_ "VNSigAllNodes" SG_ 2152022016 InfMdRspInf 1;
BA_ "GenSigDeltaValue" SG_ 2152022016 InfMdRspCmplt 1;
BA_ "GenSigSendType" SG_ 2152022016 InfMdRspCmplt 12;
BA_ "VNSigInfotainment" SG_ 2152022016 InfMdRspCmplt 1;
BA_ "SignalType" SG_ 2152022016 InfMdRspCmplt "UNM";
BA_ "SignalLongName" SG_ 2152022016 InfMdRspCmplt "Infomatics Metadata Response Complete";
BA_ "VNSigAllNodes" SG_ 2152022016 InfMdRspCmplt 1;
BA_ "GenSigDeltaValue" SG_ 2152005632 InfMdRqstPld 1;
BA_ "GenSigSendType" SG_ 2152005632 InfMdRqstPld 12;
BA_ "VNSigInfotainment" SG_ 2152005632 InfMdRqstPld 1;
BA_ "SignalType" SG_ 2152005632 InfMdRqstPld "UNM";
BA_ "SignalLongName" SG_ 2152005632 InfMdRqstPld "Infomatics Metadata Request Payload";
BA_ "VNSigAllNodes" SG_ 2152005632 InfMdRqstPld 1;
BA_ "GenSigDeltaValue" SG_ 2151989248 InfMdRqstInt 1;
BA_ "GenSigSendType" SG_ 2151989248 InfMdRqstInt 12;
BA_ "VNSigInfotainment" SG_ 2151989248 InfMdRqstInt 1;
BA_ "SignalType" SG_ 2151989248 InfMdRqstInt "UNM";
BA_ "SignalLongName" SG_ 2151989248 InfMdRqstInt "Infomatics Metadata Request Initiate";
BA_ "VNSigAllNodes" SG_ 2151989248 InfMdRqstInt 1;
BA_ "GenSigDeltaValue" SG_ 2151989248 InfMdRqstCmplt 1;
BA_ "GenSigSendType" SG_ 2151989248 InfMdRqstCmplt 12;
BA_ "VNSigInfotainment" SG_ 2151989248 InfMdRqstCmplt 1;
BA_ "SignalType" SG_ 2151989248 InfMdRqstCmplt "UNM";
BA_ "SignalLongName" SG_ 2151989248 InfMdRqstCmplt "Infomatics Metadata Request Complete";
BA_ "VNSigAllNodes" SG_ 2151989248 InfMdRqstCmplt 1;
BA_ "GenSigSendType" SG_ 2151989248 InfMdStReq 10;
BA_ "VNSigInfotainment" SG_ 2151989248 InfMdStReq 1;
BA_ "SignalType" SG_ 2151989248 InfMdStReq "ENM";
BA_ "SignalLongName" SG_ 2151989248 InfMdStReq "Infomatics Metadata Status Request";
BA_ "VNSigAllNodes" SG_ 2151989248 InfMdStReq 1;
BA_ "GenSigSendType" SG_ 2154708992 ASS2AudSrcStatCode 10;
BA_ "VNSigInfotainment" SG_ 2154708992 ASS2AudSrcStatCode 1;
BA_ "SignalType" SG_ 2154708992 ASS2AudSrcStatCode "ENM";
BA_ "PacketOrder" SG_ 2154708992 ASS2AudSrcStatCode 3;
BA_ "SignalLongName" SG_ 2154708992 ASS2AudSrcStatCode "Audio Source Status 2 : Audio Source Status Code";
BA_ "VNSigAllNodes" SG_ 2154708992 ASS2AudSrcStatCode 1;
BA_ "GenSigSendType" SG_ 2154708992 ASS2AudSrcChType 10;
BA_ "VNSigInfotainment" SG_ 2154708992 ASS2AudSrcChType 1;
BA_ "SignalType" SG_ 2154708992 ASS2AudSrcChType "ENM";
BA_ "PacketOrder" SG_ 2154708992 ASS2AudSrcChType 2;
BA_ "SignalLongName" SG_ 2154708992 ASS2AudSrcChType "Audio Source Status 2 : Audio Source Channel Type";
BA_ "VNSigAllNodes" SG_ 2154708992 ASS2AudSrcChType 1;
BA_ "GenSigSendType" SG_ 2154708992 ASS2AudSrcType 10;
BA_ "VNSigInfotainment" SG_ 2154708992 ASS2AudSrcType 1;
BA_ "SignalType" SG_ 2154708992 ASS2AudSrcType "ENM";
BA_ "PacketOrder" SG_ 2154708992 ASS2AudSrcType 1;
BA_ "SignalLongName" SG_ 2154708992 ASS2AudSrcType "Audio Source Status 2 : Audio Source Type";
BA_ "VNSigAllNodes" SG_ 2154708992 ASS2AudSrcType 1;
BA_ "SignalType" SG_ 2149875712 DCCnvStblznErrIO "BLN";
BA_ "SignalLongName" SG_ 2149875712 DCCnvStblznErrIO "DC Converter Stabilization Error Indication On";
BA_ "VNSigAllNodes" SG_ 2149875712 DCCnvStblznErrIO 1;
BA_ "SignalType" SG_ 2149875712 BattStOfChrgLowIO "BLN";
BA_ "SignalLongName" SG_ 2149875712 BattStOfChrgLowIO "Battery State of Charge Low Indication On";
BA_ "VNSigAllNodes" SG_ 2149875712 BattStOfChrgLowIO 1;
BA_ "SignalType" SG_ 2149875712 BattCrntFltrd "SNM";
BA_ "SignalLongName" SG_ 2149875712 BattCrntFltrd "Battery Current Filtered";
BA_ "VNSigAllNodes" SG_ 2149875712 BattCrntFltrd 1;
BA_ "SignalType" SG_ 2149875712 IntlgntBattSnsFldIO "BLN";
BA_ "SignalLongName" SG_ 2149875712 IntlgntBattSnsFldIO "Intelligent Battery Sensor Failed Indication On";
BA_ "VNSigAllNodes" SG_ 2149875712 IntlgntBattSnsFldIO 1;
BA_ "SignalType" SG_ 2149875712 BatSvrMdSevLvl "UNM";
BA_ "SignalLongName" SG_ 2149875712 BatSvrMdSevLvl "Battery Saver Mode Severity Level";
BA_ "VNSigAllNodes" SG_ 2149875712 BatSvrMdSevLvl 1;
BA_ "SignalType" SG_ 2149875712 BatSOCV "ENM";
BA_ "SignalLongName" SG_ 2149875712 BatSOCV "Battery State of Charge Validity";
BA_ "VNSigAllNodes" SG_ 2149875712 BatSOCV 1;
BA_ "SignalType" SG_ 2149875712 PwrMdOffBattSOC "UNM";
BA_ "SignalLongName" SG_ 2149875712 PwrMdOffBattSOC "Power Mode Off Battery State Of Charge";
BA_ "VNSigAllNodes" SG_ 2149875712 PwrMdOffBattSOC 1;
BA_ "SignalType" SG_ 2149875712 EnrgMgtLdShdRq "ENM";
BA_ "SignalLongName" SG_ 2149875712 EnrgMgtLdShdRq "Energy Management Load Shedding Request";
BA_ "VNSigAllNodes" SG_ 2149875712 EnrgMgtLdShdRq 1;
BA_ "VNSigInfotainment" SG_ 2149875712 SrvBattChrgSysIO 1;
BA_ "SignalType" SG_ 2149875712 SrvBattChrgSysIO "BLN";
BA_ "SignalLongName" SG_ 2149875712 SrvBattChrgSysIO "Service Battery Charging System Indication On";
BA_ "VNSigAllNodes" SG_ 2149875712 SrvBattChrgSysIO 1;
BA_ "VNSigInfotainment" SG_ 2149875712 BattStOfChrgCrtyLow 1;
BA_ "VNSigIntermediate" SG_ 2149875712 BattStOfChrgCrtyLow 1;
BA_ "SignalType" SG_ 2149875712 BattStOfChrgCrtyLow "BLN";
BA_ "SignalLongName" SG_ 2149875712 BattStOfChrgCrtyLow "Battery State of Charge Critically Low";
BA_ "VNSigAllNodes" SG_ 2149875712 BattStOfChrgCrtyLow 1;
BA_ "VNSigInfotainment" SG_ 2149875712 BatSaverIO 1;
BA_ "SignalType" SG_ 2149875712 BatSaverIO "BLN";
BA_ "SignalLongName" SG_ 2149875712 BatSaverIO "Battery Saver Indication On";
BA_ "VNSigAllNodes" SG_ 2149875712 BatSaverIO 1;
BA_ "VNSigInfotainment" SG_ 2149875712 BatSOC 1;
BA_ "SignalType" SG_ 2149875712 BatSOC "UNM";
BA_ "SignalLongName" SG_ 2149875712 BatSOC "Battery State of Charge";
BA_ "VNSigAllNodes" SG_ 2149875712 BatSOC 1;
BA_ "SignalType" SG_ 2149875712 BattVltIRq "ENM";
BA_ "SignalLongName" SG_ 2149875712 BattVltIRq "Battery Voltage Indication Request";
BA_ "VNSigAllNodes" SG_ 2149875712 BattVltIRq 1;
BA_ "VNSigInfotainment" SG_ 2149875712 BatVltV 1;
BA_ "SignalType" SG_ 2149875712 BatVltV "ENM";
BA_ "SignalLongName" SG_ 2149875712 BatVltV "Battery Voltage Validity";
BA_ "VNSigAllNodes" SG_ 2149875712 BatVltV 1;
BA_ "VNSigInfotainment" SG_ 2149875712 BatVlt 1;
BA_ "SignalType" SG_ 2149875712 BatVlt "UNM";
BA_ "SignalLongName" SG_ 2149875712 BatVlt "Battery Voltage";
BA_ "VNSigAllNodes" SG_ 2149875712 BatVlt 1;
BA_ "SignalType" SG_ 1613 DgnInf "UNM";
BA_ "SignalLongName" SG_ 1613 DgnInf "Diagnostic Information";
BA_ "VNSigDiagnostic" SG_ 1613 DgnInf 1;
BA_ "VNSigAllNodes" SG_ 1613 DgnInf 1;
BA_ "VNSigPrimaryTriggering" SG_ 1581 VectraSpcNWMgtD 1;
BA_ "VNSigRemoteDiagnostics" SG_ 1581 VectraSpcNWMgtD 1;
BA_ "VNSigInfotainment" SG_ 1581 VectraSpcNWMgtD 1;
BA_ "VNSigParkedVehicle" SG_ 1581 VectraSpcNWMgtD 1;
BA_ "VNSigIntermediate" SG_ 1581 VectraSpcNWMgtD 1;
BA_ "VNSigUnused_4" SG_ 1581 VectraSpcNWMgtD 1;
BA_ "SignalType" SG_ 1581 VectraSpcNWMgtD "UNM";
BA_ "SignalLongName" SG_ 1581 VectraSpcNWMgtD "Vectra Specific Network Management Data";
BA_ "VNSigDiagnostic" SG_ 1581 VectraSpcNWMgtD 1;
BA_ "VNSigAllNodes" SG_ 1581 VectraSpcNWMgtD 1;
BA_ "GenSigDeltaValue" SG_ 1357 DgnInf_LS54D 1;
BA_ "GenSigSendType" SG_ 1357 DgnInf_LS54D 12;
BA_ "SignalType" SG_ 1357 DgnInf_LS54D "UNM";
BA_ "SignalLongName" SG_ 1357 DgnInf_LS54D "Diagnostic Information LS54D";
BA_ "VNSigDiagnostic" SG_ 1357 DgnInf_LS54D 1;
BA_ "VNSigAllNodes" SG_ 1357 DgnInf_LS54D 1;
BA_ "GenSigDeltaValue" SG_ 2159222784 ODI_PDIM2CntrStck 1;
BA_ "GenSigSendType" SG_ 2159222784 ODI_PDIM2CntrStck 12;
BA_ "VNSigInfotainment" SG_ 2159222784 ODI_PDIM2CntrStck 1;
BA_ "SignalType" SG_ 2159222784 ODI_PDIM2CntrStck "UNM";
BA_ "SignalLongName" SG_ 2159222784 ODI_PDIM2CntrStck "Open Display Interface PDIM 2 Centerstack";
BA_ "VNSigAllNodes" SG_ 2159222784 ODI_PDIM2CntrStck 1;
BA_ "GenSigDeltaValue" SG_ 2159214592 ODI_CntrStck2PDIM 1;
BA_ "GenSigSendType" SG_ 2159214592 ODI_CntrStck2PDIM 12;
BA_ "VNSigInfotainment" SG_ 2159214592 ODI_CntrStck2PDIM 1;
BA_ "SignalType" SG_ 2159214592 ODI_CntrStck2PDIM "UNM";
BA_ "SignalLongName" SG_ 2159214592 ODI_CntrStck2PDIM "Open Display Interface Centerstack 2 PDIM";
BA_ "VNSigAllNodes" SG_ 2159214592 ODI_CntrStck2PDIM 1;
BA_ "GenSigSendType" SG_ 2158911488 ODDMC_ReqType 10;
BA_ "VNSigInfotainment" SG_ 2158911488 ODDMC_ReqType 1;
BA_ "SignalType" SG_ 2158911488 ODDMC_ReqType "ENM";
BA_ "PacketOrder" SG_ 2158911488 ODDMC_ReqType 1;
BA_ "SignalLongName" SG_ 2158911488 ODDMC_ReqType "Open Display Interface Dynamic Data Multi Request CenterStack : Request Type";
BA_ "VNSigAllNodes" SG_ 2158911488 ODDMC_ReqType 1;
BA_ "GenSigSendType" SG_ 2158911488 ODDMC_DispMID 10;
BA_ "VNSigInfotainment" SG_ 2158911488 ODDMC_DispMID 1;
BA_ "SignalType" SG_ 2158911488 ODDMC_DispMID "ENM";
BA_ "PacketOrder" SG_ 2158911488 ODDMC_DispMID 7;
BA_ "SignalLongName" SG_ 2158911488 ODDMC_DispMID "Open Display Interface Dynamic Data Multi Request CenterStack : Display Mask Id";
BA_ "VNSigAllNodes" SG_ 2158911488 ODDMC_DispMID 1;
BA_ "GenSigSendType" SG_ 2158911488 ODDMC_DataID2Vld 10;
BA_ "VNSigInfotainment" SG_ 2158911488 ODDMC_DataID2Vld 1;
BA_ "SignalType" SG_ 2158911488 ODDMC_DataID2Vld "BLN";
BA_ "PacketOrder" SG_ 2158911488 ODDMC_DataID2Vld 5;
BA_ "SignalLongName" SG_ 2158911488 ODDMC_DataID2Vld "Open Display Interface Dynamic Data Multi Request CenterStack : Data ID Two Valid";
BA_ "VNSigAllNodes" SG_ 2158911488 ODDMC_DataID2Vld 1;
BA_ "GenSigSendType" SG_ 2158911488 ODDMC_DataID2 12;
BA_ "VNSigInfotainment" SG_ 2158911488 ODDMC_DataID2 1;
BA_ "SignalType" SG_ 2158911488 ODDMC_DataID2 "UNM";
BA_ "PacketOrder" SG_ 2158911488 ODDMC_DataID2 9;
BA_ "SignalLongName" SG_ 2158911488 ODDMC_DataID2 "Open Display Interface Dynamic Data Multi Request CenterStack : Data ID Two";
BA_ "VNSigAllNodes" SG_ 2158911488 ODDMC_DataID2 1;
BA_ "GenSigSendType" SG_ 2158911488 ODDMC_DataID3Vld 10;
BA_ "VNSigInfotainment" SG_ 2158911488 ODDMC_DataID3Vld 1;
BA_ "SignalType" SG_ 2158911488 ODDMC_DataID3Vld "BLN";
BA_ "PacketOrder" SG_ 2158911488 ODDMC_DataID3Vld 4;
BA_ "SignalLongName" SG_ 2158911488 ODDMC_DataID3Vld "Open Display Interface Dynamic Data Multi Request CenterStack : Data ID Three Valid";
BA_ "VNSigAllNodes" SG_ 2158911488 ODDMC_DataID3Vld 1;
BA_ "GenSigDeltaValue" SG_ 2158911488 ODDMC_DataID3 1;
BA_ "GenSigSendType" SG_ 2158911488 ODDMC_DataID3 12;
BA_ "VNSigInfotainment" SG_ 2158911488 ODDMC_DataID3 1;
BA_ "SignalType" SG_ 2158911488 ODDMC_DataID3 "UNM";
BA_ "PacketOrder" SG_ 2158911488 ODDMC_DataID3 10;
BA_ "SignalLongName" SG_ 2158911488 ODDMC_DataID3 "Open Display Interface Dynamic Data Multi Request CenterStack : Data ID Three";
BA_ "VNSigAllNodes" SG_ 2158911488 ODDMC_DataID3 1;
BA_ "GenSigDeltaValue" SG_ 2158911488 ODDMC_DataID1 1;
BA_ "GenSigSendType" SG_ 2158911488 ODDMC_DataID1 12;
BA_ "VNSigInfotainment" SG_ 2158911488 ODDMC_DataID1 1;
BA_ "SignalType" SG_ 2158911488 ODDMC_DataID1 "UNM";
BA_ "PacketOrder" SG_ 2158911488 ODDMC_DataID1 8;
BA_ "SignalLongName" SG_ 2158911488 ODDMC_DataID1 "Open Display Interface Dynamic Data Multi Request CenterStack : Data ID One";
BA_ "VNSigAllNodes" SG_ 2158911488 ODDMC_DataID1 1;
BA_ "GenSigSendType" SG_ 2158911488 ODDMC_DataID4Vld 10;
BA_ "VNSigInfotainment" SG_ 2158911488 ODDMC_DataID4Vld 1;
BA_ "SignalType" SG_ 2158911488 ODDMC_DataID4Vld "BLN";
BA_ "PacketOrder" SG_ 2158911488 ODDMC_DataID4Vld 3;
BA_ "SignalLongName" SG_ 2158911488 ODDMC_DataID4Vld "Open Display Interface Dynamic Data Multi Request CenterStack : Data ID Four Valid";
BA_ "VNSigAllNodes" SG_ 2158911488 ODDMC_DataID4Vld 1;
BA_ "GenSigDeltaValue" SG_ 2158911488 ODDMC_DataID4 1;
BA_ "GenSigSendType" SG_ 2158911488 ODDMC_DataID4 12;
BA_ "VNSigInfotainment" SG_ 2158911488 ODDMC_DataID4 1;
BA_ "SignalType" SG_ 2158911488 ODDMC_DataID4 "UNM";
BA_ "PacketOrder" SG_ 2158911488 ODDMC_DataID4 11;
BA_ "SignalLongName" SG_ 2158911488 ODDMC_DataID4 "Open Display Interface Dynamic Data Multi Request CenterStack : Data ID Four";
BA_ "VNSigAllNodes" SG_ 2158911488 ODDMC_DataID4 1;
BA_ "GenSigSendType" SG_ 2158911488 ODDMC_DataID5Vld 10;
BA_ "VNSigInfotainment" SG_ 2158911488 ODDMC_DataID5Vld 1;
BA_ "SignalType" SG_ 2158911488 ODDMC_DataID5Vld "BLN";
BA_ "PacketOrder" SG_ 2158911488 ODDMC_DataID5Vld 2;
BA_ "SignalLongName" SG_ 2158911488 ODDMC_DataID5Vld "Open Display Interface Dynamic Data Multi Request CenterStack : Data ID Five Valid";
BA_ "VNSigAllNodes" SG_ 2158911488 ODDMC_DataID5Vld 1;
BA_ "GenSigDeltaValue" SG_ 2158911488 ODDMC_DataID5 1;
BA_ "GenSigSendType" SG_ 2158911488 ODDMC_DataID5 12;
BA_ "VNSigInfotainment" SG_ 2158911488 ODDMC_DataID5 1;
BA_ "SignalType" SG_ 2158911488 ODDMC_DataID5 "UNM";
BA_ "PacketOrder" SG_ 2158911488 ODDMC_DataID5 12;
BA_ "SignalLongName" SG_ 2158911488 ODDMC_DataID5 "Open Display Interface Dynamic Data Multi Request CenterStack : Data ID Five";
BA_ "VNSigAllNodes" SG_ 2158911488 ODDMC_DataID5 1;
BA_ "GenSigDeltaValue" SG_ 2158911488 ODDMC_FUCID 1;
BA_ "GenSigSendType" SG_ 2158911488 ODDMC_FUCID 12;
BA_ "VNSigInfotainment" SG_ 2158911488 ODDMC_FUCID 1;
BA_ "SignalType" SG_ 2158911488 ODDMC_FUCID "UNM";
BA_ "PacketOrder" SG_ 2158911488 ODDMC_FUCID 6;
BA_ "SignalLongName" SG_ 2158911488 ODDMC_FUCID "Open Display Interface Dynamic Data Multi Request Center Stack : Functional Unit Class ID";
BA_ "VNSigAllNodes" SG_ 2158911488 ODDMC_FUCID 1;
BA_ "GenSigDeltaValue" SG_ 2158878720 ODDLC_SubIdReqM 1;
BA_ "GenSigSendType" SG_ 2158878720 ODDLC_SubIdReqM 12;
BA_ "VNSigInfotainment" SG_ 2158878720 ODDLC_SubIdReqM 1;
BA_ "SignalType" SG_ 2158878720 ODDLC_SubIdReqM "UNM";
BA_ "PacketOrder" SG_ 2158878720 ODDLC_SubIdReqM 10;
BA_ "SignalLongName" SG_ 2158878720 ODDLC_SubIdReqM "Open Display Interface Dynamic Data List Request CenterStack : Sub Id Request Mask";
BA_ "VNSigAllNodes" SG_ 2158878720 ODDLC_SubIdReqM 1;
BA_ "GenSigSendType" SG_ 2158878720 ODDLC_WrpArnd 10;
BA_ "VNSigInfotainment" SG_ 2158878720 ODDLC_WrpArnd 1;
BA_ "SignalType" SG_ 2158878720 ODDLC_WrpArnd "BLN";
BA_ "PacketOrder" SG_ 2158878720 ODDLC_WrpArnd 9;
BA_ "SignalLongName" SG_ 2158878720 ODDLC_WrpArnd "Open Display Interface Dynamic Data List Request CenterStack : Wrap Around";
BA_ "VNSigAllNodes" SG_ 2158878720 ODDLC_WrpArnd 1;
BA_ "GenSigSendType" SG_ 2158878720 ODDLC_ReqType 10;
BA_ "VNSigInfotainment" SG_ 2158878720 ODDLC_ReqType 1;
BA_ "SignalType" SG_ 2158878720 ODDLC_ReqType "ENM";
BA_ "PacketOrder" SG_ 2158878720 ODDLC_ReqType 7;
BA_ "SignalLongName" SG_ 2158878720 ODDLC_ReqType "Open Display Interface Dynamic Data List Request CenterStack : Request Type";
BA_ "VNSigAllNodes" SG_ 2158878720 ODDLC_ReqType 1;
BA_ "GenSigSendType" SG_ 2158878720 ODDLC_ReqDir 10;
BA_ "VNSigInfotainment" SG_ 2158878720 ODDLC_ReqDir 1;
BA_ "SignalType" SG_ 2158878720 ODDLC_ReqDir "BLN";
BA_ "PacketOrder" SG_ 2158878720 ODDLC_ReqDir 5;
BA_ "SignalLongName" SG_ 2158878720 ODDLC_ReqDir "Open Display Interface Dynamic Data List Request CenterStack : Req Direction";
BA_ "VNSigAllNodes" SG_ 2158878720 ODDLC_ReqDir 1;
BA_ "GenSigDeltaValue" SG_ 2158878720 ODDLC_NmEntries 1;
BA_ "GenSigSendType" SG_ 2158878720 ODDLC_NmEntries 12;
BA_ "VNSigInfotainment" SG_ 2158878720 ODDLC_NmEntries 1;
BA_ "SignalType" SG_ 2158878720 ODDLC_NmEntries "UNM";
BA_ "PacketOrder" SG_ 2158878720 ODDLC_NmEntries 4;
BA_ "SignalLongName" SG_ 2158878720 ODDLC_NmEntries "Open Display Interface Dynamic Data List Request CenterStack : Num Entries";
BA_ "VNSigAllNodes" SG_ 2158878720 ODDLC_NmEntries 1;
BA_ "GenSigDeltaValue" SG_ 2158878720 ODDLC_Idx 1;
BA_ "GenSigSendType" SG_ 2158878720 ODDLC_Idx 12;
BA_ "VNSigInfotainment" SG_ 2158878720 ODDLC_Idx 1;
BA_ "SignalType" SG_ 2158878720 ODDLC_Idx "UNM";
BA_ "PacketOrder" SG_ 2158878720 ODDLC_Idx 6;
BA_ "SignalLongName" SG_ 2158878720 ODDLC_Idx "Open Display Interface Dynamic Data List Request CenterStack : Index";
BA_ "VNSigAllNodes" SG_ 2158878720 ODDLC_Idx 1;
BA_ "GenSigDeltaValue" SG_ 2158878720 ODDLC_FUCID 1;
BA_ "GenSigSendType" SG_ 2158878720 ODDLC_FUCID 12;
BA_ "VNSigInfotainment" SG_ 2158878720 ODDLC_FUCID 1;
BA_ "SignalType" SG_ 2158878720 ODDLC_FUCID "UNM";
BA_ "PacketOrder" SG_ 2158878720 ODDLC_FUCID 1;
BA_ "SignalLongName" SG_ 2158878720 ODDLC_FUCID "Open Display Interface Dynamic Data List Request CenterStack : Functional Unit Class ID";
BA_ "VNSigAllNodes" SG_ 2158878720 ODDLC_FUCID 1;
BA_ "GenSigSendType" SG_ 2158878720 ODDLC_DspMID 10;
BA_ "VNSigInfotainment" SG_ 2158878720 ODDLC_DspMID 1;
BA_ "SignalType" SG_ 2158878720 ODDLC_DspMID "ENM";
BA_ "PacketOrder" SG_ 2158878720 ODDLC_DspMID 3;
BA_ "SignalLongName" SG_ 2158878720 ODDLC_DspMID "Open Display Interface Dynamic Data List Request CenterStack : Display Mask Id";
BA_ "VNSigAllNodes" SG_ 2158878720 ODDLC_DspMID 1;
BA_ "GenSigDeltaValue" SG_ 2158878720 ODDLC_DataId 1;
BA_ "GenSigSendType" SG_ 2158878720 ODDLC_DataId 12;
BA_ "VNSigInfotainment" SG_ 2158878720 ODDLC_DataId 1;
BA_ "SignalType" SG_ 2158878720 ODDLC_DataId "UNM";
BA_ "PacketOrder" SG_ 2158878720 ODDLC_DataId 2;
BA_ "SignalLongName" SG_ 2158878720 ODDLC_DataId "Open Display Interface Dynamic Data List Request CenterStack : Data Id";
BA_ "VNSigAllNodes" SG_ 2158878720 ODDLC_DataId 1;
BA_ "GenSigSendType" SG_ 2158878720 ODDLC_BckgndFlag 10;
BA_ "VNSigInfotainment" SG_ 2158878720 ODDLC_BckgndFlag 1;
BA_ "SignalType" SG_ 2158878720 ODDLC_BckgndFlag "ENM";
BA_ "PacketOrder" SG_ 2158878720 ODDLC_BckgndFlag 8;
BA_ "SignalLongName" SG_ 2158878720 ODDLC_BckgndFlag "Open Display Interface Dynamic Data List Request CenterStack : Background Flag";
BA_ "VNSigAllNodes" SG_ 2158878720 ODDLC_BckgndFlag 1;
BA_ "GenSigDeltaValue" SG_ 2158845952 ODIAC_FUCID 1;
BA_ "GenSigSendType" SG_ 2158845952 ODIAC_FUCID 12;
BA_ "VNSigInfotainment" SG_ 2158845952 ODIAC_FUCID 1;
BA_ "SignalType" SG_ 2158845952 ODIAC_FUCID "UNM";
BA_ "PacketOrder" SG_ 2158845952 ODIAC_FUCID 2;
BA_ "SignalLongName" SG_ 2158845952 ODIAC_FUCID "Open Display Interface Action CenterStack : FU Class ID";
BA_ "VNSigAllNodes" SG_ 2158845952 ODIAC_FUCID 1;
BA_ "GenSigSendType" SG_ 2158845952 ODIAC_DspMID 10;
BA_ "VNSigInfotainment" SG_ 2158845952 ODIAC_DspMID 1;
BA_ "SignalType" SG_ 2158845952 ODIAC_DspMID "ENM";
BA_ "PacketOrder" SG_ 2158845952 ODIAC_DspMID 4;
BA_ "SignalLongName" SG_ 2158845952 ODIAC_DspMID "Open Display Interface Action CenterStack : Display Mask ID";
BA_ "VNSigAllNodes" SG_ 2158845952 ODIAC_DspMID 1;
BA_ "GenSigSendType" SG_ 2158845952 ODIAC_DaTy 10;
BA_ "VNSigInfotainment" SG_ 2158845952 ODIAC_DaTy 1;
BA_ "SignalType" SG_ 2158845952 ODIAC_DaTy "ENM";
BA_ "PacketOrder" SG_ 2158845952 ODIAC_DaTy 1;
BA_ "SignalLongName" SG_ 2158845952 ODIAC_DaTy "Open Display Interface Action CenterStack : DataType";
BA_ "VNSigAllNodes" SG_ 2158845952 ODIAC_DaTy 1;
BA_ "GenSigDeltaValue" SG_ 2158845952 ODIAC_ActnVal 1;
BA_ "GenSigSendType" SG_ 2158845952 ODIAC_ActnVal 12;
BA_ "VNSigInfotainment" SG_ 2158845952 ODIAC_ActnVal 1;
BA_ "SignalType" SG_ 2158845952 ODIAC_ActnVal "UNM";
BA_ "PacketOrder" SG_ 2158845952 ODIAC_ActnVal 5;
BA_ "SignalLongName" SG_ 2158845952 ODIAC_ActnVal "Open Display Interface Action CenterStack : Action Value";
BA_ "VNSigAllNodes" SG_ 2158845952 ODIAC_ActnVal 1;
BA_ "GenSigDeltaValue" SG_ 2158845952 ODIAC_ActnID 1;
BA_ "GenSigSendType" SG_ 2158845952 ODIAC_ActnID 12;
BA_ "VNSigInfotainment" SG_ 2158845952 ODIAC_ActnID 1;
BA_ "SignalType" SG_ 2158845952 ODIAC_ActnID "UNM";
BA_ "PacketOrder" SG_ 2158845952 ODIAC_ActnID 3;
BA_ "SignalLongName" SG_ 2158845952 ODIAC_ActnID "Open Display Interface Action CenterStack : Action ID";
BA_ "VNSigAllNodes" SG_ 2158845952 ODIAC_ActnID 1;
BA_ "GenSigSendType" SG_ 2151079936 PDIMPrsnt 10;
BA_ "GenSigSendOnInit" SG_ 2151079936 PDIMPrsnt 2;
BA_ "VNSigInfotainment" SG_ 2151079936 PDIMPrsnt 1;
BA_ "SignalType" SG_ 2151079936 PDIMPrsnt "BLN";
BA_ "SignalLongName" SG_ 2151079936 PDIMPrsnt "Preferred Device Interface Module Present";
BA_ "GenSigStartValue" SG_ 2151079936 PDIMPrsnt 1;
BA_ "VNSigAllNodes" SG_ 2151079936 PDIMPrsnt 1;
BA_ "SignalType" SG_ 1608 DgnInf "UNM";
BA_ "SignalLongName" SG_ 1608 DgnInf "Diagnostic Information";
BA_ "VNSigDiagnostic" SG_ 1608 DgnInf 1;
BA_ "VNSigAllNodes" SG_ 1608 DgnInf 1;
BA_ "VNSigPrimaryTriggering" SG_ 1576 VectraSpcNWMgtD 1;
BA_ "VNSigRemoteDiagnostics" SG_ 1576 VectraSpcNWMgtD 1;
BA_ "VNSigInfotainment" SG_ 1576 VectraSpcNWMgtD 1;
BA_ "VNSigParkedVehicle" SG_ 1576 VectraSpcNWMgtD 1;
BA_ "VNSigIntermediate" SG_ 1576 VectraSpcNWMgtD 1;
BA_ "VNSigUnused_4" SG_ 1576 VectraSpcNWMgtD 1;
BA_ "SignalType" SG_ 1576 VectraSpcNWMgtD "UNM";
BA_ "SignalLongName" SG_ 1576 VectraSpcNWMgtD "Vectra Specific Network Management Data";
BA_ "VNSigDiagnostic" SG_ 1576 VectraSpcNWMgtD 1;
BA_ "VNSigAllNodes" SG_ 1576 VectraSpcNWMgtD 1;
BA_ "GenSigDeltaValue" SG_ 1352 DgnInf_LS548 1;
BA_ "GenSigSendType" SG_ 1352 DgnInf_LS548 12;
BA_ "SignalType" SG_ 1352 DgnInf_LS548 "UNM";
BA_ "SignalLongName" SG_ 1352 DgnInf_LS548 "Diagnostic Information LS548";
BA_ "VNSigDiagnostic" SG_ 1352 DgnInf_LS548 1;
BA_ "VNSigAllNodes" SG_ 1352 DgnInf_LS548 1;
BA_ "GenSigSendType" SG_ 2153824256 TeenDrvAccelLimIO 10;
BA_ "SignalType" SG_ 2153824256 TeenDrvAccelLimIO "BLN";
BA_ "SignalLongName" SG_ 2153824256 TeenDrvAccelLimIO "Teen Driver Acceleration Limit Indication On";
BA_ "VNSigAllNodes" SG_ 2153824256 TeenDrvAccelLimIO 1;
BA_ "GenSigDeltaValue" SG_ 2153824256 TeenDrvDistDrvnRpt 1;
BA_ "GenSigSendType" SG_ 2153824256 TeenDrvDistDrvnRpt 12;
BA_ "GenSigSendOnInit" SG_ 2153824256 TeenDrvDistDrvnRpt 2;
BA_ "SignalType" SG_ 2153824256 TeenDrvDistDrvnRpt "UNM";
BA_ "SignalLongName" SG_ 2153824256 TeenDrvDistDrvnRpt "Teen Driver Distance Driven Report";
BA_ "VNSigAllNodes" SG_ 2153824256 TeenDrvDistDrvnRpt 1;
BA_ "GenSigDeltaValue" SG_ 2153824256 TnDrvOvSpdEvntsRpt 1;
BA_ "GenSigSendType" SG_ 2153824256 TnDrvOvSpdEvntsRpt 12;
BA_ "GenSigSendOnInit" SG_ 2153824256 TnDrvOvSpdEvntsRpt 2;
BA_ "SignalType" SG_ 2153824256 TnDrvOvSpdEvntsRpt "UNM";
BA_ "SignalLongName" SG_ 2153824256 TnDrvOvSpdEvntsRpt "Teen Driver Overspeed Events Report";
BA_ "VNSigAllNodes" SG_ 2153824256 TnDrvOvSpdEvntsRpt 1;
BA_ "GenSigSendType" SG_ 2153824256 TeenDrvAct 10;
BA_ "GenSigSendOnInit" SG_ 2153824256 TeenDrvAct 2;
BA_ "SignalType" SG_ 2153824256 TeenDrvAct "BLN";
BA_ "SignalLongName" SG_ 2153824256 TeenDrvAct "Teen Driver Active";
BA_ "VNSigAllNodes" SG_ 2153824256 TeenDrvAct 1;
BA_ "GenSigSendType" SG_ 2153824256 TeenDrvRsp 10;
BA_ "GenSigSendOnInit" SG_ 2153824256 TeenDrvRsp 2;
BA_ "SignalType" SG_ 2153824256 TeenDrvRsp "ENM";
BA_ "SignalLongName" SG_ 2153824256 TeenDrvRsp "Teen Driver Response";
BA_ "VNSigAllNodes" SG_ 2153824256 TeenDrvRsp 1;
BA_ "GenSigSendType" SG_ 2153824256 TeenDrvFtrAvl 10;
BA_ "GenSigSendOnInit" SG_ 2153824256 TeenDrvFtrAvl 2;
BA_ "SignalType" SG_ 2153824256 TeenDrvFtrAvl "BLN";
BA_ "SignalLongName" SG_ 2153824256 TeenDrvFtrAvl "Teen Driver Feature Available";
BA_ "VNSigAllNodes" SG_ 2153824256 TeenDrvFtrAvl 1;
BA_ "GenSigSendType" SG_ 2153824256 TeenDrvPINStrd 10;
BA_ "GenSigSendOnInit" SG_ 2153824256 TeenDrvPINStrd 2;
BA_ "SignalType" SG_ 2153824256 TeenDrvPINStrd "BLN";
BA_ "SignalLongName" SG_ 2153824256 TeenDrvPINStrd "Teen Driver PIN Stored";
BA_ "VNSigAllNodes" SG_ 2153824256 TeenDrvPINStrd 1;
BA_ "GenSigSendType" SG_ 2153824256 TnDrvGapAdjUnbIO 10;
BA_ "SignalType" SG_ 2153824256 TnDrvGapAdjUnbIO "BLN";
BA_ "SignalLongName" SG_ 2153824256 TnDrvGapAdjUnbIO "Teen Driver Gap Adjust Unavailable Indication On";
BA_ "VNSigAllNodes" SG_ 2153824256 TnDrvGapAdjUnbIO 1;
BA_ "GenSigSendType" SG_ 2153824256 TnDrvOvrSpdIO 10;
BA_ "SignalType" SG_ 2153824256 TnDrvOvrSpdIO "BLN";
BA_ "SignalLongName" SG_ 2153824256 TnDrvOvrSpdIO "Teen Driver Overspeed Indication On";
BA_ "VNSigAllNodes" SG_ 2153824256 TnDrvOvrSpdIO 1;
BA_ "GenSigSendType" SG_ 2153824256 TDOvSpdWrnCstStAvl 10;
BA_ "GenSigSendOnInit" SG_ 2153824256 TDOvSpdWrnCstStAvl 2;
BA_ "SignalType" SG_ 2153824256 TDOvSpdWrnCstStAvl "BLN";
BA_ "SignalLongName" SG_ 2153824256 TDOvSpdWrnCstStAvl "Teen Driver Overspeed Warning Customization Setting Available";
BA_ "VNSigAllNodes" SG_ 2153824256 TDOvSpdWrnCstStAvl 1;
BA_ "GenSigDeltaValue" SG_ 2153824256 TDOWCCSV_CrStVl 16;
BA_ "GenSigSendType" SG_ 2153824256 TDOWCCSV_CrStVl 12;
BA_ "GenSigSendOnInit" SG_ 2153824256 TDOWCCSV_CrStVl 2;
BA_ "SignalType" SG_ 2153824256 TDOWCCSV_CrStVl "UNM";
BA_ "PacketOrder" SG_ 2153824256 TDOWCCSV_CrStVl 2;
BA_ "SignalLongName" SG_ 2153824256 TDOWCCSV_CrStVl "Teen Driver Overspeed Warning Customization Current Setting Value : Current Setting Value";
BA_ "VNSigAllNodes" SG_ 2153824256 TDOWCCSV_CrStVl 1;
BA_ "GenSigSendType" SG_ 2153824256 TDOWCCSV_CrStat 10;
BA_ "GenSigSendOnInit" SG_ 2153824256 TDOWCCSV_CrStat 2;
BA_ "SignalType" SG_ 2153824256 TDOWCCSV_CrStat "ENM";
BA_ "PacketOrder" SG_ 2153824256 TDOWCCSV_CrStat 1;
BA_ "SignalLongName" SG_ 2153824256 TDOWCCSV_CrStat "Teen Driver Overspeed Warning Customization Current Setting Value : Current Status";
BA_ "VNSigAllNodes" SG_ 2153824256 TDOWCCSV_CrStat 1;
BA_ "GenSigSendType" SG_ 2153824256 TnDrvSpdLmtCstStAvl 10;
BA_ "GenSigSendOnInit" SG_ 2153824256 TnDrvSpdLmtCstStAvl 2;
BA_ "SignalType" SG_ 2153824256 TnDrvSpdLmtCstStAvl "BLN";
BA_ "SignalLongName" SG_ 2153824256 TnDrvSpdLmtCstStAvl "Teen Driver Speed Limit Customization Setting Available";
BA_ "VNSigAllNodes" SG_ 2153824256 TnDrvSpdLmtCstStAvl 1;
BA_ "GenSigSendType" SG_ 2153824256 TDSLCCSV_SpLmtStat 10;
BA_ "GenSigSendOnInit" SG_ 2153824256 TDSLCCSV_SpLmtStat 2;
BA_ "SignalType" SG_ 2153824256 TDSLCCSV_SpLmtStat "ENM";
BA_ "PacketOrder" SG_ 2153824256 TDSLCCSV_SpLmtStat 1;
BA_ "SignalLongName" SG_ 2153824256 TDSLCCSV_SpLmtStat "Teen Driver Speed Limit Customization Current Setting Value : Speed Limit Status";
BA_ "VNSigAllNodes" SG_ 2153824256 TDSLCCSV_SpLmtStat 1;
BA_ "GenSigSendType" SG_ 2153824256 TDSLCCSV_SpLmDisVl 12;
BA_ "GenSigSendOnInit" SG_ 2153824256 TDSLCCSV_SpLmDisVl 2;
BA_ "SignalType" SG_ 2153824256 TDSLCCSV_SpLmDisVl "UNM";
BA_ "PacketOrder" SG_ 2153824256 TDSLCCSV_SpLmDisVl 2;
BA_ "SignalLongName" SG_ 2153824256 TDSLCCSV_SpLmDisVl "Teen Driver Speed Limit Customization Current Setting Value : Speed Limit Display Value";
BA_ "VNSigAllNodes" SG_ 2153824256 TDSLCCSV_SpLmDisVl 1;
BA_ "GenSigSendType" SG_ 2151907328 StrgWhlUnit1SwStat 10;
BA_ "VNSigInfotainment" SG_ 2151907328 StrgWhlUnit1SwStat 1;
BA_ "SignalType" SG_ 2151907328 StrgWhlUnit1SwStat "ENM";
BA_ "SignalLongName" SG_ 2151907328 StrgWhlUnit1SwStat "Steering Wheel Unit #1 Switch Status";
BA_ "VNSigAllNodes" SG_ 2151907328 StrgWhlUnit1SwStat 1;
BA_ "GenSigSendType" SG_ 2151907328 StrgWhlUnit2SwStat 10;
BA_ "VNSigInfotainment" SG_ 2151907328 StrgWhlUnit2SwStat 1;
BA_ "SignalType" SG_ 2151907328 StrgWhlUnit2SwStat "ENM";
BA_ "SignalLongName" SG_ 2151907328 StrgWhlUnit2SwStat "Steering Wheel Unit #2 Switch Status";
BA_ "VNSigAllNodes" SG_ 2151907328 StrgWhlUnit2SwStat 1;
BA_ "GenSigSendOnInit" SG_ 2162982912 VehIdNmDig10_17 2;
BA_ "VNSigInfotainment" SG_ 2162982912 VehIdNmDig10_17 1;
BA_ "SignalType" SG_ 2162982912 VehIdNmDig10_17 "ASC";
BA_ "SignalLongName" SG_ 2162982912 VehIdNmDig10_17 "Vehicle Identification Number Digits 10-17";
BA_ "VNSigAllNodes" SG_ 2162982912 VehIdNmDig10_17 1;
BA_ "GenSigSendOnInit" SG_ 2162966528 VehIdNmDig2_9 2;
BA_ "VNSigInfotainment" SG_ 2162966528 VehIdNmDig2_9 1;
BA_ "SignalType" SG_ 2162966528 VehIdNmDig2_9 "ASC";
BA_ "SignalLongName" SG_ 2162966528 VehIdNmDig2_9 "Vehicle Identification Number Digits 2-9";
BA_ "VNSigAllNodes" SG_ 2162966528 VehIdNmDig2_9 1;
BA_ "GenSigDeltaValue" SG_ 2152497152 PDRRI_LpDiffTm10s 10;
BA_ "GenSigSendType" SG_ 2152497152 PDRRI_LpDiffTm10s 12;
BA_ "VNSigInfotainment" SG_ 2152497152 PDRRI_LpDiffTm10s 1;
BA_ "SignalType" SG_ 2152497152 PDRRI_LpDiffTm10s "UNM";
BA_ "PacketOrder" SG_ 2152497152 PDRRI_LpDiffTm10s 5;
BA_ "SignalLongName" SG_ 2152497152 PDRRI_LpDiffTm10s "Performance Data Recorder Realtime Information : Lap Differential Time Tenths of a Second";
BA_ "VNSigAllNodes" SG_ 2152497152 PDRRI_LpDiffTm10s 1;
BA_ "GenSigDeltaValue" SG_ 2152497152 PDRRI_LpDiffTmSecs 1;
BA_ "GenSigSendType" SG_ 2152497152 PDRRI_LpDiffTmSecs 12;
BA_ "VNSigInfotainment" SG_ 2152497152 PDRRI_LpDiffTmSecs 1;
BA_ "SignalType" SG_ 2152497152 PDRRI_LpDiffTmSecs "UNM";
BA_ "PacketOrder" SG_ 2152497152 PDRRI_LpDiffTmSecs 4;
BA_ "SignalLongName" SG_ 2152497152 PDRRI_LpDiffTmSecs "Performance Data Recorder Realtime Information : Lap Differential Time Seconds";
BA_ "VNSigAllNodes" SG_ 2152497152 PDRRI_LpDiffTmSecs 1;
BA_ "GenSigDeltaValue" SG_ 2152497152 PDRRI_CrLpTm10sSec 10;
BA_ "GenSigSendType" SG_ 2152497152 PDRRI_CrLpTm10sSec 12;
BA_ "VNSigInfotainment" SG_ 2152497152 PDRRI_CrLpTm10sSec 1;
BA_ "SignalType" SG_ 2152497152 PDRRI_CrLpTm10sSec "UNM";
BA_ "PacketOrder" SG_ 2152497152 PDRRI_CrLpTm10sSec 3;
BA_ "SignalLongName" SG_ 2152497152 PDRRI_CrLpTm10sSec "Performance Data Recorder Realtime Information : Current Lap Time Tenths of a Second";
BA_ "VNSigAllNodes" SG_ 2152497152 PDRRI_CrLpTm10sSec 1;
BA_ "GenSigDeltaValue" SG_ 2152497152 PDRRI_CrLpTmSecs 1;
BA_ "GenSigSendType" SG_ 2152497152 PDRRI_CrLpTmSecs 12;
BA_ "VNSigInfotainment" SG_ 2152497152 PDRRI_CrLpTmSecs 1;
BA_ "SignalType" SG_ 2152497152 PDRRI_CrLpTmSecs "UNM";
BA_ "PacketOrder" SG_ 2152497152 PDRRI_CrLpTmSecs 2;
BA_ "SignalLongName" SG_ 2152497152 PDRRI_CrLpTmSecs "Performance Data Recorder Realtime Information : Current Lap Time Seconds";
BA_ "VNSigAllNodes" SG_ 2152497152 PDRRI_CrLpTmSecs 1;
BA_ "GenSigDeltaValue" SG_ 2152497152 PDRRI_CrLpTmMins 1;
BA_ "GenSigSendType" SG_ 2152497152 PDRRI_CrLpTmMins 12;
BA_ "VNSigInfotainment" SG_ 2152497152 PDRRI_CrLpTmMins 1;
BA_ "SignalType" SG_ 2152497152 PDRRI_CrLpTmMins "UNM";
BA_ "PacketOrder" SG_ 2152497152 PDRRI_CrLpTmMins 1;
BA_ "SignalLongName" SG_ 2152497152 PDRRI_CrLpTmMins "Performance Data Recorder Realtime Information : Current Lap Time Minutes";
BA_ "VNSigAllNodes" SG_ 2152497152 PDRRI_CrLpTmMins 1;
BA_ "GenSigDeltaValue" SG_ 2152480768 PDRLLI_LstLpTmSecs 1;
BA_ "GenSigSendType" SG_ 2152480768 PDRLLI_LstLpTmSecs 12;
BA_ "GenSigSendOnInit" SG_ 2152480768 PDRLLI_LstLpTmSecs 1;
BA_ "VNSigInfotainment" SG_ 2152480768 PDRLLI_LstLpTmSecs 1;
BA_ "SignalType" SG_ 2152480768 PDRLLI_LstLpTmSecs "UNM";
BA_ "PacketOrder" SG_ 2152480768 PDRLLI_LstLpTmSecs 2;
BA_ "SignalLongName" SG_ 2152480768 PDRLLI_LstLpTmSecs "Performance Data Recorder Last Lap Information : Last Lap Time Seconds";
BA_ "VNSigAllNodes" SG_ 2152480768 PDRLLI_LstLpTmSecs 1;
BA_ "GenSigDeltaValue" SG_ 2152480768 PDRLLI_LstLpTmMins 1;
BA_ "GenSigSendType" SG_ 2152480768 PDRLLI_LstLpTmMins 12;
BA_ "GenSigSendOnInit" SG_ 2152480768 PDRLLI_LstLpTmMins 1;
BA_ "VNSigInfotainment" SG_ 2152480768 PDRLLI_LstLpTmMins 1;
BA_ "SignalType" SG_ 2152480768 PDRLLI_LstLpTmMins "UNM";
BA_ "PacketOrder" SG_ 2152480768 PDRLLI_LstLpTmMins 1;
BA_ "SignalLongName" SG_ 2152480768 PDRLLI_LstLpTmMins "Performance Data Recorder Last Lap Information : Last Lap Time Minutes";
BA_ "VNSigAllNodes" SG_ 2152480768 PDRLLI_LstLpTmMins 1;
BA_ "GenSigDeltaValue" SG_ 2152480768 PDRLLI_LstLpTm100s 100;
BA_ "GenSigSendType" SG_ 2152480768 PDRLLI_LstLpTm100s 12;
BA_ "GenSigSendOnInit" SG_ 2152480768 PDRLLI_LstLpTm100s 1;
BA_ "VNSigInfotainment" SG_ 2152480768 PDRLLI_LstLpTm100s 1;
BA_ "SignalType" SG_ 2152480768 PDRLLI_LstLpTm100s "UNM";
BA_ "PacketOrder" SG_ 2152480768 PDRLLI_LstLpTm100s 3;
BA_ "SignalLongName" SG_ 2152480768 PDRLLI_LstLpTm100s "Performance Data Recorder Last Lap Information : Last Lap Time Hundredths of a Second";
BA_ "VNSigAllNodes" SG_ 2152480768 PDRLLI_LstLpTm100s 1;
BA_ "GenSigDeltaValue" SG_ 2152480768 PDRBLI_BstLpTmSecs 1;
BA_ "GenSigSendType" SG_ 2152480768 PDRBLI_BstLpTmSecs 12;
BA_ "GenSigSendOnInit" SG_ 2152480768 PDRBLI_BstLpTmSecs 1;
BA_ "VNSigInfotainment" SG_ 2152480768 PDRBLI_BstLpTmSecs 1;
BA_ "SignalType" SG_ 2152480768 PDRBLI_BstLpTmSecs "UNM";
BA_ "PacketOrder" SG_ 2152480768 PDRBLI_BstLpTmSecs 2;
BA_ "SignalLongName" SG_ 2152480768 PDRBLI_BstLpTmSecs "Performance Data Recorder Best Lap Information : Best Lap Time Seconds";
BA_ "VNSigAllNodes" SG_ 2152480768 PDRBLI_BstLpTmSecs 1;
BA_ "GenSigDeltaValue" SG_ 2152480768 PDRBLI_BstLpTmMins 1;
BA_ "GenSigSendType" SG_ 2152480768 PDRBLI_BstLpTmMins 12;
BA_ "GenSigSendOnInit" SG_ 2152480768 PDRBLI_BstLpTmMins 1;
BA_ "VNSigInfotainment" SG_ 2152480768 PDRBLI_BstLpTmMins 1;
BA_ "SignalType" SG_ 2152480768 PDRBLI_BstLpTmMins "UNM";
BA_ "PacketOrder" SG_ 2152480768 PDRBLI_BstLpTmMins 1;
BA_ "SignalLongName" SG_ 2152480768 PDRBLI_BstLpTmMins "Performance Data Recorder Best Lap Information : Best Lap Time Minutes";
BA_ "VNSigAllNodes" SG_ 2152480768 PDRBLI_BstLpTmMins 1;
BA_ "GenSigDeltaValue" SG_ 2152480768 PDRBLI_BstLpTm100s 100;
BA_ "GenSigSendType" SG_ 2152480768 PDRBLI_BstLpTm100s 12;
BA_ "GenSigSendOnInit" SG_ 2152480768 PDRBLI_BstLpTm100s 1;
BA_ "VNSigInfotainment" SG_ 2152480768 PDRBLI_BstLpTm100s 1;
BA_ "SignalType" SG_ 2152480768 PDRBLI_BstLpTm100s "UNM";
BA_ "PacketOrder" SG_ 2152480768 PDRBLI_BstLpTm100s 3;
BA_ "SignalLongName" SG_ 2152480768 PDRBLI_BstLpTm100s "Performance Data Recorder Best Lap Information : Best Lap Time Hundredths of a Second";
BA_ "VNSigAllNodes" SG_ 2152480768 PDRBLI_BstLpTm100s 1;
BA_ "SignalType" SG_ 1610 DgnInf "UNM";
BA_ "SignalLongName" SG_ 1610 DgnInf "Diagnostic Information";
BA_ "VNSigDiagnostic" SG_ 1610 DgnInf 1;
BA_ "VNSigAllNodes" SG_ 1610 DgnInf 1;
BA_ "VNSigPrimaryTriggering" SG_ 1578 VectraSpcNWMgtD 1;
BA_ "VNSigRemoteDiagnostics" SG_ 1578 VectraSpcNWMgtD 1;
BA_ "VNSigInfotainment" SG_ 1578 VectraSpcNWMgtD 1;
BA_ "VNSigParkedVehicle" SG_ 1578 VectraSpcNWMgtD 1;
BA_ "VNSigIntermediate" SG_ 1578 VectraSpcNWMgtD 1;
BA_ "VNSigUnused_4" SG_ 1578 VectraSpcNWMgtD 1;
BA_ "SignalType" SG_ 1578 VectraSpcNWMgtD "UNM";
BA_ "SignalLongName" SG_ 1578 VectraSpcNWMgtD "Vectra Specific Network Management Data";
BA_ "VNSigDiagnostic" SG_ 1578 VectraSpcNWMgtD 1;
BA_ "VNSigAllNodes" SG_ 1578 VectraSpcNWMgtD 1;
BA_ "GenSigDeltaValue" SG_ 1354 DgnInf_LS54A 1;
BA_ "GenSigSendType" SG_ 1354 DgnInf_LS54A 12;
BA_ "SignalType" SG_ 1354 DgnInf_LS54A "UNM";
BA_ "SignalLongName" SG_ 1354 DgnInf_LS54A "Diagnostic Information LS54A";
BA_ "VNSigDiagnostic" SG_ 1354 DgnInf_LS54A 1;
BA_ "VNSigAllNodes" SG_ 1354 DgnInf_LS54A 1;
BA_ "SignalType" SG_ 1606 DgnInf "UNM";
BA_ "SignalLongName" SG_ 1606 DgnInf "Diagnostic Information";
BA_ "VNSigDiagnostic" SG_ 1606 DgnInf 1;
BA_ "VNSigAllNodes" SG_ 1606 DgnInf 1;
BA_ "VNSigPrimaryTriggering" SG_ 1574 VectraSpcNWMgtD 1;
BA_ "VNSigRemoteDiagnostics" SG_ 1574 VectraSpcNWMgtD 1;
BA_ "VNSigInfotainment" SG_ 1574 VectraSpcNWMgtD 1;
BA_ "VNSigParkedVehicle" SG_ 1574 VectraSpcNWMgtD 1;
BA_ "VNSigIntermediate" SG_ 1574 VectraSpcNWMgtD 1;
BA_ "VNSigUnused_4" SG_ 1574 VectraSpcNWMgtD 1;
BA_ "SignalType" SG_ 1574 VectraSpcNWMgtD "UNM";
BA_ "SignalLongName" SG_ 1574 VectraSpcNWMgtD "Vectra Specific Network Management Data";
BA_ "VNSigDiagnostic" SG_ 1574 VectraSpcNWMgtD 1;
BA_ "VNSigAllNodes" SG_ 1574 VectraSpcNWMgtD 1;
BA_ "GenSigDeltaValue" SG_ 1350 DgnInf_LS546 1;
BA_ "GenSigSendType" SG_ 1350 DgnInf_LS546 12;
BA_ "SignalType" SG_ 1350 DgnInf_LS546 "UNM";
BA_ "SignalLongName" SG_ 1350 DgnInf_LS546 "Diagnostic Information LS546";
BA_ "VNSigDiagnostic" SG_ 1350 DgnInf_LS546 1;
BA_ "VNSigAllNodes" SG_ 1350 DgnInf_LS546 1;
BA_REL_ "GenSigSuprvResp" BU_SG_REL_ VCU_LE SG_ 2150252544 ECHG_YAxisMaxVal 1;
BA_REL_ "GenSigSuprvResp" BU_SG_REL_ CSM_LE SG_ 2150252544 ECHG_YAxisMaxVal 1;
BA_REL_ "GenSigSuprvResp" BU_SG_REL_ RadioHead_LE SG_ 2150252544 ECHG_YAxisMaxVal 1;
BA_REL_ "GenSigSuprvResp" BU_SG_REL_ VCU_LE SG_ 2150252544 ECHG_XAxisTkMrkIntvl 1;
BA_REL_ "GenSigSuprvResp" BU_SG_REL_ CSM_LE SG_ 2150252544 ECHG_XAxisTkMrkIntvl 1;
BA_REL_ "GenSigSuprvResp" BU_SG_REL_ RadioHead_LE SG_ 2150252544 ECHG_XAxisTkMrkIntvl 1;
BA_REL_ "GenSigSuprvResp" BU_SG_REL_ VCU_LE SG_ 2150252544 ECHG_Column10 1;
BA_REL_ "GenSigSuprvResp" BU_SG_REL_ CSM_LE SG_ 2150252544 ECHG_Column10 1;
BA_REL_ "GenSigSuprvResp" BU_SG_REL_ RadioHead_LE SG_ 2150252544 ECHG_Column10 1;
BA_REL_ "GenSigSuprvResp" BU_SG_REL_ VCU_LE SG_ 2150252544 ECHG_Column09 1;
BA_REL_ "GenSigSuprvResp" BU_SG_REL_ CSM_LE SG_ 2150252544 ECHG_Column09 1;
BA_REL_ "GenSigSuprvResp" BU_SG_REL_ RadioHead_LE SG_ 2150252544 ECHG_Column09 1;
BA_REL_ "GenSigSuprvResp" BU_SG_REL_ VCU_LE SG_ 2150252544 ECHG_Column08 1;
BA_REL_ "GenSigSuprvResp" BU_SG_REL_ CSM_LE SG_ 2150252544 ECHG_Column08 1;
BA_REL_ "GenSigSuprvResp" BU_SG_REL_ RadioHead_LE SG_ 2150252544 ECHG_Column08 1;
BA_REL_ "GenSigSuprvResp" BU_SG_REL_ VCU_LE SG_ 2150252544 ECHG_Column07 1;
BA_REL_ "GenSigSuprvResp" BU_SG_REL_ CSM_LE SG_ 2150252544 ECHG_Column07 1;
BA_REL_ "GenSigSuprvResp" BU_SG_REL_ RadioHead_LE SG_ 2150252544 ECHG_Column07 1;
BA_REL_ "GenSigSuprvResp" BU_SG_REL_ VCU_LE SG_ 2150252544 ECHG_Column06 1;
BA_REL_ "GenSigSuprvResp" BU_SG_REL_ CSM_LE SG_ 2150252544 ECHG_Column06 1;
BA_REL_ "GenSigSuprvResp" BU_SG_REL_ RadioHead_LE SG_ 2150252544 ECHG_Column06 1;
BA_REL_ "GenSigSuprvResp" BU_SG_REL_ VCU_LE SG_ 2150252544 ECHG_Column05 1;
BA_REL_ "GenSigSuprvResp" BU_SG_REL_ CSM_LE SG_ 2150252544 ECHG_Column05 1;
BA_REL_ "GenSigSuprvResp" BU_SG_REL_ RadioHead_LE SG_ 2150252544 ECHG_Column05 1;
BA_REL_ "GenSigSuprvResp" BU_SG_REL_ VCU_LE SG_ 2150252544 ECHG_Column04 1;
BA_REL_ "GenSigSuprvResp" BU_SG_REL_ CSM_LE SG_ 2150252544 ECHG_Column04 1;
BA_REL_ "GenSigSuprvResp" BU_SG_REL_ RadioHead_LE SG_ 2150252544 ECHG_Column04 1;
BA_REL_ "GenSigSuprvResp" BU_SG_REL_ VCU_LE SG_ 2150252544 ECHG_Column03 1;
BA_REL_ "GenSigSuprvResp" BU_SG_REL_ CSM_LE SG_ 2150252544 ECHG_Column03 1;
BA_REL_ "GenSigSuprvResp" BU_SG_REL_ RadioHead_LE SG_ 2150252544 ECHG_Column03 1;
BA_REL_ "GenSigSuprvResp" BU_SG_REL_ VCU_LE SG_ 2150252544 ECHG_Column02 1;
BA_REL_ "GenSigSuprvResp" BU_SG_REL_ CSM_LE SG_ 2150252544 ECHG_Column02 1;
BA_REL_ "GenSigSuprvResp" BU_SG_REL_ RadioHead_LE SG_ 2150252544 ECHG_Column02 1;
BA_REL_ "GenSigSuprvResp" BU_SG_REL_ VCU_LE SG_ 2150252544 ECHG_Column01 1;
BA_REL_ "GenSigSuprvResp" BU_SG_REL_ CSM_LE SG_ 2150252544 ECHG_Column01 1;
BA_REL_ "GenSigSuprvResp" BU_SG_REL_ RadioHead_LE SG_ 2150252544 ECHG_Column01 1;
BA_REL_ "GenSigSuprvResp" BU_SG_REL_ VCU_LE SG_ 2150252544 ECHG_EngyCnsmdAvg 1;
BA_REL_ "GenSigSuprvResp" BU_SG_REL_ CSM_LE SG_ 2150252544 ECHG_EngyCnsmdAvg 1;
BA_REL_ "GenSigSuprvResp" BU_SG_REL_ RadioHead_LE SG_ 2150252544 ECHG_EngyCnsmdAvg 1;
BA_REL_ "GenSigSuprvResp" BU_SG_REL_ VCU_LE SG_ 2150252544 ECHG_MeasUnit 1;
BA_REL_ "GenSigSuprvResp" BU_SG_REL_ CSM_LE SG_ 2150252544 ECHG_MeasUnit 1;
BA_REL_ "GenSigSuprvResp" BU_SG_REL_ RadioHead_LE SG_ 2150252544 ECHG_MeasUnit 1;
BA_REL_ "GenSigSuprvResp" BU_SG_REL_ VCU_LE SG_ 2150383616 BatPrpDspPwrLvlPct 1;
BA_REL_ "GenSigSuprvResp" BU_SG_REL_ IPC_LE SG_ 2150383616 BatPrpDspPwrLvlPct 1;
BA_REL_ "GenSigSuprvResp" BU_SG_REL_ VCU_LE SG_ 2150383616 PrpDspTtlPwr 1;
BA_REL_ "GenSigSuprvResp" BU_SG_REL_ IPC_LE SG_ 2150383616 PrpDspTtlPwr 1;
BA_REL_ "GenSigSuprvResp" BU_SG_REL_ VCU_LE SG_ 2150383616 PrpCapDspOpPs 1;
BA_REL_ "GenSigSuprvResp" BU_SG_REL_ IPC_LE SG_ 2150383616 PrpCapDspOpPs 1;
BA_REL_ "GenSigSuprvResp" BU_SG_REL_ VCU_LE SG_ 2150383616 EstElecPrpCap 1;
BA_REL_ "GenSigSuprvResp" BU_SG_REL_ IPC_LE SG_ 2150383616 EstElecPrpCap 1;
BA_REL_ "GenSigSuprvResp" BU_SG_REL_ VCU_LE SG_ 2150383616 EngPrpDspPwrLvlPct 1;
BA_REL_ "GenSigSuprvResp" BU_SG_REL_ IPC_LE SG_ 2150383616 EngPrpDspPwrLvlPct 1;
BA_REL_ "GenSigSuprvResp" BU_SG_REL_ VCU_LE SG_ 2150113280 HVChrgInhbRsn 1;
BA_REL_ "GenSigSuprvResp" BU_SG_REL_ IPC_LE SG_ 2150113280 HVChrgInhbRsn 1;
BA_REL_ "GenSigSuprvResp" BU_SG_REL_ VCU_LE SG_ 2150113280 DrvCyclTrpDstTrvld 1;
BA_REL_ "GenSigSuprvResp" BU_SG_REL_ IPC_LE SG_ 2150113280 DrvCyclTrpDstTrvld 1;
BA_REL_ "GenSigSuprvResp" BU_SG_REL_ VCU_LE SG_ 2150113280 DrvCyclElecEngyEcon 1;
BA_REL_ "GenSigSuprvResp" BU_SG_REL_ IPC_LE SG_ 2150113280 DrvCyclElecEngyEcon 1;
BA_REL_ "GenSigSuprvResp" BU_SG_REL_ VCU_LE SG_ 2150113280 DrvCycElEnrgUsd 1;
BA_REL_ "GenSigSuprvResp" BU_SG_REL_ RadioHead_LE SG_ 2150113280 DrvCycElEnrgUsd 1;
BA_REL_ "GenSigSuprvResp" BU_SG_REL_ VCU_LE SG_ 2151858176 DrvCycElecEngySt4 1;
BA_REL_ "GenSigSuprvResp" BU_SG_REL_ CSM_LE SG_ 2151858176 DrvCycElecEngySt4 1;
BA_REL_ "GenSigSuprvResp" BU_SG_REL_ RadioHead_LE SG_ 2151858176 DrvCycElecEngySt4 1;
BA_REL_ "GenSigSuprvResp" BU_SG_REL_ VCU_LE SG_ 2151858176 DrvCycElecEngySt3 1;
BA_REL_ "GenSigSuprvResp" BU_SG_REL_ CSM_LE SG_ 2151858176 DrvCycElecEngySt3 1;
BA_REL_ "GenSigSuprvResp" BU_SG_REL_ RadioHead_LE SG_ 2151858176 DrvCycElecEngySt3 1;
BA_REL_ "GenSigSuprvResp" BU_SG_REL_ VCU_LE SG_ 2151858176 DrvCycElecEngySt2 1;
BA_REL_ "GenSigSuprvResp" BU_SG_REL_ CSM_LE SG_ 2151858176 DrvCycElecEngySt2 1;
BA_REL_ "GenSigSuprvResp" BU_SG_REL_ RadioHead_LE SG_ 2151858176 DrvCycElecEngySt2 1;
BA_REL_ "GenSigSuprvResp" BU_SG_REL_ VCU_LE SG_ 2151858176 DrvCycElecEngySt1 1;
BA_REL_ "GenSigSuprvResp" BU_SG_REL_ CSM_LE SG_ 2151858176 DrvCycElecEngySt1 1;
BA_REL_ "GenSigSuprvResp" BU_SG_REL_ RadioHead_LE SG_ 2151858176 DrvCycElecEngySt1 1;
BA_REL_ "GenSigSuprvResp" BU_SG_REL_ VCU_LE SG_ 2151809024 ElecEngyEconAvg 1;
BA_REL_ "GenSigSuprvResp" BU_SG_REL_ IPC_LE SG_ 2151809024 ElecEngyEconAvg 1;
BA_REL_ "GenSigSuprvResp" BU_SG_REL_ VCU_LE SG_ 2151809024 DrvCycElecEngySt5 1;
BA_REL_ "GenSigSuprvResp" BU_SG_REL_ CSM_LE SG_ 2151809024 DrvCycElecEngySt5 1;
BA_REL_ "GenSigSuprvResp" BU_SG_REL_ RadioHead_LE SG_ 2151809024 DrvCycElecEngySt5 1;
BA_REL_ "GenSigSuprvResp" BU_SG_REL_ VCU_LE SG_ 2151809024 DCEEC_EngyPct4 1;
BA_REL_ "GenSigSuprvResp" BU_SG_REL_ CSM_LE SG_ 2151809024 DCEEC_EngyPct4 1;
BA_REL_ "GenSigSuprvResp" BU_SG_REL_ RadioHead_LE SG_ 2151809024 DCEEC_EngyPct4 1;
BA_REL_ "GenSigSuprvResp" BU_SG_REL_ VCU_LE SG_ 2151809024 DCEEC_EngyPct3 1;
BA_REL_ "GenSigSuprvResp" BU_SG_REL_ CSM_LE SG_ 2151809024 DCEEC_EngyPct3 1;
BA_REL_ "GenSigSuprvResp" BU_SG_REL_ RadioHead_LE SG_ 2151809024 DCEEC_EngyPct3 1;
BA_REL_ "GenSigSuprvResp" BU_SG_REL_ VCU_LE SG_ 2151809024 DCEEC_EngyPct2 1;
BA_REL_ "GenSigSuprvResp" BU_SG_REL_ CSM_LE SG_ 2151809024 DCEEC_EngyPct2 1;
BA_REL_ "GenSigSuprvResp" BU_SG_REL_ RadioHead_LE SG_ 2151809024 DCEEC_EngyPct2 1;
BA_REL_ "GenSigSuprvResp" BU_SG_REL_ VCU_LE SG_ 2151809024 DCEEC_EngyPct1 1;
BA_REL_ "GenSigSuprvResp" BU_SG_REL_ CSM_LE SG_ 2151809024 DCEEC_EngyPct1 1;
BA_REL_ "GenSigSuprvResp" BU_SG_REL_ RadioHead_LE SG_ 2151809024 DCEEC_EngyPct1 1;
BA_REL_ "GenSigSuprvResp" BU_SG_REL_ VCU_LE SG_ 2151792640 RCTARIC_Indctr1Act 1;
BA_REL_ "GenSigSuprvResp" BU_SG_REL_ CSM_LE SG_ 2151792640 RCTARIC_Indctr1Act 1;
BA_REL_ "GenSigSuprvResp" BU_SG_REL_ RadioHead_LE SG_ 2151792640 RCTARIC_Indctr1Act 1;
BA_REL_ "GenSigSuprvResp" BU_SG_REL_ VCU_LE SG_ 2151792640 RCTARIC_IndReq 1;
BA_REL_ "GenSigSuprvResp" BU_SG_REL_ CSM_LE SG_ 2151792640 RCTARIC_IndReq 1;
BA_REL_ "GenSigSuprvResp" BU_SG_REL_ RadioHead_LE SG_ 2151792640 RCTARIC_IndReq 1;
BA_REL_ "GenSigSuprvResp" BU_SG_REL_ VCU_LE SG_ 2151776256 RCTALIC_Indctr1Act 1;
BA_REL_ "GenSigSuprvResp" BU_SG_REL_ CSM_LE SG_ 2151776256 RCTALIC_Indctr1Act 1;
BA_REL_ "GenSigSuprvResp" BU_SG_REL_ RadioHead_LE SG_ 2151776256 RCTALIC_Indctr1Act 1;
BA_REL_ "GenSigSuprvResp" BU_SG_REL_ VCU_LE SG_ 2151776256 RCTALIC_IndReq 1;
BA_REL_ "GenSigSuprvResp" BU_SG_REL_ CSM_LE SG_ 2151776256 RCTALIC_IndReq 1;
BA_REL_ "GenSigSuprvResp" BU_SG_REL_ RadioHead_LE SG_ 2151776256 RCTALIC_IndReq 1;
BA_REL_ "GenSigSuprvResp" BU_SG_REL_ VCU_LE SG_ 2155913216 PFAS_SrvPedAlrtIO 1;
BA_REL_ "GenSigSuprvResp" BU_SG_REL_ IPC_LE SG_ 2155913216 PFAS_SrvPedAlrtIO 1;
BA_REL_ "GenSigSuprvResp" BU_SG_REL_ VCU_LE SG_ 2155913216 PFAS_PFASysStat 1;
BA_REL_ "GenSigSuprvResp" BU_SG_REL_ IPC_LE SG_ 2155913216 PFAS_PFASysStat 1;
BA_REL_ "GenSigSuprvResp" BU_SG_REL_ VCU_LE SG_ 2155913216 PFAS_PFASndVolCtrl 1;
BA_REL_ "GenSigSuprvResp" BU_SG_REL_ IPC_LE SG_ 2155913216 PFAS_PFASndVolCtrl 1;
BA_REL_ "GenSigSuprvResp" BU_SG_REL_ VCU_LE SG_ 2155913216 PFAS_PFASndGenEn 1;
BA_REL_ "GenSigSuprvResp" BU_SG_REL_ IPC_LE SG_ 2155913216 PFAS_PFASndGenEn 1;
BA_REL_ "GenSigSuprvResp" BU_SG_REL_ VCU_LE SG_ 2155913216 PFAS_PFARevSnd 1;
BA_REL_ "GenSigSuprvResp" BU_SG_REL_ IPC_LE SG_ 2155913216 PFAS_PFARevSnd 1;
BA_REL_ "GenSigSuprvResp" BU_SG_REL_ VCU_LE SG_ 2155913216 PFAS_PFAFwdSnd 1;
BA_REL_ "GenSigSuprvResp" BU_SG_REL_ IPC_LE SG_ 2155913216 PFAS_PFAFwdSnd 1;
BA_REL_ "GenSigSuprvResp" BU_SG_REL_ VCU_LE SG_ 2155913216 PFAS_PFACrsOvrSpd 1;
BA_REL_ "GenSigSuprvResp" BU_SG_REL_ IPC_LE SG_ 2155913216 PFAS_PFACrsOvrSpd 1;
BA_REL_ "GenSigSuprvResp" BU_SG_REL_ VCU_LE SG_ 2155913216 PedFrndlyAlrtCsSetAvl 1;
BA_REL_ "GenSigSuprvResp" BU_SG_REL_ CSM_LE SG_ 2155913216 PedFrndlyAlrtCsSetAvl 1;
BA_REL_ "GenSigSuprvResp" BU_SG_REL_ RadioHead_LE SG_ 2155913216 PedFrndlyAlrtCsSetAvl 1;
BA_REL_ "GenSigSuprvResp" BU_SG_REL_ VCU_LE SG_ 2155913216 PedFrndlyAlrtCsCrStVal 1;
BA_REL_ "GenSigSuprvResp" BU_SG_REL_ CSM_LE SG_ 2155913216 PedFrndlyAlrtCsCrStVal 1;
BA_REL_ "GenSigSuprvResp" BU_SG_REL_ RadioHead_LE SG_ 2155913216 PedFrndlyAlrtCsCrStVal 1;
BA_REL_ "GenSigSuprvResp" BU_SG_REL_ VCU_LE SG_ 2155913216 DslExhFldRmngDstHRs 1;
BA_REL_ "GenSigSuprvResp" BU_SG_REL_ IPC_LE SG_ 2155913216 DslExhFldRmngDstHRs 1;
BA_REL_ "GenSigSuprvResp" BU_SG_REL_ VCU_LE SG_ 2155913216 DslExhFluidLvlPrcnt 1;
BA_REL_ "GenSigSuprvResp" BU_SG_REL_ IPC_LE SG_ 2155913216 DslExhFluidLvlPrcnt 1;
BA_REL_ "GenSigSuprvResp" BU_SG_REL_ VCU_LE SG_ 2155913216 DslEmnsOBDMrkt 1;
BA_REL_ "GenSigSuprvResp" BU_SG_REL_ IPC_LE SG_ 2155913216 DslEmnsOBDMrkt 1;
BA_REL_ "GenSigSuprvResp" BU_SG_REL_ VCU_LE SG_ 2154790912 AdpHgBmAsSnCsCrStVal 1;
BA_REL_ "GenSigSuprvResp" BU_SG_REL_ CSM_LE SG_ 2154790912 AdpHgBmAsSnCsCrStVal 1;
BA_REL_ "GenSigSuprvResp" BU_SG_REL_ RadioHead_LE SG_ 2154790912 AdpHgBmAsSnCsCrStVal 1;
BA_REL_ "GenSigSuprvResp" BU_SG_REL_ VCU_LE SG_ 2154790912 AdpHgBmAsSnCsStAvl 1;
BA_REL_ "GenSigSuprvResp" BU_SG_REL_ CSM_LE SG_ 2154790912 AdpHgBmAsSnCsStAvl 1;
BA_REL_ "GenSigSuprvResp" BU_SG_REL_ RadioHead_LE SG_ 2154790912 AdpHgBmAsSnCsStAvl 1;
BA_REL_ "GenSigSuprvResp" BU_SG_REL_ VCU_LE SG_ 2154790912 AdpHgBmAsCsCrStVal 1;
BA_REL_ "GenSigSuprvResp" BU_SG_REL_ CSM_LE SG_ 2154790912 AdpHgBmAsCsCrStVal 1;
BA_REL_ "GenSigSuprvResp" BU_SG_REL_ RadioHead_LE SG_ 2154790912 AdpHgBmAsCsCrStVal 1;
BA_REL_ "GenSigSuprvResp" BU_SG_REL_ VCU_LE SG_ 2154790912 AdpHgBmAsCsStAvl 1;
BA_REL_ "GenSigSuprvResp" BU_SG_REL_ CSM_LE SG_ 2154790912 AdpHgBmAsCsStAvl 1;
BA_REL_ "GenSigSuprvResp" BU_SG_REL_ RadioHead_LE SG_ 2154790912 AdpHgBmAsCsStAvl 1;
BA_REL_ "GenSigSuprvResp" BU_SG_REL_ VCU_LE SG_ 2154790912 AutHgBmAsCsCrStVal 1;
BA_REL_ "GenSigSuprvResp" BU_SG_REL_ CSM_LE SG_ 2154790912 AutHgBmAsCsCrStVal 1;
BA_REL_ "GenSigSuprvResp" BU_SG_REL_ RadioHead_LE SG_ 2154790912 AutHgBmAsCsCrStVal 1;
BA_REL_ "GenSigSuprvResp" BU_SG_REL_ VCU_LE SG_ 2154790912 AutHgBmAsSnCsStAvl 1;
BA_REL_ "GenSigSuprvResp" BU_SG_REL_ CSM_LE SG_ 2154790912 AutHgBmAsSnCsStAvl 1;
BA_REL_ "GenSigSuprvResp" BU_SG_REL_ RadioHead_LE SG_ 2154790912 AutHgBmAsSnCsStAvl 1;
BA_REL_ "GenSigSuprvResp" BU_SG_REL_ VCU_LE SG_ 2154790912 AutHgBmAsSnCsCrStVa 1;
BA_REL_ "GenSigSuprvResp" BU_SG_REL_ CSM_LE SG_ 2154790912 AutHgBmAsSnCsCrStVa 1;
BA_REL_ "GenSigSuprvResp" BU_SG_REL_ RadioHead_LE SG_ 2154790912 AutHgBmAsSnCsCrStVa 1;
BA_REL_ "GenSigSuprvResp" BU_SG_REL_ VCU_LE SG_ 2154790912 AutHgBmAsCsStAvl 1;
BA_REL_ "GenSigSuprvResp" BU_SG_REL_ CSM_LE SG_ 2154790912 AutHgBmAsCsStAvl 1;
BA_REL_ "GenSigSuprvResp" BU_SG_REL_ RadioHead_LE SG_ 2154790912 AutHgBmAsCsStAvl 1;
BA_REL_ "GenSigSuprvResp" BU_SG_REL_ VCU_LE SG_ 2154774528 LtRtHnTrGPSCsStAvl 1;
BA_REL_ "GenSigSuprvResp" BU_SG_REL_ CSM_LE SG_ 2154774528 LtRtHnTrGPSCsStAvl 1;
BA_REL_ "GenSigSuprvResp" BU_SG_REL_ RadioHead_LE SG_ 2154774528 LtRtHnTrGPSCsStAvl 1;
BA_REL_ "GenSigSuprvResp" BU_SG_REL_ VCU_LE SG_ 2154774528 LtRtHnTrGPCsCrStVal 1;
BA_REL_ "GenSigSuprvResp" BU_SG_REL_ CSM_LE SG_ 2154774528 LtRtHnTrGPCsCrStVal 1;
BA_REL_ "GenSigSuprvResp" BU_SG_REL_ RadioHead_LE SG_ 2154774528 LtRtHnTrGPCsCrStVal 1;
BA_REL_ "GenSigSuprvResp" BU_SG_REL_ VCU_LE SG_ 2154774528 LtRtHnTrCstStVal 1;
BA_REL_ "GenSigSuprvResp" BU_SG_REL_ VCU_LE SG_ 2154774528 LtRtHnTrCstStVal 1;
BA_REL_ "GenSigSuprvResp" BU_SG_REL_ CSM_LE SG_ 2154774528 LtRtHnTrCstStVal 1;
BA_REL_ "GenSigSuprvResp" BU_SG_REL_ CSM_LE SG_ 2154774528 LtRtHnTrCstStVal 1;
BA_REL_ "GenSigSuprvResp" BU_SG_REL_ RadioHead_LE SG_ 2154774528 LtRtHnTrCstStVal 1;
BA_REL_ "GenSigSuprvResp" BU_SG_REL_ RadioHead_LE SG_ 2154774528 LtRtHnTrCstStVal 1;
BA_REL_ "GenSigSuprvResp" BU_SG_REL_ VCU_LE SG_ 2154774528 LtRtHnTrCstStAvail 1;
BA_REL_ "GenSigSuprvResp" BU_SG_REL_ VCU_LE SG_ 2154774528 LtRtHnTrCstStAvail 1;
BA_REL_ "GenSigSuprvResp" BU_SG_REL_ CSM_LE SG_ 2154774528 LtRtHnTrCstStAvail 1;
BA_REL_ "GenSigSuprvResp" BU_SG_REL_ CSM_LE SG_ 2154774528 LtRtHnTrCstStAvail 1;
BA_REL_ "GenSigSuprvResp" BU_SG_REL_ RadioHead_LE SG_ 2154774528 LtRtHnTrCstStAvail 1;
BA_REL_ "GenSigSuprvResp" BU_SG_REL_ RadioHead_LE SG_ 2154774528 LtRtHnTrCstStAvail 1;
BA_REL_ "GenSigSuprvResp" BU_SG_REL_ VPM_LE SG_ 2151178240 TrlrMirVGlnCustSetReq 1;
BA_REL_ "GenSigSuprvResp" BU_SG_REL_ VPM_LE SG_ 2151178240 TrlrMirVEnCustSetReq 1;
BA_REL_ "GenSigSuprvResp" BU_SG_REL_ VPM_LE SG_ 2151178240 JacknfDetCustSetReq 1;
BA_REL_ "GenSigSuprvResp" BU_SG_REL_ VPM_LE SG_ 2151178240 CrgBdVwLtCustSetReq 1;
BA_REL_ "GenSigSuprvResp" BU_SG_REL_ CSM_LE SG_ 2149728256 PrtyChrgStPnt 1;
BA_REL_ "GenSigSuprvResp" BU_SG_REL_ RadioHead_LE SG_ 2149728256 PrtyChrgStPnt 1;
BA_REL_ "GenSigSuprvResp" BU_SG_REL_ VCU_LE SG_ 2149728256 PrtyChrgStPnt 1;
BA_REL_ "GenSigSuprvResp" BU_SG_REL_ VCU_LE SG_ 2149728256 PrtyChrgAct 1;
BA_REL_ "GenSigSuprvResp" BU_SG_REL_ CSM_LE SG_ 2149728256 PrtyChrgAct 1;
BA_REL_ "GenSigSuprvResp" BU_SG_REL_ RadioHead_LE SG_ 2149728256 PrtyChrgAct 1;
BA_REL_ "GenSigSuprvResp" BU_SG_REL_ CSM_LE SG_ 2149728256 HVChrgPwrLvl 1;
BA_REL_ "GenSigSuprvResp" BU_SG_REL_ RadioHead_LE SG_ 2149728256 HVChrgPwrLvl 1;
BA_REL_ "GenSigSuprvResp" BU_SG_REL_ RadioHead_LE SG_ 2149728256 HVChrgPwrLvl 1;
BA_REL_ "GenSigSuprvResp" BU_SG_REL_ VCU_LE SG_ 2149728256 HVChrgPwrLvl 1;
BA_REL_ "GenSigSuprvResp" BU_SG_REL_ VCU_LE SG_ 2149728256 HVChrgPwrLvl 1;
BA_REL_ "GenSigSuprvResp" BU_SG_REL_ VCU_LE SG_ 2149728256 ChgCdTfAlCzStAvbl 1;
BA_REL_ "GenSigSuprvResp" BU_SG_REL_ VCU_LE SG_ 2149728256 ChgCdTfAlCzStAvbl 1;
BA_REL_ "GenSigSuprvResp" BU_SG_REL_ CSM_LE SG_ 2149728256 ChgCdTfAlCzStAvbl 1;
BA_REL_ "GenSigSuprvResp" BU_SG_REL_ RadioHead_LE SG_ 2149728256 ChgCdTfAlCzStAvbl 1;
BA_REL_ "GenSigSuprvResp" BU_SG_REL_ RadioHead_LE SG_ 2149728256 ChgCdTfAlCzStAvbl 1;
BA_REL_ "GenSigSuprvResp" BU_SG_REL_ VCU_LE SG_ 2149728256 ChgCdTfAlCzCrStVal 1;
BA_REL_ "GenSigSuprvResp" BU_SG_REL_ VCU_LE SG_ 2149728256 ChgCdTfAlCzCrStVal 1;
BA_REL_ "GenSigSuprvResp" BU_SG_REL_ CSM_LE SG_ 2149728256 ChgCdTfAlCzCrStVal 1;
BA_REL_ "GenSigSuprvResp" BU_SG_REL_ RadioHead_LE SG_ 2149728256 ChgCdTfAlCzCrStVal 1;
BA_REL_ "GenSigSuprvResp" BU_SG_REL_ RadioHead_LE SG_ 2149728256 ChgCdTfAlCzCrStVal 1;
BA_REL_ "GenSigSuprvResp" BU_SG_REL_ VCU_LE SG_ 2149728256 ChgPwLsAlCzStAvbl 1;
BA_REL_ "GenSigSuprvResp" BU_SG_REL_ VCU_LE SG_ 2149728256 ChgPwLsAlCzStAvbl 1;
BA_REL_ "GenSigSuprvResp" BU_SG_REL_ CSM_LE SG_ 2149728256 ChgPwLsAlCzStAvbl 1;
BA_REL_ "GenSigSuprvResp" BU_SG_REL_ RadioHead_LE SG_ 2149728256 ChgPwLsAlCzStAvbl 1;
BA_REL_ "GenSigSuprvResp" BU_SG_REL_ RadioHead_LE SG_ 2149728256 ChgPwLsAlCzStAvbl 1;
BA_REL_ "GenSigSuprvResp" BU_SG_REL_ VCU_LE SG_ 2149728256 ChgPwLsAlCzCrStVal 1;
BA_REL_ "GenSigSuprvResp" BU_SG_REL_ VCU_LE SG_ 2149728256 ChgPwLsAlCzCrStVal 1;
BA_REL_ "GenSigSuprvResp" BU_SG_REL_ CSM_LE SG_ 2149728256 ChgPwLsAlCzCrStVal 1;
BA_REL_ "GenSigSuprvResp" BU_SG_REL_ RadioHead_LE SG_ 2149728256 ChgPwLsAlCzCrStVal 1;
BA_REL_ "GenSigSuprvResp" BU_SG_REL_ RadioHead_LE SG_ 2149728256 ChgPwLsAlCzCrStVal 1;
BA_REL_ "GenSigSuprvResp" BU_SG_REL_ VCU_LE SG_ 2149793792 AutoEmrgncyBrkDisbldIO 1;
BA_REL_ "GenSigSuprvResp" BU_SG_REL_ IPC_LE SG_ 2149793792 AutoEmrgncyBrkDisbldIO 1;
BA_REL_ "GenSigSuprvResp" BU_SG_REL_ VCU_LE SG_ 2149875712 DCCnvStblznErrIO 1;
BA_REL_ "GenSigSuprvResp" BU_SG_REL_ IPC_LE SG_ 2149875712 DCCnvStblznErrIO 1;
BA_REL_ "GenSigSuprvResp" BU_SG_REL_ VCU_LE SG_ 2149875712 BattStOfChrgLowIO 1;
BA_REL_ "GenSigSuprvResp" BU_SG_REL_ IPC_LE SG_ 2149875712 BattStOfChrgLowIO 1;
BA_REL_ "GenSigSuprvResp" BU_SG_REL_ TCP_LE SG_ 2149875712 BatSvrMdSevLvl 1;
BA_REL_ "GenSigSuprvResp" BU_SG_REL_ ONSTAR_LE SG_ 2149875712 BatSvrMdSevLvl 1;
BA_REL_ "GenSigSuprvResp" BU_SG_REL_ VCU_LE SG_ 2149875712 BatSvrMdSevLvl 1;
BA_REL_ "GenSigSuprvResp" BU_SG_REL_ RadioHead_LE SG_ 2149875712 BatSvrMdSevLvl 1;
BA_REL_ "GenSigSuprvResp" BU_SG_REL_ TCP_LE SG_ 2149875712 PwrMdOffBattSOC 1;
BA_REL_ "GenSigSuprvResp" BU_SG_REL_ ONSTAR_LE SG_ 2149875712 PwrMdOffBattSOC 1;
BA_REL_ "GenSigSuprvResp" BU_SG_REL_ TCP_LE SG_ 2149875712 EnrgMgtLdShdRq 1;
BA_REL_ "GenSigSuprvResp" BU_SG_REL_ ONSTAR_LE SG_ 2149875712 EnrgMgtLdShdRq 1;
BA_REL_ "GenSigVBitResp" BU_SG_REL_ VPM_LE SG_ 2149875712 BatVlt 1;
BA_REL_ "GenSigVBitRespComment" BU_SG_REL_ VPM_LE SG_ 2149875712 BatVlt "BatVltV";
BA_REL_ "GenSigSuprvResp" BU_SG_REL_ VPM_LE SG_ 2149875712 BatVlt 1;
BA_REL_ "GenSigSuprvResp" BU_SG_REL_ V2V_LE SG_ 2149875712 BatVlt 1;
BA_REL_ "GenSigSuprvResp" BU_SG_REL_ RadioHead_LE SG_ 2149875712 BatVlt 1;
BA_REL_ "GenSigSuprvResp" BU_SG_REL_ RadioHead_LE SG_ 2149875712 BatVlt 1;
BA_REL_ "GenSigSuprvResp" BU_SG_REL_ VCU_LE SG_ 2149875712 BatVlt 1;
BA_REL_ "GenSigSuprvResp" BU_SG_REL_ VCU_LE SG_ 2149875712 BatVlt 1;
BA_REL_ "GenSigSuprvResp" BU_SG_REL_ VCU_LE SG_ 2149875712 BatVlt 1;
BA_REL_ "GenSigSuprvResp" BU_SG_REL_ VCU_LE SG_ 2149875712 BatVlt 1;
BA_REL_ "GenSigSuprvResp" BU_SG_REL_ IPC_LE SG_ 2149875712 BatVlt 1;
BA_REL_ "GenSigSuprvResp" BU_SG_REL_ IPC_LE SG_ 2149875712 BatVlt 1;
BA_REL_ "GenSigSuprvResp" BU_SG_REL_ VCU_LE SG_ 2151079936 PDIMPrsnt 1;
BA_REL_ "GenSigSuprvResp" BU_SG_REL_ RadioHead_LE SG_ 2151079936 PDIMPrsnt 1;
BA_REL_ "GenSigSuprvResp" BU_SG_REL_ V2V_LE SG_ 2153824256 TeenDrvAct 1;
BA_REL_ "GenSigSuprvResp" BU_SG_REL_ VCU_LE SG_ 2153824256 TeenDrvAct 1;
BA_REL_ "GenSigSuprvResp" BU_SG_REL_ IPC_LE SG_ 2153824256 TeenDrvAct 1;
BA_REL_ "GenSigSuprvResp" BU_SG_REL_ VCU_LE SG_ 2153824256 TnDrvGapAdjUnbIO 1;
BA_REL_ "GenSigSuprvResp" BU_SG_REL_ IPC_LE SG_ 2153824256 TnDrvGapAdjUnbIO 1;
BA_REL_ "GenSigSuprvResp" BU_SG_REL_ VCU_LE SG_ 2153824256 TnDrvOvrSpdIO 1;
BA_REL_ "GenSigSuprvResp" BU_SG_REL_ IPC_LE SG_ 2153824256 TnDrvOvrSpdIO 1;
BA_REL_ "GenSigSuprvResp" BU_SG_REL_ VCU_LE SG_ 2153824256 TDOWCCSV_CrStVl 1;
BA_REL_ "GenSigSuprvResp" BU_SG_REL_ IPC_LE SG_ 2153824256 TDOWCCSV_CrStVl 1;
BA_REL_ "GenSigSuprvResp" BU_SG_REL_ VCU_LE SG_ 2153824256 TDOWCCSV_CrStat 1;
BA_REL_ "GenSigSuprvResp" BU_SG_REL_ IPC_LE SG_ 2153824256 TDOWCCSV_CrStat 1;
BA_REL_ "GenSigSuprvResp" BU_SG_REL_ VCU_LE SG_ 2153824256 TDSLCCSV_SpLmtStat 1;
BA_REL_ "GenSigSuprvResp" BU_SG_REL_ IPC_LE SG_ 2153824256 TDSLCCSV_SpLmtStat 1;
BA_REL_ "GenSigSuprvResp" BU_SG_REL_ VCU_LE SG_ 2153824256 TDSLCCSV_SpLmDisVl 1;
BA_REL_ "GenSigSuprvResp" BU_SG_REL_ IPC_LE SG_ 2153824256 TDSLCCSV_SpLmDisVl 1;
BA_REL_ "GenSigSuprvResp" BU_SG_REL_ VPM_LE SG_ 2162982912 VehIdNmDig10_17 1;
BA_REL_ "GenSigSuprvResp" BU_SG_REL_ VPM_LE SG_ 2162966528 VehIdNmDig2_9 1;
VAL_ 2150252544 ECHG_YAxisMaxVal 0 "6" 1 "12" 2 "16" 3 "20" 4 "32" 5 "40" 6 "48" 7 "60" ;
VAL_ 2150252544 ECHG_XAxisTkMrkIntvl 0 "0.5" 1 "1" 2 "5" 3 "10" 4 "20" 5 "50" 6 "80" 7 "100" ;
VAL_ 2150252544 ECHG_MeasUnit 0 "km/kWh" 1 "mi/kWh" 2 "kWh/100km" 3 "km/L" 4 "mi/gal" 5 "L/100km" 6 "mi/kg" 7 "kg/100km" ;
VAL_ 2150383616 LssOfPrplsnIO 1 "true" 0 "false" ;
VAL_ 2150383616 EngMntnceMdAct 1 "true" 0 "false" ;
VAL_ 2150383616 MntnceMdDsplyRq 15 "Unused and Reserved" 14 "Continue FM" 13 "Force FM" 12 "FM 1 Day Warning" 11 "FM 2 Day Warning" 10 "FM 3 Day Warning" 9 "FM 4 Day Warning" 8 "FM 5 Day Warning" 7 "Continue EM" 6 "Force EM" 5 "EM 1 Day Warning" 4 "EM 2 Day Warning" 3 "EM 3 Day Warning" 2 "EM 4 Day Warning" 1 "EM 5 Day Warning" 0 "No Request" ;
VAL_ 2150375424 HVBChrgLmtBtnDspReq 2 "Do Not Display Charge Limit Button" 1 "Display Charge Limit Button" 0 "No Action" ;
VAL_ 2150375424 HVBHmChrgTmDspReq 4 "Display Master Setting" 3 "Display Both Cord and Station" 2 "Display Charge Station Charge Value" 1 "Display Portable Cord Charge Value" 0 "No Action" ;
VAL_ 2150375424 HVBChrgTmDspReq 3 "Display Both Cord and Station" 2 "Display Charge Station Charge Value" 1 "Display Portable Cord Charge Value" 0 "No Action" ;
VAL_ 2150375424 HVBChrgOvrdBtnDspReq 2 "Do Not Display Charge Override Button" 1 "Display Charge Override Button" 0 "No Action" ;
VAL_ 2150375424 LBCCsStReq 2 "On" 1 "Off" 0 "No Action" ;
VAL_ 2150375424 LBCPosMdfcReq 4 "Store Position 4" 3 "Store Position 3" 2 "Store Position 2" 1 "Store Position 1" 0 "No Action" ;
VAL_ 2150375424 LBCCDRR_ClrStrdPosReq 2 "Confirmation to Clear Position" 1 "Request to Clear Position" 0 "No Action" ;
VAL_ 2150375424 LBCCDRR_PosNum 4 "Position Number 4" 3 "Position Number 3" 2 "Position Number 2" 1 "Position Number 1" 0 "No Action" ;
VAL_ 2150375424 USBProgInPrgrs 1 "true" 0 "false" ;
VAL_ 2150375424 EngyCnsHistGrphRstRq 1 "true" 0 "false" ;
VAL_ 2150375424 DsplTrnsShftLvrLckRqd 1 "true" 0 "false" ;
VAL_ 2150375424 EngAstHtPlgInCstStRq 0 "No Action" 1 "Off" 2 "On" ;
VAL_ 2150375424 EngAstHtCstStRq 3 "Off" 0 "No Action" 1 "On" 2 "Deferred" ;
VAL_ 2150375424 MntnceMdStEngRq 1 "true" 0 "false" ;
VAL_ 2150113280 HVChrgInhbRsn 3 "See Charging Station" 2 "Charge Cord Lock Not Engaged" 1 "Charge Cord Not Fully Inserted" 0 "No Action" ;
VAL_ 2150113280 EngyStgSysActCoolEnb 1 "true" 0 "false" ;
VAL_ 2151792640 RCTARIC_Indctr1Act 1 "true" 0 "false" ;
VAL_ 2151792640 RCTARIC_IndReq 0 "Off" 1 "Continuous Indication" 2 "Flashing Indication" ;
VAL_ 2151776256 RCTALIC_Indctr1Act 1 "true" 0 "false" ;
VAL_ 2151776256 RCTALIC_IndReq 0 "Off" 1 "Continuous Indication" 2 "Flashing Indication" ;
VAL_ 2151899136 PTOAccelUpnBrkRelIO 1 "true" 0 "false" ;
VAL_ 2151899136 PTOEngUpnBrkRelIO 1 "true" 0 "false" ;
VAL_ 2151899136 PTOManTransInGrIO 1 "true" 0 "false" ;
VAL_ 2151899136 PTOServIndOn 1 "true" 0 "false" ;
VAL_ 2151899136 PTOVDM 0 "Don't Use Data" 1 "Use Data" ;
VAL_ 2151899136 PTOVDA 1 "VirtualDeviceAvailable" 0 "VirtualDeviceUnavailable" ;
VAL_ 2151899136 PTOTransInGearIO 1 "true" 0 "false" ;
VAL_ 2151899136 PTOTpStpSpdCsStAvl 1 "true" 0 "false" ;
VAL_ 2151899136 PTOTpStSpdCsCrStVal 0 "No Action" 1 "5 rpm" 2 "10 rpm" 3 "25 rpm" 4 "50 rpm" 5 "100 rpm" 6 "250 rpm" 7 "500 rpm" ;
VAL_ 2151899136 PTOStdbySpdCsStAvl 1 "true" 0 "false" ;
VAL_ 2151899136 PTOStdbSpdCsCrStVal 0 "No Action" 1 "900 rpm" 2 "1000 rpm" 3 "1100 rpm" 4 "1200 rpm" 5 "1300 rpm" 6 "1400 rpm" 7 "1500 rpm" ;
VAL_ 2151899136 PTOSetPrkBrkIO 1 "true" 0 "false" ;
VAL_ 2151899136 PTOSet2SpdCsStAvl 1 "true" 0 "false" ;
VAL_ 2151899136 PTOSet2SpdCsCrStVal 0 "No action" 1 "Speed 1" 2 "Speed 2" 3 "Speed 3" 4 "Speed 4" 5 "Speed 5" 6 "Speed 6" 7 "Speed 7" 8 "Speed 8" 9 "Speed 9" 10 "Speed 10" 11 "Speed 11" 12 "Speed 12" 13 "Speed 13" 14 "Speed 14" 15 "Speed 15" ;
VAL_ 2151899136 PTOSet1SpdCsStAvl 1 "true" 0 "false" ;
VAL_ 2151899136 PTOSet1SpdCsCrStVal 0 "No Action" 1 "1100 rpm" 2 "1200 rpm" 3 "1300 rpm" 4 "1400 rpm" 5 "1500 rpm" 6 "1600 rpm" 7 "1700 rpm" 8 "1800 rpm" 9 "1900 rpm" 10 "2000 rpm" 11 "2100 rpm" 12 "2200 rpm" 13 "2300 rpm" 14 "2400 rpm" 15 "2500 rpm" ;
VAL_ 2151899136 PTORelCltPedIO 1 "true" 0 "false" ;
VAL_ 2151899136 PTORelBrkPedIO 1 "true" 0 "false" ;
VAL_ 2151899136 PTORelAccPedIO 1 "true" 0 "false" ;
VAL_ 2151899136 PTORedEngSpdIO 1 "true" 0 "false" ;
VAL_ 2151899136 PTOPrsRelCltPedIO 1 "true" 0 "false" ;
VAL_ 2151899136 PTOPrsRelBrkPedIO 1 "true" 0 "false" ;
VAL_ 2151899136 PTOEngRnTmrCsStAvl 1 "true" 0 "false" ;
VAL_ 2151899136 PTOEnRnTmCsCrStVal 0 "No Action" 1 "10 min" 2 "30 min" 3 "90 min" 4 "120 min" 5 "150 min" 6 "180 min" 7 "210 min" 8 "240 min" 9 "270 min" 10 "300 min" 11 "330 min" 12 "360 min" 13 "390 min" 14 "420 min" 15 "450 min" ;
VAL_ 2151899136 PTOEngmntStatInd 0 "No Indication" 1 "Continuous Indication" 2 "Slow Flashing Indication" 3 "Fast Flashing Indication" ;
VAL_ 2151899136 PTODisengCrsCntlIO 1 "true" 0 "false" ;
VAL_ 2151882752 PTOTpStpSpdCsStReq 0 "No Action" 1 "5 rpm" 2 "10 rpm" 3 "25 rpm" 4 "50 rpm" 5 "100 rpm" 6 "250 rpm" 7 "500 rpm" ;
VAL_ 2151882752 PTOStdbySpdCsStReq 0 "No Action" 1 "900 rpm" 2 "1000 rpm" 3 "1100 rpm" 4 "1200 rpm" 5 "1300 rpm" 6 "1400 rpm" 7 "1500 rpm" ;
VAL_ 2151882752 PTOEngRnTmrCsStRq 0 "No Action" 1 "10 min" 2 "30 min" 3 "90 min" 4 "120 min" 5 "150 min" 6 "180 min" 7 "210 min" 8 "240 min" 9 "270 min" 10 "300 min" 11 "330 min" 12 "360 min" 13 "390 min" 14 "420 min" 15 "450 min" ;
VAL_ 2151882752 PTOSet2SpdCsStReq 0 "No Action" 1 "Speed 1" 2 "Speed 2" 3 "Speed 3" 4 "Speed 4" 5 "Speed 5" 6 "Speed 6" 7 "Speed 7" 8 "Speed 8" 9 "Speed 9" 10 "Speed 10" 11 "Speed 11" 12 "Speed 12" 13 "Speed 13" 14 "Speed 14" 15 "Speed 15" ;
VAL_ 2151882752 PTOSet1SpdCsStReq 0 "No Action" 1 "1100 rpm" 2 "1200 rpm" 3 "1300 rpm" 4 "1400 rpm" 5 "1500 rpm" 6 "1600 rpm" 7 "1700 rpm" 8 "1800 rpm" 9 "1900 rpm" 10 "2000 rpm" 11 "2100 rpm" 12 "2200 rpm" 13 "2300 rpm" 14 "2400 rpm" 15 "2500 rpm" ;
VAL_ 2155913216 PFAS_SrvPedAlrtIO 1 "true" 0 "false" ;
VAL_ 2155913216 PFAS_PFASysStat 0 "Disable" 1 "Active" 2 "Fault" 3 "Unused and Reserved" ;
VAL_ 2155913216 PFAS_PFASndGenEn 1 "true" 0 "false" ;
VAL_ 2155913216 PFAS_PFARevSnd 0 "No Action" 1 "Sound #1" 2 "Sound #2" 3 "Sound #3" ;
VAL_ 2155913216 PFAS_PFAFwdSnd 0 "No Action" 1 "Sound #1" 2 "Sound #2" 3 "Sound #3" ;
VAL_ 2155913216 PedFrndlyAlrtCsSetAvl 1 "true" 0 "false" ;
VAL_ 2155913216 PedFrndlyAlrtCsCrStVal 0 "No Value" 1 "Off" 2 "On" ;
VAL_ 2155913216 DslExhFluidLvlPrcntV 1 "Invalid" 0 "Valid" ;
VAL_ 2155913216 DslEmnsOBDMrkt 0 "North America" 1 "Europe" ;
VAL_ 2155913216 DslExhFldRmngDstHRsV 1 "Invalid" 0 "Valid" ;
VAL_ 2154790912 AdpHgBmAsSnCsCrStVal 0 "No Value" 1 "Off" 2 "On Normal Sensitivity" 3 "On Reduced Sensitivity" 4 "Reserved1" 5 "Reserved2" 6 "Reserved3" 7 "Reserved4" ;
VAL_ 2154790912 AdpHgBmAsSnCsStAvl 1 "true" 0 "false" ;
VAL_ 2154790912 AdpHgBmAsCsCrStVal 0 "No Value" 1 "Off" 2 "On" 3 "Reserved1" 4 "Reserved2" 5 "Reserved3" 6 "Reserved4" 7 "Reserved5" ;
VAL_ 2154790912 AdpHgBmAsCsStAvl 1 "true" 0 "false" ;
VAL_ 2154790912 AutHgBmAsCsCrStVal 0 "No Value" 1 "Off" 2 "On" 3 "Reserved1" 4 "Reserved2" 5 "Reserved3" 6 "Reserved4" 7 "Reserved5" ;
VAL_ 2154790912 AutHgBmAsSnCsStAvl 1 "true" 0 "false" ;
VAL_ 2154790912 AutHgBmAsSnCsCrStVa 0 "No Value" 1 "Off" 2 "On Normal Sensitivity" 3 "On Reduced Sensitivity" 4 "Reserved1" 5 "Reserved2" 6 "Reserved3" 7 "Reserved4" ;
VAL_ 2154790912 AutHgBmAsCsStAvl 1 "true" 0 "false" ;
VAL_ 2154774528 LtRtHnTrGPSCsStAvl 1 "true" 0 "false" ;
VAL_ 2154774528 LtRtHnTrGPCsCrStVal 0 "No Value" 1 "Left Hand Traffic" 2 "Right Hand Traffic" 3 "Automatic" 4 "Reserved1" 5 "Reserved2" 6 "Reserved3" 7 "Reserved4" ;
VAL_ 2154774528 LtRtHnTrCstStVal 0 "No Value" 1 "Left Hand Traffic" 2 "Right Hand Traffic" ;
VAL_ 2154774528 LtRtHnTrCstStAvail 0 "Not Available" 1 "Present" ;
VAL_ 2151178240 TrlrMirVGlnCustSetReq 3 "Unused and Reserved" 2 "On" 1 "Off" 0 "No Action" ;
VAL_ 2151178240 TrlrMirVEnCustSetReq 3 "Unused and Reserved" 2 "On" 1 "Off" 0 "No Action" ;
VAL_ 2151178240 JacknfDetCustSetReq 3 "Unused and Reserved" 2 "On" 1 "Off" 0 "No Action" ;
VAL_ 2151178240 CrgBdVwLtCustSetReq 3 "Unused and Reserved" 2 "On" 1 "Off" 0 "No Action" ;
VAL_ 2151178240 AFLGPSCstStReq 0 "No Action" 1 "Corner And Curve Lighting Only" 2 "Intelligent Light Distribution" 3 "GPS Assistance" 4 "Reserved1" 5 "Reserved2" 6 "Reserved3" 7 "Off" ;
VAL_ 2151178240 AFLCstStReq 0 "No Action" 1 "Corner And Curve Lighting Only" 2 "Intelligent Light Distribution" 3 "Reserved1" 4 "Reserved2" 5 "Reserved3" 6 "Reserved4" 7 "Off" ;
VAL_ 2151178240 LtRtHnTrCstStReq 0 "No Action" 1 "Left Hand Traffic" 2 "Right Hand Traffic" ;
VAL_ 2151178240 AdpHgBmAsSnCsStRq 0 "No Action" 1 "Off" 2 "Normal Sensitivity" 3 "Reduced Sensitivity" 4 "Reserved1" 5 "Reserved2" 6 "Reserved3" 7 "Reserved4" ;
VAL_ 2151178240 AdpHgBmAstCstStRq 0 "No Action" 1 "Off" 2 "On" 3 "Reserved1" 4 "Reserved2" 5 "Reserved3" 6 "Reserved4" 7 "Reserved5" ;
VAL_ 2151178240 LtRtHnTrGPSCstStRq 0 "No Action" 1 "Left Hand Traffic" 2 "Right Hand Traffic" 3 "Automatic" 4 "Reserved1" 5 "Reserved2" 6 "Reserved3" 7 "Reserved4" ;
VAL_ 2151178240 AutHgBmAsSnCsStRq 0 "No Action" 1 "Off" 2 "On Normal Sensitivity" 3 "On Reduced Sensitivity" 4 "Reserved1" 5 "Reserved2" 6 "Reserved3" 7 "Reserved4" ;
VAL_ 2151178240 AutHgBmAstCstStRq 0 "No Action" 1 "Off" 2 "On" 3 "Reserved1" 4 "Reserved2" 5 "Reserved3" 6 "Reserved4" 7 "Reserved5" ;
VAL_ 2149728256 PrtyChrgActIO 1 "true" 0 "false" ;
VAL_ 2149728256 PrtyChrgAct 1 "true" 0 "false" ;
VAL_ 2149728256 EngAstHtPlgInCsStAvl 1 "true" 0 "false" ;
VAL_ 2149728256 EngAstHtPlgInCsCrStVl 0 "No Action" 1 "Off" 2 "On" ;
VAL_ 2149728256 EngAstHtCsStAvl 1 "true" 0 "false" ;
VAL_ 2149728256 EngAstHtCsCrStVal 3 "Off" 0 "No Action" 1 "On" 2 "Deferred" ;
VAL_ 2149728256 HghVltgPropState 0 "Generator Available" 1 "Generator Unavailable and Electric Propulsion OK" 2 "Generator Unavailable and Electric Propulsion Low" 3 "Generator Unavailable and No Electric Propulsion" ;
VAL_ 2149728256 HVChrgPwrLvl 0 "Unavailable" 1 "AC Level1" 2 "AC Level2" 3 "DC" ;
VAL_ 2149728256 ChrgPrtDrStat 0 "Inactive" 1 "Open Park" 2 "Open Moving" 3 "Fault" ;
VAL_ 2149728256 ChgCdTfAlCzStAvbl 1 "true" 0 "false" ;
VAL_ 2149728256 ChgCdTfAlCzCrStVal 0 "No Action" 1 "Off" 2 "On" 3 "Reserved 1" 4 "Reserved 2" 5 "Reserved 3" 6 "Reserved 4" 7 "Reserved 5" ;
VAL_ 2149728256 ChrgSysTrnsShftLckRq 1 "true" 0 "false" ;
VAL_ 2149728256 ChgPwLsAlCzStAvbl 1 "true" 0 "false" ;
VAL_ 2149728256 ChgPwLsAlCzCrStVal 0 "No Action" 1 "Off" 2 "On" 3 "Reserved 1" 4 "Reserved 2" 5 "Reserved 3" 6 "Reserved 4" 7 "Reserved 5" ;
VAL_ 2149728256 ChgSysAudInCsStAvl 1 "true" 0 "false" ;
VAL_ 2149728256 ChgSyAudInCsCrStVa 0 "No Action" 1 "Off" 2 "On" ;
VAL_ 2156265472 OffBrdHVCVehCsChRq 1 "true" 0 "false" ;
VAL_ 2156265472 PrtyChrgRq 0 "No Action" 1 "False" 2 "True" ;
VAL_ 2156265472 HVBTBRCSR_RtChSlStReq 0 "No Action" 1 "Charge Start" 2 "Charge End" 3 "Charge Start Invalid" 4 "Charge End Invalid" ;
VAL_ 2156265472 HVBTBRCSR_RtChSlRtStReq 0 "No Action" 1 "Low Rate" 2 "Medium Rate" 3 "High Rate" 4 "Reserved 1" 5 "Invalid Rate" ;
VAL_ 2156265472 HVBTBRCSR_RtChSsnStReq 3 "Yearly" 0 "No Action" 1 "Summer" 2 "Winter" ;
VAL_ 2156265472 HVBTBRCSR_RtChDStReq 0 "No Action" 1 "Sunday" 2 "Monday" 3 "Tuesday" 4 "Wednsday" 5 "Thursday" 6 "Friday" 7 "Saturday" 8 "All Days Same" 9 "Mon - Fri Same" 10 "Sat & Sun Same" ;
VAL_ 2156265472 HVBTBDCSRQ_DlChSlStReq 0 "No Action" 1 "Departure Time 1" 2 "Reserved" 3 "Departure Time 1 Invalid" 4 "Reserved" 5 "Departure Time 2" 6 "Reserved" 7 "Departure Time 2 Invalid" 8 "Reserved" ;
VAL_ 2156265472 HVBTBDCSRQ_DlChSsnStReq 3 "Yearly" 0 "No Action" 1 "Summer" 2 "Winter" ;
VAL_ 2156265472 HVBTBDCSRQ_DlChDStReq 0 "No Action" 1 "Sunday" 2 "Monday" 3 "Tuesday" 4 "Wednsday" 5 "Thursday" 6 "Friday" 7 "Saturday" 8 "All Days Same" 9 "Mon - Fri Same" 10 "Sat & Sun Same" ;
VAL_ 2156265472 ChgPwLsAlCzStRq 0 "No Action" 1 "Off" 2 "On" 3 "Reserved 1" 4 "Reserved 2" 5 "Reserved 3" 6 "Reserved 4" 7 "Reserved 5" ;
VAL_ 2156265472 ChgCdTfAlCzStRq 0 "No Action" 1 "Off" 2 "On" 3 "Reserved 1" 4 "Reserved 2" 5 "Reserved 3" 6 "Reserved 4" 7 "Reserved 5" ;
VAL_ 2156265472 ChgSysAudInCsStReq 0 "No Action" 1 "Off" 2 "On" ;
VAL_ 2156265472 EngyUsgScrnMeasUtStat 15 "Unused and Reserved 9" 14 "Unused and Reserved 8" 13 "Unused and Reserved 7" 12 "Unused and Reserved 6" 11 "Unused and Reserved 5" 10 "Unused and Reserved 4" 9 "Unused and Reserved 3" 8 "Unused and Reserved 2" 7 "Unused and Reserved 1" 6 "km/L e Combined" 5 "km/L" 4 "L/100km e Combined" 3 "L/100km" 2 "MPGe Combined" 1 "MPG" 0 "No Action" ;
VAL_ 2150563840 PsStStatDispAct 1 "true" 0 "false" ;
VAL_ 2150563840 DrStStatDispAct 1 "true" 0 "false" ;
VAL_ 2150563840 RadAudQueStat 0 "Audio Queue NOT Available" 1 "Audio Queue Available" 2 "Welcome Active" 3 "CRANK Active" 4 "RUN Active" 5 "Good Bye Active" 6 "Reserved" 7 "Green Queue Active" ;
VAL_ 2150563840 RadAnmtStat 0 "Animation Not Available" 1 "Animation Available" 2 "Welcome Active" 3 "CRANK Active" 4 "RUN Active" 5 "Good Bye Active" ;
VAL_ 2149793792 AutoEmrgncyBrkDisbldIO 1 "true" 0 "false" ;
VAL_ 2149793792 VADIR_IndLvl 0 "No indication" 1 "Indication level 1" 2 "Indication Level 2" 3 "Indication Level 3" 4 "Indication Level 4" 5 "Indication Level 5" 6 "Indication Level 6" 7 "Indication Level 7" 8 "Indication Level 8" ;
VAL_ 2149793792 FCACustStngAvlbl 1 "true" 0 "false" ;
VAL_ 2149793792 FwdClnAlrtCustCrntSetngVal 0 "No Action" 1 "Off" 2 "On" ;
VAL_ 2150891520 RrStRmndrCstSetReq 2 "On" 1 "Off" 0 "No Action" ;
VAL_ 2150891520 DgtlMapCndlSpdLmt 31 "Not Available" 30 "Unlimited" 29 "160 kmh_mph" 28 "150 kmh_mph" 27 "140 kmh_mph" 26 "130 kmh_mph" 25 "120 kmh_mph" 24 "115 kmh_mph" 23 "110 kmh_mph" 22 "105 kmh_mph" 21 "100 kmh_mph" 20 "95 kmh_mph" 19 "90 kmh_mph" 18 "85 kmh_mph" 17 "80 kmh_mph" 16 "75 kmh_mph" 15 "70 kmh_mph" 14 "65 kmh_mph" 13 "60 kmh_mph" 12 "55 kmh_mph" 11 "50 kmh_mph" 10 "45 kmh_mph" 9 "40 kmh_mph" 8 "35 kmh_mph" 7 "30 kmh_mph" 6 "25 kmh_mph" 5 "20 kmh_mph" 4 "15 kmh_mph" 3 "10 kmh_mph" 2 "7 kmh_mph" 1 "Less Than Or Equal To 5 km/h [mph]" 0 "Unknown" ;
VAL_ 2150891520 DgtlMapPsgRstrctn 7 "Unknown Condition" 6 "Conditional When Snow" 5 "Conditional When Wet" 4 "Condtnl Tractors Allowed  Overtake" 3 "Condtnl Passenger Car With Trailer" 2 "LED Signs" 1 "General No Overtake" 0 "No Passing Restrictions" ;
VAL_ 2150891520 DgtlMapCndlSpdLmtTyp 5 "Condtnl Speed Limit Only By Rain" 4 "Condtnl Speed Limit By Time Of Day" 3 "Conditional Speed Limit Only By Day" 2 "Condtnl Speed Limit Only By Night" 1 "Conditional Speed Limit Only By Fog" 0 "Condtnl Speed Limit Lane Dependent" 7 "Unknown Conditional Speed Limit" 6 "Condtnl Speed Limit Only By Snow" ;
VAL_ 2150891520 DgtlMapEffSpdLmt 0 "Unknown" 1 "<= 5 km/h [mph]" 2 "7 km/h [mph]" 3 "10 km/h [mph]" 4 "15 km/h [mph]" 5 "20 km/h [mph]" 6 "25 km/h [mph]" 7 "30 km/h [mph]" 8 "35 km/h [mph]" 9 "40 km/h [mph]" 10 "45 km/h [mph]" 11 "50 km/h [mph]" 12 "55 km/h [mph]" 13 "60 km/h [mph]" 14 "65 km/h [mph]" 15 "70 km/h [mph]" 16 "75 km/h [mph]" 17 "80 km/h [mph]" 18 "85 km/h [mph]" 19 "90 km/h [mph]" 20 "95 km/h [mph]" 21 "100 km/h [mph]" 22 "105 km/h [mph]" 23 "110 km/h [mph]" 24 "115 km/h [mph]" 25 "120 km/h [mph]" 26 "130 km/h [mph]" 27 "140 km/h [mph]" 28 "150 km/h [mph]" 29 "160 km/h [mph]" 30 "Unlimited" 31 "Not Available" ;
VAL_ 2150891520 DgtlMapEffSpdLmtTyp 0 "Implicit" 1 "Explicit on Traffic Sign" 2 "Explicit Only by Night" 3 "Explicit Only by Day" 4 "Explicit Time of Day" 5 "Explicit Only by Rain" 6 "Explicit Only by Snow" 7 "Unknown" ;
VAL_ 2150891520 DgtlMapSpdCat 0 ">130 km/h" 1 "101-130 km/h" 2 "91-100 km/h" 3 "71-90  km/h" 4 "51-70 km/h" 5 "31-50 km/h" 6 "11-30 km/h" 7 "<11 km/h" ;
VAL_ 2150891520 DgtlMapVerQtr 0 "Quarter 1" 1 "Quarter 2" 2 "Quarter 3" 3 "Quarter 4" ;
VAL_ 2150891520 DgtlMapVerYr 0 "2000" 1 "2001" 2 "2002" 3 "2003" 4 "2004" 5 "2005" 6 "2006" 7 "2007" 8 "2008" 9 "2009" 10 "2010" 11 "2011" 12 "2012" 13 "2013" 14 "2014" 15 "2015" 16 "2016" 17 "2017" 18 "2018" 19 "2019" 20 "2020" 21 "2021" 22 "2022" 23 "2023" 24 "2024" 25 "2025" 26 "2026" 27 "2027" 28 "2028" 29 "2029" 30 "2030" 31 "2031" 32 "2032" 33 "2033" 34 "2034" 35 "2035" 36 "2036" 37 "2037" 38 "2038" 39 "2039" 40 "2040" 41 "2041" 42 "2042" 43 "2043" 44 "2044" 45 "2045" 46 "2046" 47 "2047" 48 "2048" 49 "2049" 50 "2050" 51 "2051" 52 "2052" 53 "2053" 54 "2054" 55 "2055" 56 "2056" 57 "2057" 58 "2058" 59 "2059" 60 "2060" 61 "2061" 62 "2062" 63 "N/A" ;
VAL_ 2150891520 DgtlMapDrvngSd 0 "Driving Side Left" 1 "Driving Side Right" ;
VAL_ 2150891520 FwdClnAlrtCustStngReq 0 "No Action" 1 "Off" 2 "On" ;
VAL_ 2150891520 GNCustStngReq 0 "No Action" 1 "Off" 2 "On" ;
VAL_ 2155569152 SmPhRmFunCstStReq 7 "Unused and Reserved 5" 6 "Unused and Reserved 4" 5 "Unused and Reserved 3" 4 "Unused and Reserved 2" 3 "Unused and Reserved 1" 2 "On" 1 "Off" 0 "No Action" ;
VAL_ 2155569152 HLOCCstSetReq 3 "On Open Only" 2 "On" 1 "Off" 0 "No Action" ;
VAL_ 2155569152 IntDimSeldClrTypStReq 31 "Color Type 30" 30 "Color Type 29" 29 "Color Type 28" 28 "Color Type 27" 27 "Color Type 26" 26 "Color Type 25" 25 "Color Type 24" 24 "Color Type 23" 23 "Color Type 22" 22 "Color Type 21" 21 "Color Type 20" 20 "Color Type 19" 19 "Color Type 18" 18 "Color Type 17" 17 "Color Type 16" 16 "Color Type 15" 15 "Color Type 14" 14 "Color Type 13" 13 "Color Type 12" 12 "Color Type 11" 11 "Color Type 10" 10 "Color Type 9" 9 "Color Type 8" 8 "Color Type 7" 7 "Color Type 6" 6 "Color Type 5" 5 "Color Type 4" 4 "Color Type 3" 3 "Color Type 2" 2 "Color Type 1" 1 "Off" 0 "No Action" ;
VAL_ 2155569152 IntDimSeldAnmTypStReq 15 "Animation Type 14" 14 "Animation Type 13" 13 "Animation Type 12" 12 "Animation Type 11" 11 "Animation Type 10" 10 "Animation Type 9" 9 "Animation Type 8" 8 "Animation Type 7" 7 "Animation Type 6" 6 "Animation Type 5" 5 "Animation Type 4" 4 "Animation Type 3" 3 "Animation Type 2" 2 "Animation Type 1" 1 "Off" 0 "No Action" ;
VAL_ 2155569152 ExtHlStrAssCsStRq 2 "Standard Hold" 1 "Extended Hold" 0 "No Action" ;
VAL_ 2155569152 ColPrSysCustReq 4 "Alert and Brake and Steer" 0 "No Action" 1 "Off" 2 "Alert" 3 "Alert and Brake" ;
VAL_ 2152022016 ASVSC_ReqEnbld 1 "true" 0 "false" ;
VAL_ 2152022016 AudSelctdSrcReq 31 "Unused and Reserved14" 30 "Unused and Reserved13" 29 "Unused and Reserved12" 28 "Unused and Reserved11" 27 "Unused and Reserved10" 26 "Unused and Reserved9" 25 "Unused and Reserved8" 24 "Unused and Reserved7" 23 "Unused and Reserved6" 22 "Unused and Reserved5" 21 "Unused and Reserved4" 20 "Unused and Reserved3" 19 "Unused and Reserved2" 18 "Unused and Reserved1" 17 "Android Auto" 16 "Apple CarPlay" 15 "SD" 14 "USB" 13 "RSI2" 12 "RSI1" 11 "Internet App Audio" 10 "LVM Stereo Audio" 9 "Audio Disk Player" 8 "AUX" 7 "Bluetooth" 6 "IPOD" 5 "MediaPlayer" 4 "DAB" 3 "XM" 2 "FM" 1 "AM" 0 "No Action" ;
VAL_ 2152022016 InfMdStRsp 7 "Data Unavailable" 6 "Cancel Request" 5 "OTA Transfer Failed" 4 "Data Transfer Failed" 3 "Data Transfer Complete" 2 "Not Ready" 1 "Ready" 0 "No Action" ;
VAL_ 2151989248 InfMdStReq 7 "Data Unavailable" 6 "Cancel Request" 5 "OTA Transfer Failed" 4 "Data Transfer Failed" 3 "Data Transfer Complete" 2 "Not Ready" 1 "Ready" 0 "No Action" ;
VAL_ 2154708992 ASS2AudSrcStatCode 5 "Producing Audio" 4 "Producing Silence" 3 "Reserved" 2 "Audio Not Available" 1 "Audio Available" 0 "Device Present" ;
VAL_ 2154708992 ASS2AudSrcChType 4 "Mono Emergency" 3 "Mixed" 2 "Stereo" 1 "Mono" 0 "No Action" ;
VAL_ 2154708992 ASS2AudSrcType 28 "Phone" 24 "Sat. Digital Audio Receiver System" 20 "Digital Audio Broadcast" 16 "Remote CD Changer" 12 "Remote Digital Video Disk" 8 "Auxiliary Device" 1 "Television Tuner" ;
VAL_ 2149875712 DCCnvStblznErrIO 1 "true" 0 "false" ;
VAL_ 2149875712 BattStOfChrgLowIO 1 "true" 0 "false" ;
VAL_ 2149875712 IntlgntBattSnsFldIO 1 "true" 0 "false" ;
VAL_ 2149875712 BatSOCV 1 "Invalid" 0 "Valid" ;
VAL_ 2149875712 EnrgMgtLdShdRq 4 "Load Shed Level 4" 3 "Load Shed Level 3" 2 "Load Shed Level 2" 1 "Load Shed Level 1" 0 "No Load Shedding" ;
VAL_ 2149875712 SrvBattChrgSysIO 1 "true" 0 "false" ;
VAL_ 2149875712 BattStOfChrgCrtyLow 1 "true" 0 "false" ;
VAL_ 2149875712 BatSaverIO 1 "true" 0 "false" ;
VAL_ 2149875712 BattVltIRq 3 "Battery Voltage Very Low" 2 "Battery Voltage High" 1 "Battery Voltage Low" 0 "Battery Voltage OK" ;
VAL_ 2149875712 BatVltV 1 "Invalid" 0 "Valid" ;
VAL_ 2158911488 ODDMC_ReqType 0 "Subscribe: FU sends DynData back and then on change) " 1 "Unsubscribe: cancel previous Subscribe" ;
VAL_ 2158911488 ODDMC_DispMID 128 "Reserved" 64 "Reserved" 32 "OTIM" 16 "RearDisplayTwo" 8 "RearDisplayOne" 4 "AuxIP" 2 "CenterStack" 1 "IPC" ;
VAL_ 2158911488 ODDMC_DataID2Vld 1 "true" 0 "false" ;
VAL_ 2158911488 ODDMC_DataID3Vld 1 "true" 0 "false" ;
VAL_ 2158911488 ODDMC_DataID4Vld 1 "true" 0 "false" ;
VAL_ 2158911488 ODDMC_DataID5Vld 1 "true" 0 "false" ;
VAL_ 2158878720 ODDLC_WrpArnd 1 "true" 0 "false" ;
VAL_ 2158878720 ODDLC_ReqType 0 "Subscribe: FU sends DynData back and then on change) " 1 "Unsubscribe: cancel previous Subscribe" ;
VAL_ 2158878720 ODDLC_ReqDir 1 "true" 0 "false" ;
VAL_ 2158878720 ODDLC_DspMID 128 "Reserved" 64 "Reserved" 32 "OTIM" 16 "RearDisplayTwo" 8 "RearDisplayOne" 4 "AuxIP" 2 "CenterStack" 1 "IPC" ;
VAL_ 2158878720 ODDLC_BckgndFlag 1 "Background response" 0 "Immediate response required" ;
VAL_ 2158845952 ODIAC_DspMID 128 "Reserved" 64 "Reserved" 32 "OTIM" 16 "RearDisplayTwo" 8 "RearDisplayOne" 4 "AuxIP" 2 "CenterStack" 1 "IPC" ;
VAL_ 2158845952 ODIAC_DaTy 21 "Bitmap" 20 "DecimalShort" 19 "HoursOfDay" 18 "Character" 17 "Fuel Consumption Inverted" 16 "Fuel Consumption" 15 "Pressure" 14 "Temperature" 13 "Volume" 12 "DistanceShort" 11 "DistanceLong" 10 "BitmapId" 9 "TextId" 8 "Pictogram" 7 "List " 6 "Date" 5 "Time " 4 "Decimal" 3 "EnumerationValue" 2 "Integer" 1 "String" 0 "Speed" ;
VAL_ 2151079936 PDIMPrsnt 1 "true" 0 "false" ;
VAL_ 2153824256 TeenDrvAccelLimIO 1 "true" 0 "false" ;
VAL_ 2153824256 TeenDrvAct 1 "true" 0 "false" ;
VAL_ 2153824256 TeenDrvRsp 0 "No Action" 1 "Teen PIN Verified" 2 "Teen PIN Updated" 3 "Teen PIN Mismatch" 4 "Teen Key Set Complete" 5 "Teen Key Clear Complete" 6 "Key Not Present" 7 "Key Detected as Teen Key" 8 "Key Detected as NOT Teen Key" ;
VAL_ 2153824256 TeenDrvFtrAvl 1 "true" 0 "false" ;
VAL_ 2153824256 TeenDrvPINStrd 1 "true" 0 "false" ;
VAL_ 2153824256 TnDrvGapAdjUnbIO 1 "true" 0 "false" ;
VAL_ 2153824256 TnDrvOvrSpdIO 1 "true" 0 "false" ;
VAL_ 2153824256 TDOvSpdWrnCstStAvl 1 "true" 0 "false" ;
VAL_ 2153824256 TDOWCCSV_CrStat 0 "No Action" 1 "Off" 2 "On" ;
VAL_ 2153824256 TnDrvSpdLmtCstStAvl 1 "true" 0 "false" ;
VAL_ 2153824256 TDSLCCSV_SpLmtStat 0 "No Action" 1 "Off" 2 "On" ;
VAL_ 2151907328 StrgWhlUnit1SwStat 15 "Function #F" 14 "Function #E" 13 "Function #D" 12 "Function #C" 11 "Function #B" 10 "Function #A" 9 "Function #9" 8 "Function #8" 7 "Function #7" 6 "Function #6" 5 "Function #5" 4 "Function #4" 3 "Function #3" 2 "Function #2" 1 "Function #1" 0 "No Activation" ;
VAL_ 2151907328 StrgWhlUnit2SwStat 15 "Function #F" 14 "Function #E" 13 "Function #D" 12 "Function #C" 11 "Function #B" 10 "Function #A" 9 "Function #9" 8 "Function #8" 7 "Function #7" 6 "Function #6" 5 "Function #5" 4 "Function #4" 3 "Function #3" 2 "Function #2" 1 "Function #1" 0 "No Activation" ;
SIG_GROUP_ 2150252544 EngyConsmpHistGrph 1 : ECHG_YAxisMaxVal ECHG_XAxisTkMrkIntvl ECHG_Column10 ECHG_Column09 ECHG_Column08 ECHG_Column07 ECHG_Column06 ECHG_Column05 ECHG_Column04 ECHG_Column03 ECHG_Column02 ECHG_Column01 ECHG_EngyCnsmdAvg ECHG_MeasUnit;
SIG_GROUP_ 2150375424 LBCCstmrDaRstReq 1 : LBCCDRR_ClrStrdPosReq LBCCDRR_PosNum;
SIG_GROUP_ 2151809024 DrvCycElecEngyCnsmd 1 : DCEEC_EngyPct4 DCEEC_EngyPct3 DCEEC_EngyPct2 DCEEC_EngyPct1;
SIG_GROUP_ 2151792640 RrCrsTrfAltRgtIndCtrl 1 : RCTARIC_Indctr1Act RCTARIC_IndReq;
SIG_GROUP_ 2151776256 RrCrsTrfAltLftIndCtrl 1 : RCTALIC_Indctr1Act RCTALIC_IndReq;
SIG_GROUP_ 2155913216 PedFrndlyAlrtStat 1 : PFAS_SrvPedAlrtIO PFAS_PFASysStat PFAS_PFASndVolCtrl PFAS_PFASndGenEn PFAS_PFARevSnd PFAS_PFAFwdSnd PFAS_PFACrsOvrSpd;
SIG_GROUP_ 2156265472 HVBatTmBsRtChrgStReq 1 : HVBTBRCSR_RtChSlStReq HVBTBRCSR_RtChSlRtStReq HVBTBRCSR_RtChSsnStReq HVBTBRCSR_RtChMHStReq HVBTBRCSR_RtChHStReq HVBTBRCSR_RtChDStReq HVBTBRCSR_RtChSlTbRwReq;
SIG_GROUP_ 2156265472 HVBatTmBsDlChStReq 1 : HVBTBDCSRQ_DlChSlStReq HVBTBDCSRQ_DlChSsnStReq HVBTBDCSRQ_DlChMHStReq HVBTBDCSRQ_DlChHStReq HVBTBDCSRQ_DlChDStReq;
SIG_GROUP_ 2149793792 VhlAhdDstIndReq 1 : VADIR_IndLvl VADIR_FlwTme VADIR_FlwDst;
SIG_GROUP_ 2152022016 AudSysVolSetCtrl 1 : ASVSC_ReqEnbld ASVSC_VolReq;
SIG_GROUP_ 2154708992 AudSrcStat2 1 : ASS2AudSrcStatCode ASS2AudSrcChType ASS2AudSrcType;
SIG_GROUP_ 2158911488 ODIDynDataMltRq_CntrStck 1 : ODDMC_ReqType ODDMC_DispMID ODDMC_DataID2Vld ODDMC_DataID2 ODDMC_DataID3Vld ODDMC_DataID3 ODDMC_DataID1 ODDMC_DataID4Vld ODDMC_DataID4 ODDMC_DataID5Vld ODDMC_DataID5 ODDMC_FUCID;
SIG_GROUP_ 2158878720 ODIDynDataLstRq_CntrStck 1 : ODDLC_SubIdReqM ODDLC_WrpArnd ODDLC_ReqType ODDLC_ReqDir ODDLC_NmEntries ODDLC_Idx ODDLC_FUCID ODDLC_DspMID ODDLC_DataId ODDLC_BckgndFlag;
SIG_GROUP_ 2158845952 ODIActn_CntrStck 1 : ODIAC_FUCID ODIAC_DspMID ODIAC_DaTy ODIAC_ActnVal ODIAC_ActnID;
SIG_GROUP_ 2153824256 TDOvSpdWrnCstCrStVl 1 : TDOWCCSV_CrStVl TDOWCCSV_CrStat;
SIG_GROUP_ 2153824256 TnDrvSpdLmtCstCrStVl 1 : TDSLCCSV_SpLmtStat TDSLCCSV_SpLmDisVl;
SIG_GROUP_ 2152497152 PerfDatRecRltmInfo 1 : PDRRI_LpDiffTm10s PDRRI_LpDiffTmSecs PDRRI_CrLpTm10sSec PDRRI_CrLpTmSecs PDRRI_CrLpTmMins;
SIG_GROUP_ 2152480768 PerfDatRecLstLpInfo 1 : PDRLLI_LstLpTmSecs PDRLLI_LstLpTmMins PDRLLI_LstLpTm100s;
SIG_GROUP_ 2152480768 PerfDatRecBstLpInfo 1 : PDRBLI_BstLpTmSecs PDRBLI_BstLpTmMins PDRBLI_BstLpTm100s;
